VERSION "dbc-export 1 2025.20.8"

NS_ :

BS_:

BU_: ADSP APB APP APS APSB BB BMS CC CMP CMPD CP DAS DI DIF DIR DPB EPAS3P EPAS3S EPASTP EPASTS EPBL EPBR ESP GTW HVP IBST ICR IDB OCS1P ODIN PARK PCS PLG PM PMF PMR PTC RADC RCM RCM2 RCU SCCM SDCR TAS TCU TPMS TRCM UDS UI UIS UMC USM VC VCFRONT VCLEFT VCRIGHT VCSEC

BO_ 62 GTW_alertMatrix: 8 GTW
 SG_ GTW_matrixIndex M : 0|4@1+ (1,0) [0|15] "" Vector__XXX
 SG_ GTW_w001_canEthTxQueue m0 : 4|1@1+ (1,0) [0|1] "" Vector__XXX
 SG_ GTW_w002_taskError m0 : 5|1@1+ (1,0) [0|1] "" Vector__XXX
 SG_ GTW_w003_logWriteRecord m0 : 6|1@1+ (1,0) [0|1] "" Vector__XXX
 SG_ GTW_w004_mallocHook m0 : 7|1@1+ (1,0) [0|1] "" Vector__XXX
 SG_ GTW_w005_stackOverflowHook m0 : 8|1@1+ (1,0) [0|1] "" Vector__XXX
 SG_ GTW_w006_ifTxOutputFull m0 : 9|1@1+ (1,0) [0|1] "" Vector__XXX
 SG_ GTW_w007_ifRxBufError m0 : 10|1@1+ (1,0) [0|1] "" Vector__XXX
 SG_ GTW_w008_ifPbufAllocError m0 : 11|1@1+ (1,0) [0|1] "" Vector__XXX
 SG_ GTW_w009_lateTask m0 : 12|1@1+ (1,0) [0|1] "" Vector__XXX
 SG_ GTW_w010_wdTaskCount m0 : 13|1@1+ (1,0) [0|1] "" Vector__XXX
 SG_ GTW_w011_cancoreWatchdog m0 : 14|1@1+ (1,0) [0|1] "" Vector__XXX
 SG_ GTW_w012_maincoreWatchdog m0 : 15|1@1+ (1,0) [0|1] "" Vector__XXX
 SG_ GTW_w014_APSversionMismatch m0 : 17|1@1+ (1,0) [0|1] "" Vector__XXX
 SG_ GTW_w015_DIFversionMismatch m0 : 18|1@1+ (1,0) [0|1] "" Vector__XXX
 SG_ GTW_w016_BLEEPCENTERversionMisma m0 : 19|1@1+ (1,0) [0|1] "" Vector__XXX
 SG_ GTW_w017_BMSversionMismatch m0 : 20|1@1+ (1,0) [0|1] "" Vector__XXX
 SG_ GTW_w018_CMPversionMismatch m0 : 21|1@1+ (1,0) [0|1] "" Vector__XXX
 SG_ GTW_w019_CPversionMismatch m0 : 22|1@1+ (1,0) [0|1] "" Vector__XXX
 SG_ GTW_w020_DIRversionMismatch m0 : 23|1@1+ (1,0) [0|1] "" Vector__XXX
 SG_ GTW_w021_EPAS3PversionMismatch m0 : 24|1@1+ (1,0) [0|1] "" Vector__XXX
 SG_ GTW_w022_EPBLversionMismatch m0 : 25|1@1+ (1,0) [0|1] "" Vector__XXX
 SG_ GTW_w023_EPBRversionMismatch m0 : 26|1@1+ (1,0) [0|1] "" Vector__XXX
 SG_ GTW_w024_ESPversionMismatch m0 : 27|1@1+ (1,0) [0|1] "" Vector__XXX
 SG_ GTW_w025_ESPCALversionMismatch m0 : 28|1@1+ (1,0) [0|1] "" Vector__XXX
 SG_ GTW_w026_GTWversionMismatch m0 : 29|1@1+ (1,0) [0|1] "" Vector__XXX
 SG_ GTW_w027_HVPversionMismatch m0 : 30|1@1+ (1,0) [0|1] "" Vector__XXX
 SG_ GTW_w028_IBSTversionMismatch m0 : 31|1@1+ (1,0) [0|1] "" Vector__XXX
 SG_ GTW_w029_IBSTCALversionMismatch m0 : 32|1@1+ (1,0) [0|1] "" Vector__XXX
 SG_ GTW_w030_OCS1PversionMismatch m0 : 33|1@1+ (1,0) [0|1] "" Vector__XXX
 SG_ GTW_w031_PARKversionMismatch m0 : 34|1@1+ (1,0) [0|1] "" Vector__XXX
 SG_ GTW_w032_PCSversionMismatch m0 : 35|1@1+ (1,0) [0|1] "" Vector__XXX
 SG_ GTW_w033_PCSCPU2versionMismatch m0 : 36|1@1+ (1,0) [0|1] "" Vector__XXX
 SG_ GTW_w034_PMRversionMismatch m0 : 37|1@1+ (1,0) [0|1] "" Vector__XXX
 SG_ GTW_w035_PMFversionMismatch m0 : 38|1@1+ (1,0) [0|1] "" Vector__XXX
 SG_ GTW_w036_PTCversionMismatch m0 : 39|1@1+ (1,0) [0|1] "" Vector__XXX
 SG_ GTW_w037_RADCversionMismatch m0 : 40|1@1+ (1,0) [0|1] "" Vector__XXX
 SG_ GTW_w038_RCMversionMismatch m0 : 41|1@1+ (1,0) [0|1] "" Vector__XXX
 SG_ GTW_w039_RCMCALversionMismatch m0 : 42|1@1+ (1,0) [0|1] "" Vector__XXX
 SG_ GTW_w040_SCCMversionMismatch m0 : 43|1@1+ (1,0) [0|1] "" Vector__XXX
 SG_ GTW_w041_VCSECversionMismatch m0 : 44|1@1+ (1,0) [0|1] "" Vector__XXX
 SG_ GTW_w042_TASversionMismatch m0 : 45|1@1+ (1,0) [0|1] "" Vector__XXX
 SG_ GTW_w043_THSversionMismatch m0 : 46|1@1+ (1,0) [0|1] "" Vector__XXX
 SG_ GTW_w045_VCFRONTversionMismatch m0 : 48|1@1+ (1,0) [0|1] "" Vector__XXX
 SG_ GTW_w046_VCLEFTversionMismatch m0 : 49|1@1+ (1,0) [0|1] "" Vector__XXX
 SG_ GTW_w047_VCRIGHTversionMismatch m0 : 50|1@1+ (1,0) [0|1] "" Vector__XXX
 SG_ GTW_w048_EPAS3SversionMismatch m0 : 51|1@1+ (1,0) [0|1] "" Vector__XXX
 SG_ GTW_w049_corruptedManifest m0 : 52|1@1+ (1,0) [0|1] "" Vector__XXX
 SG_ GTW_w050_sdCardInitFailure m0 : 53|1@1+ (1,0) [0|1] "" Vector__XXX
 SG_ GTW_w051_sdCardFileSystemFailure m0 : 54|1@1+ (1,0) [0|1] "" Vector__XXX
 SG_ GTW_w052_ifTxSpans m0 : 55|1@1+ (1,0) [0|1] "" Vector__XXX
 SG_ GTW_w053_busSleepFailure m0 : 56|1@1+ (1,0) [0|1] "" Vector__XXX
 SG_ GTW_w054_OPCRversionMismatch m0 : 57|1@1+ (1,0) [0|1] "" Vector__XXX
 SG_ GTW_w055_OPCFversionMismatch m0 : 58|1@1+ (1,0) [0|1] "" Vector__XXX
 SG_ GTW_w057_i2cFailure m0 : 60|1@1+ (1,0) [0|1] "" Vector__XXX
 SG_ GTW_w058_rtcAlarmFailure m0 : 61|1@1+ (1,0) [0|1] "" Vector__XXX
 SG_ GTW_w059_inFactoryMode m0 : 62|1@1+ (1,0) [0|1] "" Vector__XXX
 SG_ GTW_w060_unFused m0 : 63|1@1+ (1,0) [0|1] "" Vector__XXX
 SG_ GTW_w061_bmpSleepFailure m1 : 4|1@1+ (1,0) [0|1] "" Vector__XXX
 SG_ GTW_w062_bmpWatchdog m1 : 5|1@1+ (1,0) [0|1] "" Vector__XXX
 SG_ GTW_w063_VEH_canFault m1 : 6|1@1+ (1,0) [0|1] "" Vector__XXX
 SG_ GTW_w064_CH_canFault m1 : 7|1@1+ (1,0) [0|1] "" Vector__XXX
 SG_ GTW_w065_PARTY_canFault m1 : 8|1@1+ (1,0) [0|1] "" Vector__XXX
 SG_ GTW_w066_exception m1 : 9|1@1+ (1,0) [0|1] "" Vector__XXX
 SG_ GTW_w067_tcpDebug m1 : 10|1@1+ (1,0) [0|1] "" Vector__XXX
 SG_ GTW_w068_prodKeyMissing m1 : 11|1@1+ (1,0) [0|1] "" Vector__XXX
 SG_ GTW_w069_diskioErr m1 : 12|1@1+ (1,0) [0|1] "" Vector__XXX
 SG_ GTW_w070_hrlDump m1 : 13|1@1+ (1,0) [0|1] "" Vector__XXX
 SG_ GTW_w071_hrlTrigger m1 : 14|1@1+ (1,0) [0|1] "" Vector__XXX
 SG_ GTW_w072_updateFailure m1 : 15|1@1+ (1,0) [0|1] "" Vector__XXX
 SG_ GTW_w073_steeringWheelReset m1 : 16|1@1+ (1,0) [0|1] "" Vector__XXX
 SG_ GTW_w074_epas3pMIA m1 : 17|1@1+ (1,0) [0|1] "" Vector__XXX
 SG_ GTW_w075_epas3sMIA m1 : 18|1@1+ (1,0) [0|1] "" Vector__XXX
 SG_ GTW_w076_ethInterfaceReset m1 : 19|1@1+ (1,0) [0|1] "" Vector__XXX
 SG_ GTW_w077_bmpPmicError m1 : 20|1@1+ (1,0) [0|1] "" Vector__XXX
 SG_ GTW_w078_VEHbusOverloaded m1 : 21|1@1+ (1,0) [0|1] "" Vector__XXX
 SG_ GTW_w079_PARTYbusOverloaded m1 : 22|1@1+ (1,0) [0|1] "" Vector__XXX
 SG_ GTW_w080_CHbusOverloaded m1 : 23|1@1+ (1,0) [0|1] "" Vector__XXX
 SG_ GTW_w081_udsMessageRejected m1 : 24|1@1+ (1,0) [0|1] "" Vector__XXX
 SG_ GTW_w082_sdCardBSCorrupted m1 : 25|1@1+ (1,0) [0|1] "" Vector__XXX
 SG_ GTW_w083_udsMsgDroppedByTcpStack m1 : 26|1@1+ (1,0) [0|1] "" Vector__XXX
 SG_ GTW_w084_canFrameDropped m1 : 27|1@1+ (1,0) [0|1] "" Vector__XXX
 SG_ GTW_w086_ocu m1 : 29|1@1+ (1,0) [0|1] "" Vector__XXX
 SG_ GTW_w087_ocuInProgress m1 : 30|1@1+ (1,0) [0|1] "" Vector__XXX
 SG_ GTW_w088_sdCardInvReqParallel m1 : 31|1@1+ (1,0) [0|1] "" Vector__XXX
 SG_ GTW_w089_sdCardWatchdog m1 : 32|1@1+ (1,0) [0|1] "" Vector__XXX
 SG_ GTW_w090_ocuFailed m1 : 33|1@1+ (1,0) [0|1] "" Vector__XXX
 SG_ GTW_w091_lowStack m1 : 34|1@1+ (1,0) [0|1] "" Vector__XXX
 SG_ GTW_w092_sdCardInvReqZero m1 : 35|1@1+ (1,0) [0|1] "" Vector__XXX
 SG_ GTW_w093_sdCardInvReqOverflowBas m1 : 36|1@1+ (1,0) [0|1] "" Vector__XXX
 SG_ GTW_w094_sdCardInvReqOverflowCou m1 : 37|1@1+ (1,0) [0|1] "" Vector__XXX
 SG_ GTW_w095_sdCardFull m1 : 38|1@1+ (1,0) [0|1] "" Vector__XXX
 SG_ GTW_w096_sdCardFatCorrupted m1 : 39|1@1+ (1,0) [0|1] "" Vector__XXX
 SG_ GTW_w097_HCMLversionMismatch m1 : 40|1@1+ (1,0) [0|1] "" Vector__XXX
 SG_ GTW_w098_HCMRversionMismatch m1 : 41|1@1+ (1,0) [0|1] "" Vector__XXX
 SG_ GTW_w099_SWCversionMismatch m1 : 42|1@1+ (1,0) [0|1] "" Vector__XXX
 SG_ GTW_w100_CBCversionMismatch m1 : 43|1@1+ (1,0) [0|1] "" Vector__XXX
 SG_ GTW_w101_switchWatchdog m1 : 44|1@1+ (1,0) [0|1] "" Vector__XXX
 SG_ GTW_w103_sdCardFormatted m1 : 46|1@1+ (1,0) [0|1] "" Vector__XXX
 SG_ GTW_w104_sdCardDriverArgCorrupte m1 : 47|1@1+ (1,0) [0|1] "" Vector__XXX
 SG_ GTW_w105_eBuckConfigured m1 : 48|1@1+ (1,0) [0|1] "" Vector__XXX
 SG_ GTW_w106_BLEEPLEFTversionMismatc m1 : 49|1@1+ (1,0) [0|1] "" Vector__XXX
 SG_ GTW_w107_BLEEPRIGHTversionMismat m1 : 50|1@1+ (1,0) [0|1] "" Vector__XXX
 SG_ GTW_w108_BLEEPREARversionMismatc m1 : 51|1@1+ (1,0) [0|1] "" Vector__XXX
 SG_ GTW_w109_failedToStartUpdater m1 : 52|1@1+ (1,0) [0|1] "" Vector__XXX
 SG_ GTW_w110_readMdioFailed m1 : 53|1@1+ (1,0) [0|1] "" Vector__XXX
 SG_ GTW_w111_writeMdioFailed m1 : 54|1@1+ (1,0) [0|1] "" Vector__XXX
 SG_ GTW_w112_z4bDisabled m1 : 55|1@1+ (1,0) [0|1] "" Vector__XXX
 SG_ GTW_w113_unrecognizedCanMessage m1 : 56|1@1+ (1,0) [0|1] "" Vector__XXX
 SG_ GTW_w114_updtRetried m1 : 57|1@1+ (1,0) [0|1] "" Vector__XXX
 SG_ GTW_w115_hrlEventFileAvail m1 : 58|1@1+ (1,0) [0|1] "" Vector__XXX
 SG_ GTW_w116_switchInitFailed m1 : 59|1@1+ (1,0) [0|1] "" Vector__XXX
 SG_ GTW_w117_unexpectedDestructiveRe m1 : 60|1@1+ (1,0) [0|1] "" Vector__XXX
 SG_ GTW_w118_unexpectedFunctionalRes m1 : 61|1@1+ (1,0) [0|1] "" Vector__XXX
 SG_ GTW_w120_switchUnlocked m1 : 63|1@1+ (1,0) [0|1] "" Vector__XXX
 SG_ GTW_w122_BDY_canFault m2 : 5|1@1+ (1,0) [0|1] "" Vector__XXX
 SG_ GTW_w123_BDYbusOverloaded m2 : 6|1@1+ (1,0) [0|1] "" Vector__XXX
 SG_ GTW_w125_switchReplayUnlocked m2 : 8|1@1+ (1,0) [0|1] "" Vector__XXX
 SG_ GTW_w127_noFilePointersAvailable m2 : 10|1@1+ (1,0) [0|1] "" Vector__XXX
 SG_ GTW_w129_ICRversionMismatch m2 : 12|1@1+ (1,0) [0|1] "" Vector__XXX
 SG_ GTW_w133_adspFaultDetected m2 : 16|1@1+ (1,0) [0|1] "" Vector__XXX
 SG_ GTW_w134_disableFeatureFailed m2 : 17|1@1+ (1,0) [0|1] "" Vector__XXX
 SG_ GTW_w135_canLogQueueFull m2 : 18|1@1+ (1,0) [0|1] "" Vector__XXX
 SG_ GTW_w136_hrlGameModeFileAvail m2 : 19|1@1+ (1,0) [0|1] "" Vector__XXX
 SG_ GTW_w137_lowHeap m2 : 20|1@1+ (1,0) [0|1] "" Vector__XXX
 SG_ GTW_w138_sdCardEndOfLife m2 : 21|1@1+ (1,0) [0|1] "" Vector__XXX
 SG_ GTW_w139_CMPDversionMismatch m2 : 22|1@1+ (1,0) [0|1] "" Vector__XXX
 SG_ GTW_w140_cancoreHeartbeat m2 : 23|1@1+ (1,0) [0|1] "" Vector__XXX
 SG_ GTW_w141_teleCANETHis m2 : 24|1@1+ (1,0) [0|1] "" Vector__XXX
 SG_ GTW_w143_possibleCanWakeIssue m2 : 26|1@1+ (1,0) [0|1] "" Vector__XXX
 SG_ GTW_w144_hrlStateMachine m2 : 27|1@1+ (1,0) [0|1] "" Vector__XXX
 SG_ GTW_w145_carConfigsNotWritten m2 : 28|1@1+ (1,0) [0|1] "" Vector__XXX
 SG_ GTW_w146_performancePackageMisma m2 : 29|1@1+ (1,0) [0|1] "" Vector__XXX
 SG_ GTW_w147_updateAbortFor12v m2 : 30|1@1+ (1,0) [0|1] "" Vector__XXX
 SG_ GTW_w149_rtcTimeSetInPast m2 : 32|1@1+ (1,0) [0|1] "" Vector__XXX
 SG_ GTW_w150_HCM3LversionMismatch m2 : 33|1@1+ (1,0) [0|1] "" Vector__XXX
 SG_ GTW_w151_HCM3RversionMismatch m2 : 34|1@1+ (1,0) [0|1] "" Vector__XXX
 SG_ GTW_w153_externalRtcAlarmFailure m2 : 36|1@1+ (1,0) [0|1] "" Vector__XXX
 SG_ GTW_w155_PMversionMismatch m2 : 38|1@1+ (1,0) [0|1] "" Vector__XXX
 SG_ GTW_w165_USMversionMismatch m2 : 48|1@1+ (1,0) [0|1] "" Vector__XXX
 SG_ GTW_w166_nErrCanFaultVeh m2 : 49|1@1+ (1,0) [0|1] "" Vector__XXX
 SG_ GTW_w167_nErrCanFaultCh m2 : 50|1@1+ (1,0) [0|1] "" Vector__XXX
 SG_ GTW_w168_nErrCanFaultParty m2 : 51|1@1+ (1,0) [0|1] "" Vector__XXX
 SG_ GTW_w169_TPMSsoftWarnFrontLeft m2 : 52|1@1+ (1,0) [0|1] "" Vector__XXX
 SG_ GTW_w170_TPMSsoftWarnFrontRight m2 : 53|1@1+ (1,0) [0|1] "" Vector__XXX
 SG_ GTW_w171_TPMSsoftWarnRearLeft m2 : 54|1@1+ (1,0) [0|1] "" Vector__XXX
 SG_ GTW_w172_TPMSsoftWarnRearRight m2 : 55|1@1+ (1,0) [0|1] "" Vector__XXX
 SG_ GTW_w173_TPMShardWarnFrontLeft m2 : 56|1@1+ (1,0) [0|1] "" Vector__XXX
 SG_ GTW_w174_TPMShardWarnFrontRight m2 : 57|1@1+ (1,0) [0|1] "" Vector__XXX
 SG_ GTW_w175_TPMShardWarnRearLeft m2 : 58|1@1+ (1,0) [0|1] "" Vector__XXX
 SG_ GTW_w176_TPMShardWarnRearRight m2 : 59|1@1+ (1,0) [0|1] "" Vector__XXX
 SG_ GTW_w186_swrPrecaution m3 : 9|1@1+ (1,0) [0|1] "" Vector__XXX
 SG_ GTW_w218_switchOTPIncorrect m3 : 41|1@1+ (1,0) [0|1] "" Vector__XXX
 SG_ GTW_w219_CMPSversionMismatch m3 : 42|1@1+ (1,0) [0|1] "" Vector__XXX
 SG_ GTW_w223_LVBMSversionMismatch m3 : 46|1@1+ (1,0) [0|1] "" Vector__XXX
 SG_ GTW_w224_sdCardUpgradeNeeded m3 : 47|1@1+ (1,0) [0|1] "" Vector__XXX
 SG_ GTW_w225_resetOnSleepWake m3 : 48|1@1+ (1,0) [0|1] "" Vector__XXX
 SG_ GTW_w226_DISPversionMismatch m3 : 49|1@1+ (1,0) [0|1] "" Vector__XXX
 SG_ GTW_w227_DISPTOUCHversionMismatc m3 : 50|1@1+ (1,0) [0|1] "" Vector__XXX
 SG_ GTW_w228_DISPOSDversionMismatch m3 : 51|1@1+ (1,0) [0|1] "" Vector__XXX
 SG_ GTW_w229_displaySoftsetConnectio m3 : 52|1@1+ (1,0) [0|1] "" Vector__XXX
 SG_ GTW_w230_touchInterruptStorm m3 : 53|1@1+ (1,0) [0|1] "" Vector__XXX
 SG_ GTW_w244_SDCRversionMismatch m4 : 7|1@1+ (1,0) [0|1] "" Vector__XXX
 SG_ GTW_w245_apsNotDisabled m4 : 8|1@1+ (1,0) [0|1] "" Vector__XXX
 SG_ GTW_w246_touchcoreHeartbeat m4 : 9|1@1+ (1,0) [0|1] "" Vector__XXX
 SG_ GTW_w255_rtc32KHzWatchdog m4 : 18|1@1+ (1,0) [0|1] "" Vector__XXX
 SG_ GTW_w260_unknownPN m4 : 23|1@1+ (1,0) [0|1] "" Vector__XXX
 SG_ GTW_w261_adspWatchdog m4 : 24|1@1+ (1,0) [0|1] "" Vector__XXX
 SG_ GTW_w262_canLogBlockDropped m4 : 25|1@1+ (1,0) [0|1] "" Vector__XXX
 SG_ GTW_w263_hrlUdpFileAvail m4 : 26|1@1+ (1,0) [0|1] "" Vector__XXX
 SG_ GTW_w264_hrlPseudoFileAvail m4 : 27|1@1+ (1,0) [0|1] "" Vector__XXX
 SG_ GTW_w265_optionFlagsError m4 : 28|1@1+ (1,0) [0|1] "" Vector__XXX
 SG_ GTW_w266_dpp1MIA m4 : 29|1@1+ (1,0) [0|1] "" Vector__XXX
 SG_ GTW_w267_dpp2MIA m4 : 30|1@1+ (1,0) [0|1] "" Vector__XXX
 SG_ GTW_w268_stoMIA m4 : 31|1@1+ (1,0) [0|1] "" Vector__XXX
 SG_ GTW_w273_BLEEPREARLEFTversionMis m4 : 36|1@1+ (1,0) [0|1] "" Vector__XXX
 SG_ GTW_w274_BLEEPREARRIGHTversionMi m4 : 37|1@1+ (1,0) [0|1] "" Vector__XXX
 SG_ GTW_w275_VDDCORE_DrMOS_Fault m4 : 38|1@1+ (1,0) [0|1] "" Vector__XXX
 SG_ GTW_w276_VDDSOC_DrMOS_Fault m4 : 39|1@1+ (1,0) [0|1] "" Vector__XXX
 SG_ GTW_w277_NonRevCDrMOSMitigationF m4 : 40|1@1+ (1,0) [0|1] "" Vector__XXX
 SG_ GTW_w278_ethSwitchCongested m4 : 41|1@1+ (1,0) [0|1] "" Vector__XXX
 SG_ GTW_w279_adspRepeatedWatchdog m4 : 42|1@1+ (1,0) [0|1] "" Vector__XXX
 SG_ GTW_w280_hrlFrameDropped m4 : 43|1@1+ (1,0) [0|1] "" Vector__XXX
 SG_ GTW_w281_likelyMissedPoke m4 : 44|1@1+ (1,0) [0|1] "" Vector__XXX
 SG_ GTW_w282_tcuPhyConfigurationFail m4 : 45|1@1+ (1,0) [0|1] "" Vector__XXX
 SG_ GTW_w309_VCUSBversionMismatch m5 : 12|1@1+ (1,0) [0|1] "" Vector__XXX
 SG_ GTW_w311_canLogQueueFullBeforeFs m5 : 14|1@1+ (1,0) [0|1] "" Vector__XXX
 SG_ GTW_w312_hrlFileIncomplete m5 : 15|1@1+ (1,0) [0|1] "" Vector__XXX
 SG_ GTW_w313_OSDActive m5 : 16|1@1+ (1,0) [0|1] "" Vector__XXX
 SG_ GTW_w314_canLogBlockWriteErr m5 : 17|1@1+ (1,0) [0|1] "" Vector__XXX
 SG_ GTW_w316_sdCardChkdskRepair m5 : 19|1@1+ (1,0) [0|1] "" Vector__XXX
 SG_ GTW_w317_sdCardChkdskRepairFaile m5 : 20|1@1+ (1,0) [0|1] "" Vector__XXX
 SG_ GTW_w322_gestureUnrecognizedFrom m5 : 25|1@1+ (1,0) [0|1] "" Vector__XXX
 SG_ GTW_w323_gestureStartOutOfStrip m5 : 26|1@1+ (1,0) [0|1] "" Vector__XXX
 SG_ GTW_w328_smartShiftDisabled m5 : 31|1@1+ (1,0) [0|1] "" Vector__XXX
 SG_ GTW_w329_FOHMversionMismatch m5 : 32|1@1+ (1,0) [0|1] "" Vector__XXX
 SG_ GTW_w330_SWSLversionMismatch m5 : 33|1@1+ (1,0) [0|1] "" Vector__XXX
 SG_ GTW_w331_SWSRversionMismatch m5 : 34|1@1+ (1,0) [0|1] "" Vector__XXX
 SG_ GTW_w332_unknownDisplayPN m5 : 35|1@1+ (1,0) [0|1] "" Vector__XXX
 SG_ GTW_w334_hrlFolderSpaceLow m5 : 37|1@1+ (1,0) [0|1] "" Vector__XXX
 SG_ GTW_w336_possibleCanTxIssue m5 : 39|1@1+ (1,0) [0|1] "" Vector__XXX
 SG_ GTW_w342_VCBLDCPPversionMismatch m5 : 45|1@1+ (1,0) [0|1] "" Vector__XXX
 SG_ GTW_w348_VCBLDCFversionMismatch m5 : 51|1@1+ (1,0) [0|1] "" Vector__XXX
 SG_ GTW_w349_VCBLDCPBversionMismatch m5 : 52|1@1+ (1,0) [0|1] "" Vector__XXX
 SG_ GTW_w350_mOSDCrcCheck m5 : 53|1@1+ (1,0) [0|1] "" Vector__XXX
 SG_ GTW_w351_sOSDCrcCheck m5 : 54|1@1+ (1,0) [0|1] "" Vector__XXX
 SG_ GTW_w352_mASILStatusCheck m5 : 55|1@1+ (1,0) [0|1] "" Vector__XXX
 SG_ GTW_w353_sASILStatusCheck m5 : 56|1@1+ (1,0) [0|1] "" Vector__XXX
 SG_ GTW_w354_EPASTPversionMismatch m5 : 57|1@1+ (1,0) [0|1] "" Vector__XXX
 SG_ GTW_w355_EPASTSversionMismatch m5 : 58|1@1+ (1,0) [0|1] "" Vector__XXX
 SG_ GTW_w356_touchGPIOStatusCheck m5 : 59|1@1+ (1,0) [0|1] "" Vector__XXX
 SG_ GTW_w358_RGBIPFLversionMismatch m5 : 61|1@1+ (1,0) [0|1] "" Vector__XXX
 SG_ GTW_w359_RGBIPFRversionMismatch m5 : 62|1@1+ (1,0) [0|1] "" Vector__XXX
 SG_ GTW_w360_RGBDOORFLversionMismatc m5 : 63|1@1+ (1,0) [0|1] "" Vector__XXX
 SG_ GTW_w361_RGBDOORRLversionMismatc m6 : 4|1@1+ (1,0) [0|1] "" Vector__XXX
 SG_ GTW_w362_RGBDOORFRversionMismatc m6 : 5|1@1+ (1,0) [0|1] "" Vector__XXX
 SG_ GTW_w363_RGBDOORRRversionMismatc m6 : 6|1@1+ (1,0) [0|1] "" Vector__XXX
 SG_ GTW_w364_BLEEPCRADLEversionMisma m6 : 7|1@1+ (1,0) [0|1] "" Vector__XXX
 SG_ GTW_w366_uiGearRequestMismatch m6 : 9|1@1+ (1,0) [0|1] "" Vector__XXX
 SG_ GTW_w376_blFailedToExecBootImg m6 : 19|1@1+ (1,0) [0|1] "" Vector__XXX
 SG_ GTW_w380_DPBversionMismatch m6 : 23|1@1+ (1,0) [0|1] "" Vector__XXX
 SG_ GTW_w381_DPBCALversionMismatch m6 : 24|1@1+ (1,0) [0|1] "" Vector__XXX
 SG_ GTW_w382_IDBversionMismatch m6 : 25|1@1+ (1,0) [0|1] "" Vector__XXX
 SG_ GTW_w383_IDB1versionMismatch m6 : 26|1@1+ (1,0) [0|1] "" Vector__XXX
 SG_ GTW_w384_IDBCALversionMismatch m6 : 27|1@1+ (1,0) [0|1] "" Vector__XXX
 SG_ GTW_w385_RCUversionMismatch m6 : 28|1@1+ (1,0) [0|1] "" Vector__XXX
 SG_ GTW_w386_RCUCALversionMismatch m6 : 29|1@1+ (1,0) [0|1] "" Vector__XXX
 SG_ GTW_w387_externalRtcReadFailure m6 : 30|1@1+ (1,0) [0|1] "" Vector__XXX
 SG_ GTW_w388_adspWatchdogSkipped m6 : 31|1@1+ (1,0) [0|1] "" Vector__XXX
 SG_ GTW_w389_rcmEventDetected m6 : 32|1@1+ (1,0) [0|1] "" Vector__XXX
 SG_ GTW_w391_adspMacAddrCheckFailed m6 : 34|1@1+ (1,0) [0|1] "" Vector__XXX
 SG_ GTW_w393_osdSramCrcMismatch m6 : 36|1@1+ (1,0) [0|1] "" Vector__XXX
 SG_ GTW_w395_lwipIcmpError m6 : 38|1@1+ (1,0) [0|1] "" Vector__XXX
 SG_ GTW_w396_alreadyInReverse m6 : 39|1@1+ (1,0) [0|1] "" Vector__XXX
 SG_ GTW_w397_alreadyInDrive m6 : 40|1@1+ (1,0) [0|1] "" Vector__XXX
 SG_ GTW_w398_awakeForExtendedTime m6 : 41|1@1+ (1,0) [0|1] "" Vector__XXX
 SG_ GTW_w399_ethIfRxTcpipQueueDrop m6 : 42|1@1+ (1,0) [0|1] "" Vector__XXX
 SG_ GTW_w400_ethlSwitchOTPIncorrect m6 : 43|1@1+ (1,0) [0|1] "" Vector__XXX
 SG_ GTW_w409_unexpectedResetCause m6 : 52|1@1+ (1,0) [0|1] "" Vector__XXX
 SG_ GTW_w410_unexpectedResetCause2 m6 : 53|1@1+ (1,0) [0|1] "" Vector__XXX
 SG_ GTW_w414_socHeldInReset m6 : 57|1@1+ (1,0) [0|1] "" Vector__XXX

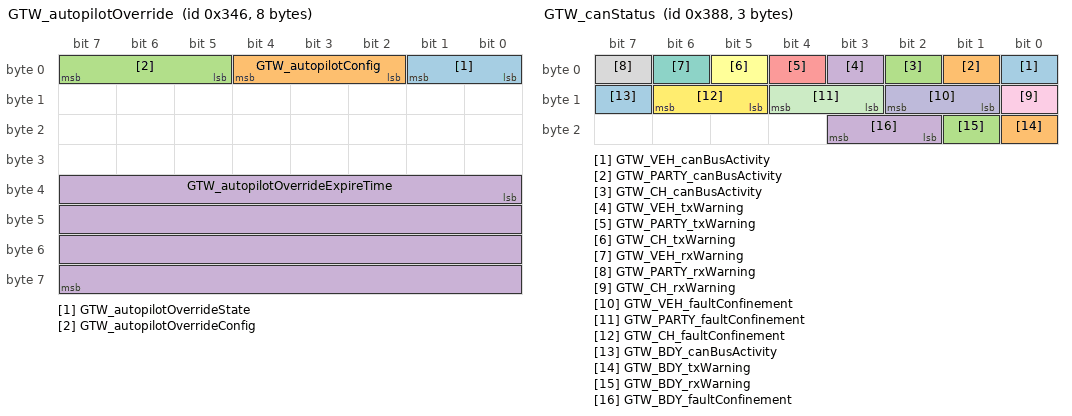
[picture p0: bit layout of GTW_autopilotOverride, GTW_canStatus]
BO_ 838 GTW_autopilotOverride: 8 GTW
 SG_ GTW_autopilotOverrideState : 0|2@1+ (1,0) [0|3] "" Vector__XXX
 SG_ GTW_autopilotConfig : 2|3@1+ (1,0) [0|7] "" Vector__XXX
 SG_ GTW_autopilotOverrideConfig : 5|3@1+ (1,0) [0|7] "" Vector__XXX
 SG_ GTW_autopilotOverrideExpireTime : 32|32@1+ (1,0) [0|4294967295] "" Vector__XXX

BO_ 904 GTW_canStatus: 3 GTW
 SG_ GTW_VEH_canBusActivity : 0|1@1+ (1,0) [0|1] "" Vector__XXX
 SG_ GTW_PARTY_canBusActivity : 1|1@1+ (1,0) [0|1] "" Vector__XXX
 SG_ GTW_CH_canBusActivity : 2|1@1+ (1,0) [0|1] "" Vector__XXX
 SG_ GTW_VEH_txWarning : 3|1@1+ (1,0) [0|1] "" Vector__XXX
 SG_ GTW_PARTY_txWarning : 4|1@1+ (1,0) [0|1] "" Vector__XXX
 SG_ GTW_CH_txWarning : 5|1@1+ (1,0) [0|1] "" Vector__XXX
 SG_ GTW_VEH_rxWarning : 6|1@1+ (1,0) [0|1] "" Vector__XXX
 SG_ GTW_PARTY_rxWarning : 7|1@1+ (1,0) [0|1] "" Vector__XXX
 SG_ GTW_CH_rxWarning : 8|1@1+ (1,0) [0|1] "" Vector__XXX
 SG_ GTW_VEH_faultConfinement : 9|2@1+ (1,0) [0|3] "" Vector__XXX
 SG_ GTW_PARTY_faultConfinement : 11|2@1+ (1,0) [0|3] "" Vector__XXX
 SG_ GTW_CH_faultConfinement : 13|2@1+ (1,0) [0|3] "" Vector__XXX
 SG_ GTW_BDY_canBusActivity : 15|1@1+ (1,0) [0|1] "" Vector__XXX
 SG_ GTW_BDY_txWarning : 16|1@1+ (1,0) [0|1] "" Vector__XXX
 SG_ GTW_BDY_rxWarning : 17|1@1+ (1,0) [0|1] "" Vector__XXX
 SG_ GTW_BDY_faultConfinement : 18|2@1+ (1,0) [0|3] "" Vector__XXX

BO_ 2047 GTW_carConfig: 8 GTW
 SG_ GTW_carConfigMultiplexer M : 0|8@1+ (1,0) [0|255] "" Vector__XXX
 SG_ GTW_deliveryStatus m1 : 8|1@1+ (1,0) [0|1] "" Vector__XXX
 SG_ GTW_cabinPTCHeaterType m1 : 10|1@1+ (1,0) [0|1] "" Vector__XXX
 SG_ GTW_rightHandDrive m1 : 11|1@1+ (1,0) [0|1] "" Vector__XXX
 SG_ GTW_rearLightType m1 : 12|2@1+ (1,0) [0|3] "" Vector__XXX
 SG_ GTW_headlamps m1 : 14|2@1+ (1,0) [0|3] "" Vector__XXX
 SG_ GTW_country m1 : 16|16@1+ (1,0) [0|65535] "" Vector__XXX
 SG_ GTW_tireType m1 : 32|6@1+ (1,0) [0|63] "" Vector__XXX
 SG_ GTW_roofGlassType m1 : 38|2@1+ (1,0) [0|3] "" Vector__XXX
 SG_ GTW_dasHw m1 : 40|3@1+ (1,0) [3|5] "" Vector__XXX
 SG_ GTW_brakeHWType m1 : 43|5@1+ (1,0) [0|31] "" Vector__XXX
 SG_ GTW_restraintsHardwareType m1 : 48|8@1+ (1,0) [0|255] "" Vector__XXX
 SG_ GTW_drivetrainType m1 : 56|4@1+ (1,0) [0|4] "" Vector__XXX
 SG_ GTW_radarHeaterType m1 : 60|3@1+ (1,0) [0|5] "" Vector__XXX
 SG_ GTW_exteriorTrimType m2 : 8|1@1+ (1,0) [0|1] "" Vector__XXX
 SG_ GTW_frontSeatHeaters m2 : 9|1@1+ (1,0) [0|1] "" Vector__XXX
 SG_ GTW_rearSeatHeaters m2 : 10|1@1+ (1,0) [0|1] "" Vector__XXX
 SG_ GTW_eCallAntennaHW m2 : 12|1@1+ (1,0) [0|1] "" Vector__XXX
 SG_ GTW_homelinkType m2 : 13|1@1+ (1,0) [0|1] "" Vector__XXX
 SG_ GTW_vdcType m2 : 14|1@1+ (1,0) [0|1] "" Vector__XXX
 SG_ GTW_memoryMirrors m2 : 17|1@1+ (1,0) [0|1] "" Vector__XXX
 SG_ GTW_powerLiftgateType m2 : 18|2@1+ (1,0) [0|2] "" Vector__XXX
 SG_ GTW_lumbarECUType m2 : 20|4@1+ (1,0) [0|15] "" Vector__XXX
 SG_ GTW_rearSeatHeaterType m2 : 24|2@1+ (1,0) [0|3] "" Vector__XXX
 SG_ GTW_auxParkLamps m2 : 26|2@1+ (1,0) [0|3] "" Vector__XXX
 SG_ GTW_interiorCabinRadarType m2 : 28|1@1+ (1,0) [0|1] "" Vector__XXX
 SG_ GTW_hvacPanelVaneType m2 : 29|1@1+ (1,0) [0|1] "" Vector__XXX
 SG_ GTW_intakeAirFilterType m2 : 30|2@1+ (1,0) [0|2] "" Vector__XXX
 SG_ GTW_eBuckConfig m2 : 32|1@1+ (1,0) [0|1] "" Vector__XXX
 SG_ GTW_steeringHeaterEnabled m2 : 33|1@1+ (1,0) [0|1] "" Vector__XXX
 SG_ GTW_activeHighBeam m2 : 34|1@1+ (1,0) [0|1] "" Vector__XXX
 SG_ GTW_airbagCutoffSwitch m2 : 35|1@1+ (1,0) [0|1] "" Vector__XXX
 SG_ GTW_intrusionSensorType m2 : 36|1@1+ (1,0) [0|1] "" Vector__XXX
 SG_ GTW_spoilerType m2 : 37|1@1+ (1,0) [0|1] "" Vector__XXX
 SG_ GTW_rearFogLamps m2 : 39|1@1+ (1,0) [0|1] "" Vector__XXX
 SG_ GTW_roofType m2 : 40|1@1+ (1,0) [0|1] "" Vector__XXX
 SG_ GTW_thirdRowSeatType m2 : 41|1@1+ (1,0) [0|1] "" Vector__XXX
 SG_ GTW_autopilot m2 : 42|3@1+ (1,0) [0|7] "" Vector__XXX
 SG_ GTW_superchargingAccess m2 : 45|2@1+ (1,0) [0|3] "" Vector__XXX
 SG_ GTW_exteriorColor m2 : 48|5@1+ (1,0) [0|31] "" Vector__XXX
 SG_ GTW_pedestrianWarningSound m2 : 53|2@1+ (1,0) [0|3] "" Vector__XXX
 SG_ GTW_steeringColumnUJointType m2 : 55|1@1+ (1,0) [0|1] "" Vector__XXX
 SG_ GTW_bPillarNFCParam m2 : 56|1@1+ (1,0) [0|1] "" Vector__XXX
 SG_ GTW_interiorLighting m2 : 57|3@1+ (1,0) [0|7] "" Vector__XXX
 SG_ GTW_headlightLevelerType m2 : 60|2@1+ (1,0) [0|3] "" Vector__XXX
 SG_ GTW_numberHVILNodes m2 : 62|2@1+ (1,0) [0|3] "" Vector__XXX
 SG_ GTW_mapRegion m3 : 8|4@1+ (1,0) [0|15] "" Vector__XXX
 SG_ GTW_performancePackage m3 : 12|3@1+ (1,0) [0|7] "" Vector__XXX
 SG_ GTW_chassisType m3 : 18|4@1+ (1,0) [0|15] "" Vector__XXX
 SG_ GTW_airSuspension m3 : 22|2@1+ (1,0) [0|3] "" Vector__XXX
 SG_ GTW_centerConsoleControllerType m3 : 24|2@1+ (1,0) [0|3] "" Vector__XXX
 SG_ GTW_autopilotCameraType m3 : 26|1@1+ (1,0) [0|1] "" Vector__XXX
 SG_ GTW_connectivityPackage m3 : 27|1@1+ (1,0) [0|1] "" Vector__XXX
 SG_ GTW_plcSupportType m3 : 28|2@1+ (1,0) [0|3] "" Vector__XXX
 SG_ GTW_packEnergy m3 : 32|5@1+ (1,0) [0|31] "" Vector__XXX
 SG_ GTW_frontSeatReclinerHardware m3 : 37|2@1+ (1,0) [0|3] "" Vector__XXX
 SG_ GTW_brakeLineSwitchType m3 : 39|1@1+ (1,0) [0|1] "" Vector__XXX
 SG_ GTW_espValveType m3 : 40|2@1+ (1,0) [0|3] "" Vector__XXX
 SG_ GTW_softRange m3 : 42|3@1+ (1,0) [0|7] "" Vector__XXX
 SG_ GTW_refrigerantType m3 : 45|2@1+ (1,0) [0|3] "" Vector__XXX
 SG_ GTW_wheelType m3 : 48|7@1+ (1,0) [0|127] "" Vector__XXX
 SG_ GTW_ptcControlMode m3 : 55|2@1+ (1,0) [0|3] "" Vector__XXX
 SG_ GTW_brakeActuationType m3 : 57|3@1+ (1,0) [0|4] "" Vector__XXX
 SG_ GTW_secondRowSeatType m3 : 60|3@1+ (1,0) [0|7] "" Vector__XXX
 SG_ GTW_secondRowSeatMotorType m3 : 63|1@1+ (1,0) [0|1] "" Vector__XXX
 SG_ GTW_birthday m4 : 8|32@1+ (1,0) [0|4294967295] "" Vector__XXX
 SG_ GTW_eCallEnabled m4 : 40|2@1+ (1,0) [0|3] "" Vector__XXX
 SG_ GTW_parkAssistECUType m4 : 42|2@1+ (1,0) [0|3] "" Vector__XXX
 SG_ GTW_passengerAirbagType m4 : 44|2@1+ (1,0) [0|3] "" Vector__XXX
 SG_ GTW_forwardRadarHw m4 : 46|2@1+ (1,0) [0|2] "" Vector__XXX
 SG_ GTW_frontSeatType m4 : 48|4@1+ (1,0) [0|15] "" Vector__XXX
 SG_ GTW_secondRowDisplayType m4 : 52|1@1+ (1,0) [0|1] "" Vector__XXX
 SG_ GTW_wirelessPhoneChargerType m4 : 53|2@1+ (1,0) [0|3] "" Vector__XXX
 SG_ GTW_ethernetTunerType m4 : 55|2@1+ (1,0) [0|3] "" Vector__XXX
 SG_ GTW_interiorTrimType m4 : 60|4@1+ (1,0) [0|15] "" Vector__XXX
 SG_ GTW_gloveboxUSBType m5 : 8|2@1+ (1,0) [0|3] "" Vector__XXX
 SG_ GTW_coolantPumpType m5 : 10|3@1+ (1,0) [0|7] "" Vector__XXX
 SG_ GTW_epblHwType m5 : 13|4@1+ (1,0) [0|15] "" Vector__XXX
 SG_ GTW_epbrHwType m5 : 17|4@1+ (1,0) [0|15] "" Vector__XXX
 SG_ GTW_blowerMotorType m5 : 21|2@1+ (1,0) [0|3] "" Vector__XXX
 SG_ GTW_rearLeftBLEEndpointParameter m5 : 23|1@1+ (1,0) [0|1] "" Vector__XXX
 SG_ GTW_frontUsbHubType m5 : 27|3@1+ (1,0) [0|5] "" Vector__XXX
 SG_ GTW_superManifoldType m5 : 30|2@1+ (1,0) [0|3] "" Vector__XXX
 SG_ GTW_rcmLocation m5 : 32|1@1+ (1,0) [0|1] "" Vector__XXX
 SG_ GTW_interiorCamFanType m5 : 33|2@1+ (1,0) [0|3] "" Vector__XXX
 SG_ GTW_interiorCamBeautyCoverType m5 : 35|2@1+ (1,0) [0|3] "" Vector__XXX
 SG_ GTW_sirenType m5 : 37|1@1+ (1,0) [0|1] "" Vector__XXX
 SG_ GTW_hornType m5 : 38|1@1+ (1,0) [0|1] "" Vector__XXX
 SG_ GTW_badgingVersion m5 : 40|1@1+ (1,0) [0|1] "" Vector__XXX
 SG_ GTW_steeringColumnMotorType m5 : 42|2@1+ (1,0) [0|3] "" Vector__XXX
 SG_ GTW_refrigACLineType m5 : 48|2@1+ (1,0) [0|3] "" Vector__XXX
 SG_ GTW_refrigFilterType m5 : 50|2@1+ (1,0) [0|3] "" Vector__XXX
 SG_ GTW_diBurnInType m5 : 52|1@1+ (1,0) [0|1] "" Vector__XXX
 SG_ GTW_specialBadgingType m5 : 53|2@1+ (1,0) [0|3] "" Vector__XXX
 SG_ GTW_chassisSubType m5 : 55|2@1+ (1,0) [0|3] "" Vector__XXX
 SG_ GTW_frontSeatVentilationType m5 : 57|1@1+ (1,0) [0|1] "" Vector__XXX
 SG_ GTW_towPackage m5 : 58|2@1+ (1,0) [0|3] "" Vector__XXX
 SG_ GTW_refrigLccType m5 : 60|1@1+ (1,0) [0|1] "" Vector__XXX
 SG_ GTW_caliperColorType m5 : 62|2@1+ (1,0) [0|3] "" Vector__XXX
 SG_ GTW_wiperMotorType m6 : 9|1@1+ (1,0) [0|1] "" Vector__XXX
 SG_ GTW_frontOverheadConsoleType m6 : 10|2@1+ (1,0) [0|3] "" Vector__XXX
 SG_ GTW_shifterType m6 : 12|1@1+ (1,0) [0|1] "" Vector__XXX
 SG_ GTW_compressorType m6 : 13|4@1+ (1,0) [0|15] "" Vector__XXX
 SG_ GTW_twelveVBatteryType m6 : 17|3@1+ (1,0) [0|7] "" Vector__XXX
 SG_ GTW_efuseSWConfig m6 : 20|3@1+ (1,0) [0|7] "" Vector__XXX
 SG_ GTW_tollCollectionModuleType m6 : 23|1@1+ (1,0) [0|1] "" Vector__XXX
 SG_ GTW_bleEndpointUpdateMethod m6 : 24|1@1+ (1,0) [0|1] "" Vector__XXX
 SG_ GTW_steeringWheelControllerType m6 : 25|3@1+ (1,0) [0|7] "" Vector__XXX
 SG_ GTW_frontSeatVentilationEnabled m6 : 28|1@1+ (1,0) [0|1] "" Vector__XXX
 SG_ GTW_gloveboxActuatorType m6 : 29|2@1+ (1,0) [0|3] "" Vector__XXX
 SG_ GTW_epasType m6 : 32|4@1+ (1,0) [0|11] "" Vector__XXX
 SG_ GTW_homologationRegionOverride m6 : 36|2@1+ (1,0) [0|3] "" Vector__XXX
 SG_ GTW_windowCommandsPermissionType m6 : 38|2@1+ (1,0) [0|3] "" Vector__XXX
 SG_ GTW_headlightStepperStallDetectM m6 : 42|1@1+ (1,0) [0|1] "" Vector__XXX
 SG_ GTW_rgbInteriorLightingEnabled m6 : 43|2@1+ (1,0) [0|3] "" Vector__XXX
 SG_ GTW_windshieldWiperHeaterType m6 : 45|1@1+ (1,0) [0|1] "" Vector__XXX
 SG_ GTW_driveInterfaceType m6 : 47|1@1+ (1,0) [0|1] "" Vector__XXX
 SG_ GTW_efficiencyPackage m6 : 49|6@1+ (1,0) [0|63] "" Vector__XXX
 SG_ GTW_visorLightType m6 : 55|1@1+ (1,0) [0|1] "" Vector__XXX
 SG_ GTW_gnssAntennaType m6 : 58|2@1+ (1,0) [0|3] "" Vector__XXX
 SG_ GTW_frontSeatHeatersEnabled m6 : 62|1@1+ (1,0) [0|1] "" Vector__XXX
 SG_ GTW_windshieldWiperHeaterEnabled m6 : 63|1@1+ (1,0) [0|1] "" Vector__XXX
 SG_ GTW_tcuType m7 : 8|1@1+ (1,0) [0|1] "" Vector__XXX
 SG_ GTW_fasciaType m7 : 9|4@1+ (1,0) [0|15] "" Vector__XXX
 SG_ GTW_powerSteeringColumn m7 : 13|1@1+ (1,0) [0|1] "" Vector__XXX
 SG_ GTW_frontSeatHeaterType m7 : 14|1@1+ (1,0) [0|1] "" Vector__XXX
 SG_ GTW_softPerformanceLimit m7 : 15|4@1+ (1,0) [0|15] "" Vector__XXX
 SG_ GTW_alcoholInterlockType m7 : 22|1@1+ (1,0) [0|1] "" Vector__XXX
 SG_ GTW_immersiveAudio m7 : 23|2@1+ (1,0) [0|3] "" Vector__XXX
 SG_ GTW_passengerOccupancySensorType m7 : 26|3@1+ (1,0) [0|7] "" Vector__XXX
 SG_ GTW_packPerformanceDeviation m7 : 30|3@1+ (1,0) [0|7] "" Vector__XXX
 SG_ GTW_frontFogLamps m7 : 35|1@1+ (1,0) [0|1] "" Vector__XXX
 SG_ GTW_driverOccupancySensorType m7 : 36|1@1+ (1,0) [0|1] "" Vector__XXX
 SG_ GTW_audioType m7 : 37|3@1+ (1,0) [0|7] "" Vector__XXX
 SG_ GTW_occupancyClassificationFeatu m7 : 42|1@1+ (1,0) [0|1] "" Vector__XXX
 SG_ GTW_domeLightType m7 : 47|2@1+ (1,0) [0|3] "" Vector__XXX
 SG_ GTW_tpmsType m7 : 49|2@1+ (1,0) [0|3] "" Vector__XXX
 SG_ GTW_authenticationEndpointLayout m7 : 52|3@1+ (1,0) [0|6] "" Vector__XXX
 SG_ GTW_socSleepOverride m7 : 57|2@1+ (1,0) [0|3] "" Vector__XXX
 SG_ GTW_r79BehaviorOverride m7 : 59|1@1+ (1,0) [0|1] "" Vector__XXX
 SG_ GTW_steeringHeaterType m7 : 60|3@1+ (1,0) [0|7] "" Vector__XXX
 SG_ GTW_sohRegulatoryStatus m8 : 10|1@1+ (1,0) [0|1] "" Vector__XXX
 SG_ GTW_m3yBusArchitecture m8 : 17|2@1+ (1,0) [0|3] "" Vector__XXX
 SG_ GTW_blindSpotIndicatorLightType m8 : 20|1@1+ (1,0) [0|1] "" Vector__XXX
 SG_ GTW_hvacCaseDoorType m8 : 28|1@1+ (1,0) [0|1] "" Vector__XXX
 SG_ GTW_occupancyDetectionSourceRequ m8 : 29|1@1+ (1,0) [0|1] "" Vector__XXX
 SG_ GTW_rduCableType m8 : 31|1@1+ (1,0) [0|1] "" Vector__XXX
 SG_ GTW_interiorCameraType m8 : 39|2@1+ (1,0) [0|2] "" Vector__XXX
 SG_ GTW_frontFasciaCameraType m8 : 41|2@1+ (1,0) [0|3] "" Vector__XXX

BO_ 792 GTW_carState: 8 GTW
 SG_ GTW_factoryGated : 48|1@1+ (1,0) [0|1] "" Vector__XXX

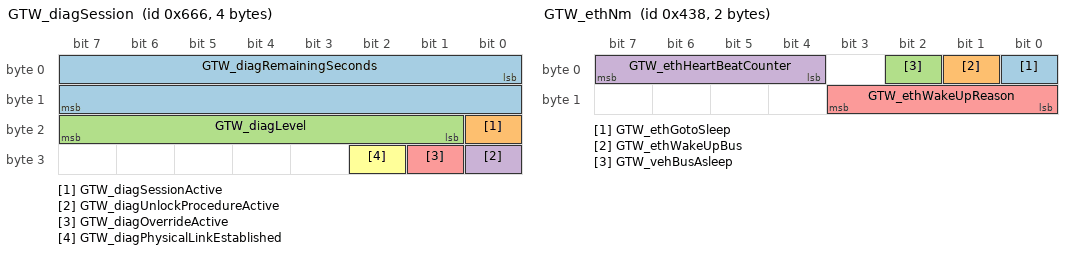
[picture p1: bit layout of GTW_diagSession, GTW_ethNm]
BO_ 1638 GTW_diagSession: 4 GTW
 SG_ GTW_diagRemainingSeconds : 0|16@1+ (1,0) [0|65535] "seconds" Vector__XXX
 SG_ GTW_diagSessionActive : 16|1@1+ (1,0) [0|1] "" Vector__XXX
 SG_ GTW_diagLevel : 17|7@1+ (1,0) [0|127] "" Vector__XXX
 SG_ GTW_diagUnlockProcedureActive : 24|1@1+ (1,0) [0|1] "" Vector__XXX
 SG_ GTW_diagOverrideActive : 25|1@1+ (1,0) [0|1] "" Vector__XXX
 SG_ GTW_diagPhysicalLinkEstablished : 26|1@1+ (1,0) [0|1] "" Vector__XXX

BO_ 1080 GTW_ethNm: 2 GTW
 SG_ GTW_ethGotoSleep : 0|1@1+ (1,0) [0|1] "" Vector__XXX
 SG_ GTW_ethWakeUpBus : 1|1@1+ (1,0) [0|1] "" Vector__XXX
 SG_ GTW_vehBusAsleep : 2|1@1+ (1,0) [0|1] "" Vector__XXX
 SG_ GTW_ethHeartBeatCounter : 4|4@1+ (1,0) [0|15] "" Vector__XXX
 SG_ GTW_ethWakeUpReason : 8|4@1+ (1,0) [0|15] "" Vector__XXX

BO_ 1376 GTW_factoryEcuPresent: 4 GTW
 SG_ GTW_OCS1Ppresent : 0|1@1+ (1,0) [0|1] "" Vector__XXX
 SG_ GTW_PCSpresent : 1|1@1+ (1,0) [0|1] "" Vector__XXX
 SG_ GTW_HVPpresent : 2|1@1+ (1,0) [0|1] "" Vector__XXX
 SG_ GTW_BMSpresent : 3|1@1+ (1,0) [0|1] "" Vector__XXX
 SG_ GTW_CPpresent : 4|1@1+ (1,0) [0|1] "" Vector__XXX
 SG_ GTW_RCMpresent : 5|1@1+ (1,0) [0|1] "" Vector__XXX
 SG_ GTW_SCCMpresent : 6|1@1+ (1,0) [0|1] "" Vector__XXX
 SG_ GTW_VCSECpresent : 7|1@1+ (1,0) [0|1] "" Vector__XXX
 SG_ GTW_EPAS3Ppresent : 8|1@1+ (1,0) [0|1] "" Vector__XXX
 SG_ GTW_EPBLpresent : 9|1@1+ (1,0) [0|1] "" Vector__XXX
 SG_ GTW_EPBRpresent : 10|1@1+ (1,0) [0|1] "" Vector__XXX
 SG_ GTW_ESPpresent : 11|1@1+ (1,0) [0|1] "" Vector__XXX
 SG_ GTW_IBSTpresent : 12|1@1+ (1,0) [0|1] "" Vector__XXX
 SG_ GTW_PARKpresent : 13|1@1+ (1,0) [0|1] "" Vector__XXX
 SG_ GTW_RADCpresent : 14|1@1+ (1,0) [0|1] "" Vector__XXX
 SG_ GTW_TPMSpresent : 15|1@1+ (1,0) [0|1] "" Vector__XXX
 SG_ GTW_VCFRONTpresent : 16|1@1+ (1,0) [0|1] "" Vector__XXX
 SG_ GTW_VCLEFTpresent : 17|1@1+ (1,0) [0|1] "" Vector__XXX
 SG_ GTW_VCRIGHTpresent : 18|1@1+ (1,0) [0|1] "" Vector__XXX
 SG_ GTW_EPAS3Spresent : 19|1@1+ (1,0) [0|1] "" Vector__XXX
 SG_ GTW_CMPpresent : 20|1@1+ (1,0) [0|1] "" Vector__XXX
 SG_ GTW_DASpresent : 21|1@1+ (1,0) [0|1] "" Vector__XXX
 SG_ GTW_PTCpresent : 22|1@1+ (1,0) [0|1] "" Vector__XXX
 SG_ GTW_SWCpresent : 23|1@1+ (1,0) [0|1] "" Vector__XXX
 SG_ GTW_PMRpresent : 25|1@1+ (1,0) [0|1] "" Vector__XXX
 SG_ GTW_PMFpresent : 26|1@1+ (1,0) [0|1] "" Vector__XXX
 SG_ GTW_DIRpresent : 27|1@1+ (1,0) [0|1] "" Vector__XXX
 SG_ GTW_DIFpresent : 28|1@1+ (1,0) [0|1] "" Vector__XXX

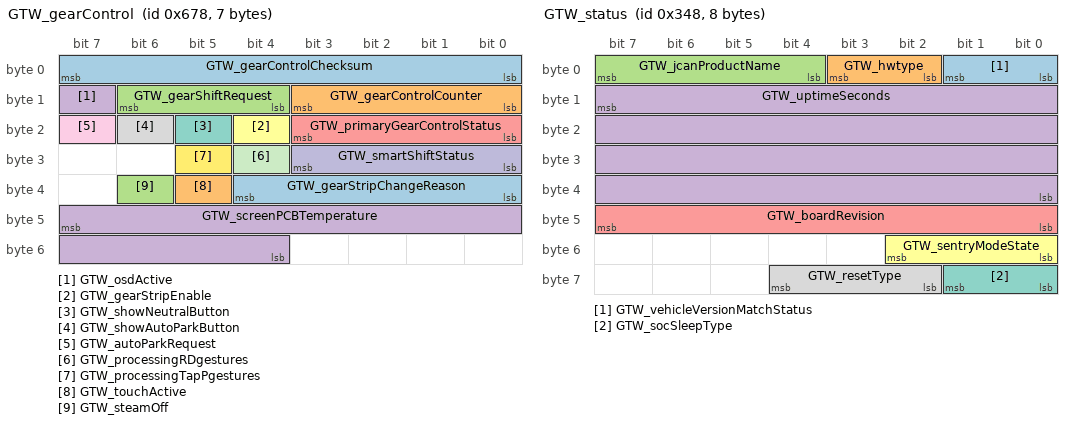
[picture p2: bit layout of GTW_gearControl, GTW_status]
BO_ 1656 GTW_gearControl: 7 GTW
 SG_ GTW_gearControlChecksum : 0|8@1+ (1,0) [0|255] "" Vector__XXX
 SG_ GTW_gearControlCounter : 8|4@1+ (1,0) [0|15] "" Vector__XXX
 SG_ GTW_gearShiftRequest : 12|3@1+ (1,0) [1|7] "" Vector__XXX
 SG_ GTW_osdActive : 15|1@1+ (1,0) [0|1] "" Vector__XXX
 SG_ GTW_primaryGearControlStatus : 16|4@1+ (1,0) [0|15] "" Vector__XXX
 SG_ GTW_gearStripEnable : 20|1@1+ (1,0) [0|1] "" Vector__XXX
 SG_ GTW_showNeutralButton : 21|1@1+ (1,0) [0|1] "" Vector__XXX
 SG_ GTW_showAutoParkButton : 22|1@1+ (1,0) [0|1] "" Vector__XXX
 SG_ GTW_autoParkRequest : 23|1@1+ (1,0) [0|1] "" Vector__XXX
 SG_ GTW_smartShiftStatus : 24|4@1+ (1,0) [1|15] "" Vector__XXX
 SG_ GTW_processingRDgestures : 28|1@1+ (1,0) [0|1] "" Vector__XXX
 SG_ GTW_processingTapPgestures : 29|1@1+ (1,0) [0|1] "" Vector__XXX
 SG_ GTW_gearStripChangeReason : 32|5@1+ (1,0) [1|31] "" Vector__XXX
 SG_ GTW_touchActive : 37|1@1+ (1,0) [0|1] "" Vector__XXX
 SG_ GTW_steamOff : 38|1@1+ (1,0) [0|1] "" Vector__XXX
 SG_ GTW_screenPCBTemperature : 47|12@0- (0.0625,0) [-128|127.875] "degC" Vector__XXX

BO_ 2033 GTW_hrl: 7 GTW
 SG_ GTW_hrlIndex M : 0|2@1+ (1,0) [0|3] "" Vector__XXX
 SG_ GTW_hrlState m2 : 2|1@1+ (1,0) [0|1] "" Vector__XXX
 SG_ GTW_hrlTriggerDuration m2 : 15|16@0+ (1,0) [0|65535] "seconds" Vector__XXX
 SG_ GTW_hrlTriggerType m2 : 24|4@1+ (1,0) [0|15] "" Vector__XXX
 SG_ GTW_hrlTriggerId m2 : 39|16@0+ (1,0) [0|65535] "" Vector__XXX
 SG_ GTW_hrlTriggerBus m2 : 53|3@1+ (1,0) [0|7] "" Vector__XXX

BO_ 60 GTW_info: 8 GTW
 SG_ GTW_infoIndex M : 0|8@1+ (1,0) [0|255] "" Vector__XXX
 SG_ GTW_buildType m10 : 8|3@1+ (1,0) [0|7] "" Vector__XXX
 SG_ GTW_hardwareId m10 : 32|16@1+ (1,0) [0|65535] "" Vector__XXX
 SG_ GTW_platformType m13 : 8|8@1+ (1,0) [0|255] "" Vector__XXX
 SG_ GTW_appCrc m13 : 32|32@1+ (1,0) [0|4294967295] "" Vector__XXX
 SG_ GTW_applicationGitHash m17 : 8|56@1+ (1,0) [0|7.20575940379e+16] "" Vector__XXX
 SG_ GTW_bootGitHash m18 : 8|56@1+ (1,0) [0|7.20575940379e+16] "" Vector__XXX

BO_ 1370 GTW_mismatchFault: 8 GTW
 SG_ GTW_mismatchFaultIndex M : 0|3@1+ (1,0) [0|7] "" Vector__XXX
 SG_ GTW_mismatchFaultChecksum : 3|8@1+ (1,0) [0|255] "" Vector__XXX
 SG_ GTW_mismatchFaultCounter : 11|4@1+ (1,0) [0|15] "" Vector__XXX
 SG_ GTW_GTWmismatchFault m1 : 15|1@1+ (1,0) [0|1] "" Vector__XXX
 SG_ GTW_BMSmismatchFault m1 : 16|1@1+ (1,0) [0|1] "" Vector__XXX
 SG_ GTW_APSmismatchFault m1 : 17|1@1+ (1,0) [0|1] "" Vector__XXX
 SG_ GTW_BLEEPCENTERmismatchFault m1 : 18|1@1+ (1,0) [0|1] "" Vector__XXX
 SG_ GTW_BLEEPLEFTmismatchFault m1 : 19|1@1+ (1,0) [0|1] "" Vector__XXX
 SG_ GTW_BLEEPREARmismatchFault m1 : 20|1@1+ (1,0) [0|1] "" Vector__XXX
 SG_ GTW_BLEEPRIGHTmismatchFault m1 : 21|1@1+ (1,0) [0|1] "" Vector__XXX
 SG_ GTW_CBCmismatchFault m1 : 22|1@1+ (1,0) [0|1] "" Vector__XXX
 SG_ GTW_CMPmismatchFault m1 : 23|1@1+ (1,0) [0|1] "" Vector__XXX
 SG_ GTW_CPmismatchFault m1 : 24|1@1+ (1,0) [0|1] "" Vector__XXX
 SG_ GTW_DIFmismatchFault m1 : 25|1@1+ (1,0) [0|1] "" Vector__XXX
 SG_ GTW_DIRmismatchFault m1 : 26|1@1+ (1,0) [0|1] "" Vector__XXX
 SG_ GTW_EPAS3PmismatchFault m1 : 27|1@1+ (1,0) [0|1] "" Vector__XXX
 SG_ GTW_EPAS3SmismatchFault m1 : 28|1@1+ (1,0) [0|1] "" Vector__XXX
 SG_ GTW_EPBLmismatchFault m1 : 29|1@1+ (1,0) [0|1] "" Vector__XXX
 SG_ GTW_EPBRmismatchFault m1 : 30|1@1+ (1,0) [0|1] "" Vector__XXX
 SG_ GTW_ESPCALmismatchFault m1 : 31|1@1+ (1,0) [0|1] "" Vector__XXX
 SG_ GTW_ESPmismatchFault m1 : 32|1@1+ (1,0) [0|1] "" Vector__XXX
 SG_ GTW_HCM3LmismatchFault m1 : 33|1@1+ (1,0) [0|1] "" Vector__XXX
 SG_ GTW_HCM3RmismatchFault m1 : 34|1@1+ (1,0) [0|1] "" Vector__XXX
 SG_ GTW_HCMLmismatchFault m1 : 35|1@1+ (1,0) [0|1] "" Vector__XXX
 SG_ GTW_HCMRmismatchFault m1 : 36|1@1+ (1,0) [0|1] "" Vector__XXX
 SG_ GTW_HVPmismatchFault m1 : 37|1@1+ (1,0) [0|1] "" Vector__XXX
 SG_ GTW_IBSTCALmismatchFault m1 : 38|1@1+ (1,0) [0|1] "" Vector__XXX
 SG_ GTW_IBSTmismatchFault m1 : 39|1@1+ (1,0) [0|1] "" Vector__XXX
 SG_ GTW_LVBMSmismatchFault m1 : 40|1@1+ (1,0) [0|1] "" Vector__XXX
 SG_ GTW_OCS1PmismatchFault m1 : 41|1@1+ (1,0) [0|1] "" Vector__XXX
 SG_ GTW_OPCFmismatchFault m1 : 42|1@1+ (1,0) [0|1] "" Vector__XXX
 SG_ GTW_OPCRmismatchFault m1 : 43|1@1+ (1,0) [0|1] "" Vector__XXX
 SG_ GTW_PARKmismatchFault m1 : 44|1@1+ (1,0) [0|1] "" Vector__XXX
 SG_ GTW_PCSCPU2mismatchFault m1 : 45|1@1+ (1,0) [0|1] "" Vector__XXX
 SG_ GTW_PCSmismatchFault m1 : 46|1@1+ (1,0) [0|1] "" Vector__XXX
 SG_ GTW_PMFmismatchFault m1 : 47|1@1+ (1,0) [0|1] "" Vector__XXX
 SG_ GTW_PMRmismatchFault m1 : 48|1@1+ (1,0) [0|1] "" Vector__XXX
 SG_ GTW_PTCmismatchFault m1 : 49|1@1+ (1,0) [0|1] "" Vector__XXX
 SG_ GTW_RCMCALmismatchFault m1 : 50|1@1+ (1,0) [0|1] "" Vector__XXX
 SG_ GTW_RCMmismatchFault m1 : 51|1@1+ (1,0) [0|1] "" Vector__XXX
 SG_ GTW_SCCMmismatchFault m1 : 52|1@1+ (1,0) [0|1] "" Vector__XXX
 SG_ GTW_SDCRmismatchFault m1 : 53|1@1+ (1,0) [0|1] "" Vector__XXX
 SG_ GTW_SWCmismatchFault m1 : 54|1@1+ (1,0) [0|1] "" Vector__XXX
 SG_ GTW_THSmismatchFault m1 : 55|1@1+ (1,0) [0|1] "" Vector__XXX
 SG_ GTW_VCFRONTmismatchFault m1 : 56|1@1+ (1,0) [0|1] "" Vector__XXX
 SG_ GTW_VCLEFTmismatchFault m1 : 57|1@1+ (1,0) [0|1] "" Vector__XXX
 SG_ GTW_VCRIGHTmismatchFault m1 : 58|1@1+ (1,0) [0|1] "" Vector__XXX
 SG_ GTW_VCSECmismatchFault m1 : 59|1@1+ (1,0) [0|1] "" Vector__XXX
 SG_ GTW_PMmismatchFault m1 : 60|1@1+ (1,0) [0|1] "" Vector__XXX

BO_ 840 GTW_status: 8 GTW
 SG_ GTW_vehicleVersionMatchStatus : 0|2@1+ (1,0) [0|3] "" Vector__XXX
 SG_ GTW_hwtype : 2|2@1+ (1,0) [1|3] "" Vector__XXX
 SG_ GTW_jcanProductName : 4|4@1+ (1,0) [1|15] "" Vector__XXX
 SG_ GTW_uptimeSeconds : 15|32@0+ (1,0) [0|4294967295] "s" Vector__XXX
 SG_ GTW_boardRevision : 40|8@1+ (1,0) [0|255] "" Vector__XXX
 SG_ GTW_sentryModeState : 48|3@1+ (1,0) [0|7] "" Vector__XXX
 SG_ GTW_socSleepType : 56|2@1+ (1,0) [1|3] "" Vector__XXX
 SG_ GTW_resetType : 58|3@1+ (1,0) [1|7] "" Vector__XXX

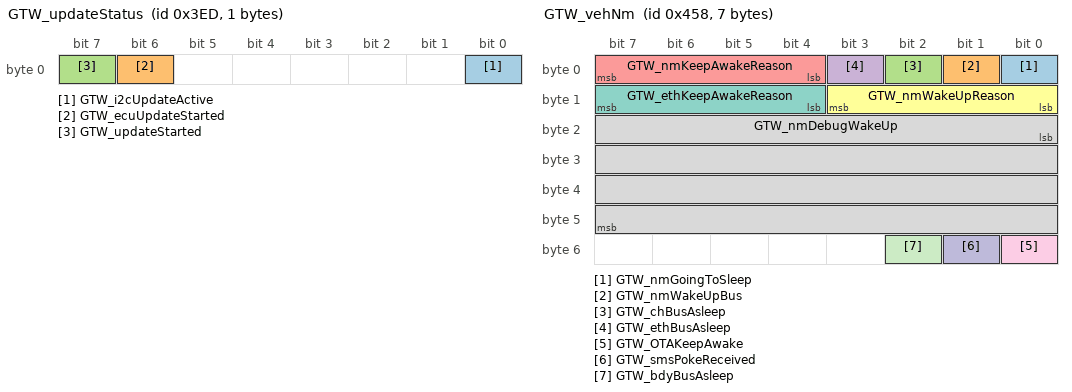
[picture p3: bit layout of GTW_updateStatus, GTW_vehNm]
BO_ 1005 GTW_updateStatus: 1 GTW
 SG_ GTW_i2cUpdateActive : 0|1@1+ (1,0) [0|1] "" Vector__XXX
 SG_ GTW_ecuUpdateStarted : 6|1@1+ (1,0) [0|1] "" Vector__XXX
 SG_ GTW_updateStarted : 7|1@1+ (1,0) [0|1] "" Vector__XXX

BO_ 1112 GTW_vehNm: 7 GTW
 SG_ GTW_nmGoingToSleep : 0|1@1+ (1,0) [0|1] "" Vector__XXX
 SG_ GTW_nmWakeUpBus : 1|1@1+ (1,0) [0|1] "" Vector__XXX
 SG_ GTW_chBusAsleep : 2|1@1+ (1,0) [0|1] "" Vector__XXX
 SG_ GTW_ethBusAsleep : 3|1@1+ (1,0) [0|1] "" Vector__XXX
 SG_ GTW_nmKeepAwakeReason : 4|4@1+ (1,0) [1|15] "" Vector__XXX
 SG_ GTW_nmWakeUpReason : 8|4@1+ (1,0) [0|15] "" Vector__XXX
 SG_ GTW_ethKeepAwakeReason : 12|4@1+ (1,0) [1|15] "" Vector__XXX
 SG_ GTW_nmDebugWakeUp : 16|32@1+ (1,0) [0|4294967295] "" Vector__XXX
 SG_ GTW_OTAKeepAwake : 48|1@1+ (1,0) [0|1] "" Vector__XXX
 SG_ GTW_smsPokeReceived : 49|1@1+ (1,0) [0|1] "" Vector__XXX
 SG_ GTW_bdyBusAsleep : 50|1@1+ (1,0) [0|1] "" Vector__XXX

BO_ 1290 HVP_alertLog: 8 HVP
 SG_ HVP_alertID M : 0|7@1+ (1,0) [0|127] "" Vector__XXX
 SG_ HVP_alertSet : 15|1@1+ (1,0) [0|1] "" Vector__XXX
 SG_ HVP_a005_current m5 : 16|24@1- (0.001,0) [-8388.608|8388.607] "A" Vector__XXX
 SG_ HVP_a006_current m6 : 16|24@1- (0.001,0) [-8388.608|8388.607] "A" Vector__XXX
 SG_ HVP_a007_current m7 : 16|24@1- (0.001,0) [-8388.608|8388.607] "A" Vector__XXX
 SG_ HVP_a008_temperature m8 : 16|16@1- (0.01,0) [-327.68|327.67] "C" Vector__XXX
 SG_ HVP_a008_sensorId m8 : 32|6@1+ (1,1) [1|64] "" Vector__XXX
 SG_ HVP_a008_primaryChainSensor m8 : 38|1@1+ (1,0) [0|1] "" Vector__XXX
 SG_ HVP_a009_brickVoltage m9 : 16|16@1- (0.001,0) [-32.768|32.767] "V" Vector__XXX
 SG_ HVP_a009_brickId m9 : 32|7@1+ (1,1) [1|128] "" Vector__XXX
 SG_ HVP_a009_primaryChainSensor m9 : 39|1@1+ (1,0) [0|1] "" Vector__XXX
 SG_ HVP_a010_brickVoltage m10 : 16|16@1- (0.001,0) [-32.768|32.767] "V" Vector__XXX
 SG_ HVP_a010_brickId m10 : 32|7@1+ (1,1) [1|128] "" Vector__XXX
 SG_ HVP_a010_primaryChainSensor m10 : 39|1@1+ (1,0) [0|1] "" Vector__XXX
 SG_ HVP_a012_breakLocationA m12 : 16|5@1+ (1,0) [0|31] "" Vector__XXX
 SG_ HVP_a012_bmbCommStatusTypeA m12 : 21|2@1+ (1,0) [0|3] "" Vector__XXX
 SG_ HVP_a012_breakLocationB m12 : 24|5@1+ (1,0) [0|31] "" Vector__XXX
 SG_ HVP_a012_bmbCommStatusTypeB m12 : 29|2@1+ (1,0) [0|3] "" Vector__XXX
 SG_ HVP_a013_breakLocationA m13 : 16|5@1+ (1,0) [0|31] "" Vector__XXX
 SG_ HVP_a013_bmbCommStatusTypeA m13 : 21|2@1+ (1,0) [0|3] "" Vector__XXX
 SG_ HVP_a013_breakLocationB m13 : 24|5@1+ (1,0) [0|31] "" Vector__XXX
 SG_ HVP_a013_bmbCommStatusTypeB m13 : 29|2@1+ (1,0) [0|3] "" Vector__XXX
 SG_ HVP_a013_bmbChainBreakType m13 : 32|3@1+ (1,0) [0|7] "" Vector__XXX
 SG_ HVP_a018_dcLinkVoltage m18 : 16|16@1+ (0.01,0) [0|655.35] "V" Vector__XXX
 SG_ HVP_a018_battery12V m18 : 32|12@1+ (0.1,0) [0|409.5] "V" Vector__XXX
 SG_ HVP_a018_remainingPcsPowerCycles m18 : 44|2@1+ (1,0) [0|3] "" Vector__XXX
 SG_ HVP_a018_remainingPcsRecoveriesA m18 : 46|2@1+ (1,0) [0|3] "" Vector__XXX
 SG_ HVP_a018_hvcHardwareSupportsCycl m18 : 48|1@1+ (1,0) [0|1] "" Vector__XXX
 SG_ HVP_a018_pcsHardwareOkToBePowerC m18 : 49|1@1+ (1,0) [0|1] "" Vector__XXX
 SG_ HVP_a018_gpioLogicPowerEnable m18 : 50|1@1+ (1,0) [0|1] "" Vector__XXX
 SG_ HVP_a018_gpioDcDcEnable m18 : 51|1@1+ (1,0) [0|1] "" Vector__XXX
 SG_ HVP_a018_gpioChgEnable m18 : 52|1@1+ (1,0) [0|1] "" Vector__XXX
 SG_ HVP_a020_energyReserveV m20 : 16|16@1+ (0.001,0) [0|65.534] "V" Vector__XXX
 SG_ HVP_a020_shuntCurrentAux m20 : 32|16@1- (0.1,0) [-3276.8|3276.7] "A" Vector__XXX
 SG_ HVP_a020_shuntTemperature m20 : 48|16@1- (0.01,0) [-327.68|327.67] "C" Vector__XXX
 SG_ HVP_a021_pyroStatus m21 : 16|2@1+ (1,0) [0|3] "" Vector__XXX
 SG_ HVP_a021_ErTestFailed m21 : 18|1@1+ (1,0) [0|1] "" Vector__XXX
 SG_ HVP_a021_HighSideSwitchTestFaile m21 : 19|1@1+ (1,0) [0|1] "" Vector__XXX
 SG_ HVP_a021_LowSideSwitchTestFailed m21 : 20|1@1+ (1,0) [0|1] "" Vector__XXX
 SG_ HVP_a021_RefCurrentTestFailed m21 : 21|1@1+ (1,0) [0|1] "" Vector__XXX
 SG_ HVP_a021_PyroLeakTestFailed m21 : 22|1@1+ (1,0) [0|1] "" Vector__XXX
 SG_ HVP_a021_SquibResTestFailed m21 : 23|1@1+ (1,0) [0|1] "" Vector__XXX
 SG_ HVP_a021_VstTestFailed m21 : 24|1@1+ (1,0) [0|1] "" Vector__XXX
 SG_ HVP_a021_SquibResistance m21 : 25|16@1+ (0.001,0) [0|65.534] "Ohm" Vector__XXX
 SG_ HVP_a021_OneShotSequence m21 : 41|1@1+ (1,0) [0|1] "" Vector__XXX
 SG_ HVP_a021_HighSide m21 : 42|1@1+ (1,0) [0|1] "" Vector__XXX
 SG_ HVP_a021_LowSide m21 : 43|1@1+ (1,0) [0|1] "" Vector__XXX
 SG_ HVP_a021_Aout m21 : 44|14@1+ (0.001,0) [0|16.382] "V" Vector__XXX
 SG_ HVP_a022_pyroStatus m22 : 16|2@1+ (1,0) [0|3] "" Vector__XXX
 SG_ HVP_a022_PyroLeakTestFailed m22 : 18|1@1+ (1,0) [0|1] "" Vector__XXX
 SG_ HVP_a022_OneShotSequence m22 : 19|1@1+ (1,0) [0|1] "" Vector__XXX
 SG_ HVP_a022_HighSide m22 : 20|1@1+ (1,0) [0|1] "" Vector__XXX
 SG_ HVP_a022_LowSide m22 : 21|1@1+ (1,0) [0|1] "" Vector__XXX
 SG_ HVP_a022_Aout m22 : 24|14@1+ (0.001,0) [0|16.382] "V" Vector__XXX
 SG_ HVP_a022_SquibResistance m22 : 40|16@1+ (0.001,0) [0|65.534] "Ohm" Vector__XXX
 SG_ HVP_a024_voltage m24 : 16|16@1+ (0.1,0) [0|6553.5] "V" Vector__XXX
 SG_ HVP_a025_voltage1 m25 : 16|16@1+ (0.1,0) [0|6553.5] "V" Vector__XXX
 SG_ HVP_a025_voltage2 m25 : 32|16@1+ (0.1,0) [0|6553.5] "V" Vector__XXX
 SG_ HVP_a025_packVoltage m25 : 48|16@1+ (0.1,0) [0|6553.5] "V" Vector__XXX
 SG_ HVP_a026_hvilStatus m26 : 16|4@1+ (1,0) [0|15] "" Vector__XXX
 SG_ HVP_a026_inputVoltage m26 : 24|8@1+ (0.04,0) [0|10.2] "V" Vector__XXX
 SG_ HVP_a026_outputVoltage m26 : 32|8@1+ (0.04,0) [0|10.2] "V" Vector__XXX
 SG_ HVP_a026_internalVoltage m26 : 40|8@1+ (0.04,0) [0|10.16] "V" Vector__XXX
 SG_ HVP_a026_dirVoltage m26 : 48|8@1+ (0.04,0) [0|10.16] "V" Vector__XXX
 SG_ HVP_a026_difVoltage m26 : 56|8@1+ (0.04,0) [0|10.16] "V" Vector__XXX
 SG_ HVP_a028_packVoltage m28 : 16|16@1+ (0.1,0) [0|6553.5] "V" Vector__XXX
 SG_ HVP_a028_sumOfBrickV m28 : 32|16@1+ (0.1,0) [0|6553.5] "V" Vector__XXX
 SG_ HVP_a030_packPositiveLinkV m30 : 16|16@1- (0.1,0) [-3276.8|3276.7] "V" Vector__XXX
 SG_ HVP_a030_dcPositiveLinkV m30 : 32|16@1- (0.1,0) [-3276.8|3276.7] "V" Vector__XXX
 SG_ HVP_a031_packNegativeLinkV m31 : 16|16@1- (0.1,0) [-3276.8|3276.7] "V" Vector__XXX
 SG_ HVP_a031_dcNegativeLinkV m31 : 32|16@1- (0.1,0) [-3276.8|3276.7] "V" Vector__XXX
 SG_ HVP_a033_contactorPowerV m33 : 16|16@1+ (0.1,0) [0|6553.5] "V" Vector__XXX
 SG_ HVP_a033_coilCurrent m33 : 32|16@1+ (0.1,0) [0|6553.5] "A" Vector__XXX
 SG_ HVP_a033_pwmDutyCylePositive m33 : 48|8@1+ (1,0) [0|255] "Percentage" Vector__XXX
 SG_ HVP_a033_pwmDutyCyleNegative m33 : 56|8@1+ (1,0) [0|255] "Percentage" Vector__XXX
 SG_ HVP_a035_contactorPowerV m35 : 16|16@1+ (0.1,0) [0|6553.5] "V" Vector__XXX
 SG_ HVP_a035_coilCurrent m35 : 32|16@1+ (0.1,0) [0|6553.5] "A" Vector__XXX
 SG_ HVP_a035_pwmDutyCylePositive m35 : 48|8@1+ (1,0) [0|255] "Percentage" Vector__XXX
 SG_ HVP_a035_pwmDutyCyleNegative m35 : 56|8@1+ (1,0) [0|255] "Percentage" Vector__XXX
 SG_ HVP_a036_pyroFiringHandle m36 : 16|4@1+ (1,0) [0|15] "" Vector__XXX
 SG_ HVP_a036_pyroFiringTime m36 : 24|16@1+ (1,0) [0|65535] "" Vector__XXX
 SG_ HVP_a036_pyroFiringAttempt m36 : 40|4@1+ (1,0) [0|15] "" Vector__XXX
 SG_ HVP_a037_pyroFiringHandle m37 : 16|4@1+ (1,0) [0|15] "" Vector__XXX
 SG_ HVP_a039_posContactorFailed m39 : 16|1@1+ (1,0) [0|1] "" Vector__XXX
 SG_ HVP_a039_negContactorFailed m39 : 17|1@1+ (1,0) [0|1] "" Vector__XXX
 SG_ HVP_a040_powerVoltage m40 : 16|8@1+ (0.1,0) [0|25.5] "V" Vector__XXX
 SG_ HVP_a040_coilCurrent m40 : 24|8@1+ (0.1,0) [0|25.5] "A" Vector__XXX
 SG_ HVP_a040_posCtrVoltageDrop m40 : 32|15@1- (0.1,0) [-1638.4|1638.3] "V" Vector__XXX
 SG_ HVP_a040_negCtrVoltageDrop m40 : 47|15@1- (0.1,0) [-1638.4|1638.3] "V" Vector__XXX
 SG_ HVP_a040_posCtrAuxOpen m40 : 62|1@1+ (1,0) [0|1] "" Vector__XXX
 SG_ HVP_a040_negCtrAuxOpen m40 : 63|1@1+ (1,0) [0|1] "" Vector__XXX
 SG_ HVP_a041_overCurrent m41 : 16|1@1+ (1,0) [0|1] "" Vector__XXX
 SG_ HVP_a041_overChargeCurrent m41 : 17|1@1+ (1,0) [0|1] "" Vector__XXX
 SG_ HVP_a041_overDischargeCurrent m41 : 18|1@1+ (1,0) [0|1] "" Vector__XXX
 SG_ HVP_a041_overVoltage m41 : 19|1@1+ (1,0) [0|1] "" Vector__XXX
 SG_ HVP_a041_overTemperature m41 : 20|1@1+ (1,0) [0|1] "" Vector__XXX
 SG_ HVP_a041_underVoltage m41 : 21|1@1+ (1,0) [0|1] "" Vector__XXX
 SG_ HVP_a041_crashEvent m41 : 22|1@1+ (1,0) [0|1] "" Vector__XXX
 SG_ HVP_a041_packContactorHw m41 : 23|1@1+ (1,0) [0|1] "" Vector__XXX
 SG_ HVP_a041_notAllowedtoEnergize m41 : 24|1@1+ (1,0) [0|1] "" Vector__XXX
 SG_ HVP_a041_bmbMia m41 : 25|1@1+ (1,0) [0|1] "" Vector__XXX
 SG_ HVP_a041_hvilFault m41 : 26|1@1+ (1,0) [0|1] "" Vector__XXX
 SG_ HVP_a041_contactorStateWelded m41 : 27|1@1+ (1,0) [0|1] "" Vector__XXX
 SG_ HVP_a041_shuntHwMia m41 : 28|1@1+ (1,0) [0|1] "" Vector__XXX
 SG_ HVP_a041_shuntCurrentMia m41 : 29|1@1+ (1,0) [0|1] "" Vector__XXX
 SG_ HVP_a041_packVoltageMismatch m41 : 30|1@1+ (1,0) [0|1] "" Vector__XXX
 SG_ HVP_a041_gpoRequestActive m41 : 31|1@1+ (1,0) [0|1] "" Vector__XXX
 SG_ HVP_a041_fcContactorClosing m41 : 32|1@1+ (1,0) [0|1] "" Vector__XXX
 SG_ HVP_a041_fcContactorOpening m41 : 33|1@1+ (1,0) [0|1] "" Vector__XXX
 SG_ HVP_a041_resetRequestRequired m41 : 34|1@1+ (1,0) [0|1] "" Vector__XXX
 SG_ HVP_a041_pyroFault m41 : 35|1@1+ (1,0) [0|1] "" Vector__XXX
 SG_ HVP_a041_dcLinkOverVoltage m41 : 36|1@1+ (1,0) [0|1] "" Vector__XXX
 SG_ HVP_a042_overCurrent m42 : 16|1@1+ (1,0) [0|1] "" Vector__XXX
 SG_ HVP_a042_overChargeCurrent m42 : 17|1@1+ (1,0) [0|1] "" Vector__XXX
 SG_ HVP_a042_overDischargeCurrent m42 : 18|1@1+ (1,0) [0|1] "" Vector__XXX
 SG_ HVP_a042_overVoltage m42 : 19|1@1+ (1,0) [0|1] "" Vector__XXX
 SG_ HVP_a042_overTemperature m42 : 20|1@1+ (1,0) [0|1] "" Vector__XXX
 SG_ HVP_a042_crashEvent m42 : 21|1@1+ (1,0) [0|1] "" Vector__XXX
 SG_ HVP_a042_fcContactorHw m42 : 22|1@1+ (1,0) [0|1] "" Vector__XXX
 SG_ HVP_a042_notAllowedtoEnergize m42 : 23|1@1+ (1,0) [0|1] "" Vector__XXX
 SG_ HVP_a042_bmsHvsMia m42 : 24|1@1+ (1,0) [0|1] "" Vector__XXX
 SG_ HVP_a042_cpMia m42 : 25|1@1+ (1,0) [0|1] "" Vector__XXX
 SG_ HVP_a042_cpFault m42 : 26|1@1+ (1,0) [0|1] "" Vector__XXX
 SG_ HVP_a042_supply12V m42 : 27|1@1+ (1,0) [0|1] "" Vector__XXX
 SG_ HVP_a042_supplyVer m42 : 28|1@1+ (1,0) [0|1] "" Vector__XXX
 SG_ HVP_a042_packVoltageMismatch m42 : 29|1@1+ (1,0) [0|1] "" Vector__XXX
 SG_ HVP_a042_hvilFault m42 : 30|1@1+ (1,0) [0|1] "" Vector__XXX
 SG_ HVP_a042_contactorStateWelded m42 : 31|1@1+ (1,0) [0|1] "" Vector__XXX
 SG_ HVP_a042_shuntHwMia m42 : 32|1@1+ (1,0) [0|1] "" Vector__XXX
 SG_ HVP_a042_shuntCurrentMia m42 : 33|1@1+ (1,0) [0|1] "" Vector__XXX
 SG_ HVP_a042_packContactorClosing m42 : 34|1@1+ (1,0) [0|1] "" Vector__XXX
 SG_ HVP_a042_packContactorOpening m42 : 35|1@1+ (1,0) [0|1] "" Vector__XXX
 SG_ HVP_a042_resetRequestRequired m42 : 36|1@1+ (1,0) [0|1] "" Vector__XXX
 SG_ HVP_a042_cpVersionMismatch m42 : 37|1@1+ (1,0) [0|1] "" Vector__XXX
 SG_ HVP_a043_overCurrent m43 : 16|1@1+ (1,0) [0|1] "" Vector__XXX
 SG_ HVP_a043_overChargeCurrent m43 : 17|1@1+ (1,0) [0|1] "" Vector__XXX
 SG_ HVP_a043_overDischargeCurrent m43 : 18|1@1+ (1,0) [0|1] "" Vector__XXX
 SG_ HVP_a043_overVoltage m43 : 19|1@1+ (1,0) [0|1] "" Vector__XXX
 SG_ HVP_a043_overTemperature m43 : 20|1@1+ (1,0) [0|1] "" Vector__XXX
 SG_ HVP_a043_underVoltage m43 : 21|1@1+ (1,0) [0|1] "" Vector__XXX
 SG_ HVP_a043_crashEvent m43 : 22|1@1+ (1,0) [0|1] "" Vector__XXX
 SG_ HVP_a043_packContactorHw m43 : 23|1@1+ (1,0) [0|1] "" Vector__XXX
 SG_ HVP_a043_notAllowedtoEnergize m43 : 24|1@1+ (1,0) [0|1] "" Vector__XXX
 SG_ HVP_a043_bmbMia m43 : 25|1@1+ (1,0) [0|1] "" Vector__XXX
 SG_ HVP_a043_contactorOpened m43 : 26|1@1+ (1,0) [0|1] "" Vector__XXX
 SG_ HVP_a044_overCurrent m44 : 16|1@1+ (1,0) [0|1] "" Vector__XXX
 SG_ HVP_a044_overChargeCurrent m44 : 17|1@1+ (1,0) [0|1] "" Vector__XXX
 SG_ HVP_a044_overDischargeCurrent m44 : 18|1@1+ (1,0) [0|1] "" Vector__XXX
 SG_ HVP_a044_overVoltage m44 : 19|1@1+ (1,0) [0|1] "" Vector__XXX
 SG_ HVP_a044_overTemperature m44 : 20|1@1+ (1,0) [0|1] "" Vector__XXX
 SG_ HVP_a044_crashEvent m44 : 21|1@1+ (1,0) [0|1] "" Vector__XXX
 SG_ HVP_a044_fcContactorHw m44 : 22|1@1+ (1,0) [0|1] "" Vector__XXX
 SG_ HVP_a044_notAllowedtoEnergize m44 : 23|1@1+ (1,0) [0|1] "" Vector__XXX
 SG_ HVP_a044_bmsHvsMia m44 : 24|1@1+ (1,0) [0|1] "" Vector__XXX
 SG_ HVP_a044_cpMia m44 : 25|1@1+ (1,0) [0|1] "" Vector__XXX
 SG_ HVP_a044_cpFault m44 : 26|1@1+ (1,0) [0|1] "" Vector__XXX
 SG_ HVP_a044_supply12V m44 : 27|1@1+ (1,0) [0|1] "" Vector__XXX
 SG_ HVP_a044_supplyVer m44 : 28|1@1+ (1,0) [0|1] "" Vector__XXX
 SG_ HVP_a044_packVoltageMismatch m44 : 29|1@1+ (1,0) [0|1] "" Vector__XXX
 SG_ HVP_a044_contactorOpened m44 : 30|1@1+ (1,0) [0|1] "" Vector__XXX
 SG_ HVP_a044_cpVersionMismatch m44 : 31|1@1+ (1,0) [0|1] "" Vector__XXX
 SG_ HVP_a045_dcLinkVoltage m45 : 16|16@1+ (0.1,0) [0|6553.5] "V" Vector__XXX
 SG_ HVP_a046_shuntCurrent m46 : 16|16@1- (0.1,0) [-3276.8|3276.7] "A" Vector__XXX
 SG_ HVP_a046_shuntTemperature m46 : 32|16@1- (0.01,0) [-327.68|327.67] "C" Vector__XXX
 SG_ HVP_a046_asicTemperature m46 : 48|16@1- (0.01,0) [-327.68|327.67] "C" Vector__XXX
 SG_ HVP_a047_shuntCurrent m47 : 16|16@1- (0.1,0) [-3276.8|3276.7] "A" Vector__XXX
 SG_ HVP_a047_auxCurrent m47 : 32|16@1- (0.1,0) [-3276.8|3276.7] "A" Vector__XXX
 SG_ HVP_a049_contactorPowerV m49 : 16|16@1+ (0.1,0) [0|6553.5] "V" Vector__XXX
 SG_ HVP_a049_coilCurrent m49 : 32|16@1+ (0.1,0) [0|6553.5] "A" Vector__XXX
 SG_ HVP_a049_posCtrState m49 : 48|3@1+ (1,0) [1|7] "" Vector__XXX
 SG_ HVP_a049_negCtrState m49 : 51|3@1+ (1,0) [1|7] "" Vector__XXX
 SG_ HVP_a050_contactorPowerV m50 : 16|16@1+ (0.1,0) [0|6553.5] "V" Vector__XXX
 SG_ HVP_a050_coilCurrent m50 : 32|16@1+ (0.1,0) [0|6553.5] "A" Vector__XXX
 SG_ HVP_a050_posCtrState m50 : 48|3@1+ (1,0) [1|7] "" Vector__XXX
 SG_ HVP_a050_negCtrState m50 : 51|3@1+ (1,0) [1|7] "" Vector__XXX
 SG_ HVP_a051_shuntTemperature m51 : 16|16@1- (0.01,0) [-327.68|327.67] "C" Vector__XXX
 SG_ HVP_a051_shuntCurrent m51 : 32|16@1- (0.1,0) [-3276.8|3276.7] "A" Vector__XXX
 SG_ HVP_a051_energyReserveV m51 : 48|16@1+ (0.001,0) [0|65.534] "V" Vector__XXX
 SG_ HVP_a052_bmbDeviceMask m52 : 16|16@1+ (1,0) [0|65535] "" Vector__XXX
 SG_ HVP_a052_regErrorType m52 : 32|8@1+ (1,0) [0|255] "" Vector__XXX
 SG_ HVP_a053_packVoltage m53 : 16|16@1+ (0.01,0) [0|655.35] "V" Vector__XXX
 SG_ HVP_a053_dcLinkVoltage m53 : 32|16@1+ (0.01,0) [0|655.35] "V" Vector__XXX
 SG_ HVP_a056_diagnosis m56 : 16|2@1+ (1,0) [1|3] "" Vector__XXX
 SG_ HVP_a056_shuntCurrent m56 : 24|16@1- (0.1,0) [-3276.8|3276.7] "A" Vector__XXX
 SG_ HVP_a056_posPackContactorState m56 : 40|3@1+ (1,0) [1|7] "" Vector__XXX
 SG_ HVP_a056_negPackContactorState m56 : 43|3@1+ (1,0) [1|7] "" Vector__XXX
 SG_ HVP_a056_posFcContactorState m56 : 48|3@1+ (1,0) [1|7] "" Vector__XXX
 SG_ HVP_a056_negFcContactorState m56 : 51|3@1+ (1,0) [1|7] "" Vector__XXX
 SG_ HVP_a058_VrefSample m58 : 16|16@1+ (0.0001,0) [0|6.5535] "V" Vector__XXX
 SG_ HVP_a058_bmbDeviceId m58 : 32|4@1+ (1,1) [1|16] "" Vector__XXX
 SG_ HVP_a058_VrefStatus m58 : 36|2@1+ (1,0) [0|3] "" Vector__XXX
 SG_ HVP_a058_VrefType m58 : 38|2@1+ (1,0) [0|3] "" Vector__XXX
 SG_ HVP_a060_stackVoltage m60 : 16|16@1+ (0.00128,0) [0|83.8848] "V" Vector__XXX
 SG_ HVP_a060_sumBrickVoltage m60 : 32|16@1+ (0.00128,0) [0|83.8848] "V" Vector__XXX
 SG_ HVP_a060_stackId m60 : 48|8@1+ (1,1) [1|256] "" Vector__XXX
 SG_ HVP_a062_bmbDeviceMask m62 : 16|16@1+ (1,0) [0|65535] "" Vector__XXX
 SG_ HVP_a067_hvilTypeFromHvp m67 : 16|2@1+ (1,0) [0|3] "" Vector__XXX
 SG_ HVP_a067_hvilTypeFromGateway m67 : 18|2@1+ (1,0) [0|3] "" Vector__XXX
 SG_ HVP_a067_hvilTypeIsFromCal m67 : 20|1@1+ (1,0) [0|1] "" Vector__XXX
 SG_ HVP_a068_shuntTemperature m68 : 16|16@1- (0.01,0) [-327.68|327.67] "C" Vector__XXX
 SG_ HVP_a068_shuntCurrent m68 : 32|16@1- (0.1,0) [-3276.8|3276.7] "A" Vector__XXX
 SG_ HVP_a068_energyReserveV m68 : 48|16@1+ (0.001,0) [0|65.534] "V" Vector__XXX

BO_TX_BU_ 62 : GTW;
BO_TX_BU_ 838 : GTW;
BO_TX_BU_ 904 : GTW;
BO_TX_BU_ 2047 : GTW;
BO_TX_BU_ 792 : GTW;
BO_TX_BU_ 1638 : GTW;
BO_TX_BU_ 1080 : GTW;
BO_TX_BU_ 1376 : GTW;
BO_TX_BU_ 1656 : GTW;
BO_TX_BU_ 2033 : GTW;
BO_TX_BU_ 60 : GTW;
BO_TX_BU_ 1370 : GTW;
BO_TX_BU_ 840 : GTW;
BO_TX_BU_ 1005 : GTW;
BO_TX_BU_ 1112 : GTW;
BO_TX_BU_ 1290 : HVP;
CM_ BO_ 62 "Gateway message: alert matrix";
CM_ SG_ 62 GTW_matrixIndex "Gateway: matrix index";
CM_ SG_ 62 GTW_w001_canEthTxQueue "Gateway: w001 can eth tx queue";
CM_ SG_ 62 GTW_w002_taskError "Gateway: w002 task error";
CM_ SG_ 62 GTW_w003_logWriteRecord "Gateway: w003 log write record";
CM_ SG_ 62 GTW_w004_mallocHook "Gateway: w004 malloc hook";
CM_ SG_ 62 GTW_w005_stackOverflowHook "Gateway: w005 stack overflow hook";
CM_ SG_ 62 GTW_w006_ifTxOutputFull "Gateway: w006 if tx output full";
CM_ SG_ 62 GTW_w007_ifRxBufError "Gateway: w007 if rx buf error";
CM_ SG_ 62 GTW_w008_ifPbufAllocError "Gateway: w008 if pbuf alloc error";
CM_ SG_ 62 GTW_w009_lateTask "Gateway: w009 late task";
CM_ SG_ 62 GTW_w010_wdTaskCount "Gateway: w010 wd task count";
CM_ SG_ 62 GTW_w011_cancoreWatchdog "Gateway: w011 cancore watchdog";
CM_ SG_ 62 GTW_w012_maincoreWatchdog "Gateway: w012 maincore watchdog";
CM_ SG_ 62 GTW_w014_APSversionMismatch "Gateway: w014 AP sversion mismatch";
CM_ SG_ 62 GTW_w015_DIFversionMismatch "Gateway: w015 DI fversion mismatch";
CM_ SG_ 62 GTW_w016_BLEEPCENTERversionMisma "Gateway: w016 BLEEPCENTE rversion mismatch";
CM_ SG_ 62 GTW_w017_BMSversionMismatch "Gateway: w017 BM sversion mismatch";
CM_ SG_ 62 GTW_w018_CMPversionMismatch "Gateway: w018 CM pversion mismatch";
CM_ SG_ 62 GTW_w019_CPversionMismatch "Gateway: w019 c pversion mismatch";
CM_ SG_ 62 GTW_w020_DIRversionMismatch "Gateway: w020 DI rversion mismatch";
CM_ SG_ 62 GTW_w021_EPAS3PversionMismatch "Gateway: w021 EPAS3 pversion mismatch";
CM_ SG_ 62 GTW_w022_EPBLversionMismatch "Gateway: w022 EPB lversion mismatch";
CM_ SG_ 62 GTW_w023_EPBRversionMismatch "Gateway: w023 EPB rversion mismatch";
CM_ SG_ 62 GTW_w024_ESPversionMismatch "Gateway: w024 ES pversion mismatch";
CM_ SG_ 62 GTW_w025_ESPCALversionMismatch "Gateway: w025 ESPCA lversion mismatch";
CM_ SG_ 62 GTW_w026_GTWversionMismatch "Gateway: w026 GT wversion mismatch";
CM_ SG_ 62 GTW_w027_HVPversionMismatch "Gateway: w027 HV pversion mismatch";
CM_ SG_ 62 GTW_w028_IBSTversionMismatch "Gateway: w028 IBS tversion mismatch";
CM_ SG_ 62 GTW_w029_IBSTCALversionMismatch "Gateway: w029 IBSTCA lversion mismatch";
CM_ SG_ 62 GTW_w030_OCS1PversionMismatch "Gateway: w030 OCS1 pversion mismatch";
CM_ SG_ 62 GTW_w031_PARKversionMismatch "Gateway: w031 PAR kversion mismatch";
CM_ SG_ 62 GTW_w032_PCSversionMismatch "Gateway: w032 PC sversion mismatch";
CM_ SG_ 62 GTW_w033_PCSCPU2versionMismatch "Gateway: w033 pcscpu2version mismatch";
CM_ SG_ 62 GTW_w034_PMRversionMismatch "Gateway: w034 PM rversion mismatch";
CM_ SG_ 62 GTW_w035_PMFversionMismatch "Gateway: w035 PM fversion mismatch";
CM_ SG_ 62 GTW_w036_PTCversionMismatch "Gateway: w036 PT cversion mismatch";
CM_ SG_ 62 GTW_w037_RADCversionMismatch "Gateway: w037 RAD cversion mismatch";
CM_ SG_ 62 GTW_w038_RCMversionMismatch "Gateway: w038 RC mversion mismatch";
CM_ SG_ 62 GTW_w039_RCMCALversionMismatch "Gateway: w039 RCMCA lversion mismatch";
CM_ SG_ 62 GTW_w040_SCCMversionMismatch "Gateway: w040 SCC mversion mismatch";
CM_ SG_ 62 GTW_w041_VCSECversionMismatch "Gateway: w041 VCSE cversion mismatch";
CM_ SG_ 62 GTW_w042_TASversionMismatch "Gateway: w042 TA sversion mismatch";
CM_ SG_ 62 GTW_w043_THSversionMismatch "Gateway: w043 TH sversion mismatch";
CM_ SG_ 62 GTW_w045_VCFRONTversionMismatch "Gateway: w045 VCFRON tversion mismatch";
CM_ SG_ 62 GTW_w046_VCLEFTversionMismatch "Gateway: w046 VCLEF tversion mismatch";
CM_ SG_ 62 GTW_w047_VCRIGHTversionMismatch "Gateway: w047 VCRIGH tversion mismatch";
CM_ SG_ 62 GTW_w048_EPAS3SversionMismatch "Gateway: w048 EPAS3 sversion mismatch";
CM_ SG_ 62 GTW_w049_corruptedManifest "Gateway: w049 corrupted manifest";
CM_ SG_ 62 GTW_w050_sdCardInitFailure "Gateway: w050 sd card init failure";
CM_ SG_ 62 GTW_w051_sdCardFileSystemFailure "Gateway: w051 sd card file system failure";
CM_ SG_ 62 GTW_w052_ifTxSpans "Gateway: w052 if tx spans";
CM_ SG_ 62 GTW_w053_busSleepFailure "Gateway: w053 bus sleep failure";
CM_ SG_ 62 GTW_w054_OPCRversionMismatch "Gateway: w054 OPC rversion mismatch";
CM_ SG_ 62 GTW_w055_OPCFversionMismatch "Gateway: w055 OPC fversion mismatch";
CM_ SG_ 62 GTW_w057_i2cFailure "Gateway: w057 i2c failure";
CM_ SG_ 62 GTW_w058_rtcAlarmFailure "Gateway: w058 rtc alarm failure";
CM_ SG_ 62 GTW_w059_inFactoryMode "Gateway: w059 in factory mode";
CM_ SG_ 62 GTW_w060_unFused "Gateway: w060 un fused";
CM_ SG_ 62 GTW_w061_bmpSleepFailure "Gateway: w061 bmp sleep failure";
CM_ SG_ 62 GTW_w062_bmpWatchdog "Gateway: w062 bmp watchdog";
CM_ SG_ 62 GTW_w063_VEH_canFault "Gateway: w063 VEH can fault";
CM_ SG_ 62 GTW_w064_CH_canFault "Gateway: w064 CH can fault";
CM_ SG_ 62 GTW_w065_PARTY_canFault "Gateway: w065 PARTY can fault";
CM_ SG_ 62 GTW_w066_exception "Gateway: w066 exception";
CM_ SG_ 62 GTW_w067_tcpDebug "Gateway: w067 tcp debug";
CM_ SG_ 62 GTW_w068_prodKeyMissing "Gateway: w068 prod key missing";
CM_ SG_ 62 GTW_w069_diskioErr "Gateway: w069 diskio err";
CM_ SG_ 62 GTW_w070_hrlDump "Gateway: w070 hrl dump";
CM_ SG_ 62 GTW_w071_hrlTrigger "Gateway: w071 hrl trigger";
CM_ SG_ 62 GTW_w072_updateFailure "Gateway: w072 update failure";
CM_ SG_ 62 GTW_w073_steeringWheelReset "Gateway: w073 steering wheel reset";
CM_ SG_ 62 GTW_w074_epas3pMIA "Gateway: w074 epas3p MIA";
CM_ SG_ 62 GTW_w075_epas3sMIA "Gateway: w075 epas3s MIA";
CM_ SG_ 62 GTW_w076_ethInterfaceReset "Gateway: w076 eth interface reset";
CM_ SG_ 62 GTW_w077_bmpPmicError "Gateway: w077 bmp pmic error";
CM_ SG_ 62 GTW_w078_VEHbusOverloaded "Gateway: w078 VE hbus overloaded";
CM_ SG_ 62 GTW_w079_PARTYbusOverloaded "Gateway: w079 PART ybus overloaded";
CM_ SG_ 62 GTW_w080_CHbusOverloaded "Gateway: w080 c hbus overloaded";
CM_ SG_ 62 GTW_w081_udsMessageRejected "Gateway: w081 uds message rejected";
CM_ SG_ 62 GTW_w082_sdCardBSCorrupted "Gateway: w082 sd card BS corrupted";
CM_ SG_ 62 GTW_w083_udsMsgDroppedByTcpStack "Gateway: w083 uds msg dropped by tcp stack";
CM_ SG_ 62 GTW_w084_canFrameDropped "Gateway: w084 can frame dropped";
CM_ SG_ 62 GTW_w086_ocu "Gateway: w086 ocu";
CM_ SG_ 62 GTW_w087_ocuInProgress "Gateway: w087 ocu in progress";
CM_ SG_ 62 GTW_w088_sdCardInvReqParallel "Gateway: w088 sd card inv req parallel";
CM_ SG_ 62 GTW_w089_sdCardWatchdog "Gateway: w089 sd card watchdog";
CM_ SG_ 62 GTW_w090_ocuFailed "Gateway: w090 ocu failed";
CM_ SG_ 62 GTW_w091_lowStack "Gateway: w091 low stack";
CM_ SG_ 62 GTW_w092_sdCardInvReqZero "Gateway: w092 sd card inv req zero";
CM_ SG_ 62 GTW_w093_sdCardInvReqOverflowBas "Gateway: w093 sd card inv req overflow base";
CM_ SG_ 62 GTW_w094_sdCardInvReqOverflowCou "Gateway: w094 sd card inv req overflow count";
CM_ SG_ 62 GTW_w095_sdCardFull "Gateway: w095 sd card full";
CM_ SG_ 62 GTW_w096_sdCardFatCorrupted "Gateway: w096 sd card fat corrupted";
CM_ SG_ 62 GTW_w097_HCMLversionMismatch "Gateway: w097 HCM lversion mismatch";
CM_ SG_ 62 GTW_w098_HCMRversionMismatch "Gateway: w098 HCM rversion mismatch";
CM_ SG_ 62 GTW_w099_SWCversionMismatch "Gateway: w099 SW cversion mismatch";
CM_ SG_ 62 GTW_w100_CBCversionMismatch "Gateway: w100 CB cversion mismatch";
CM_ SG_ 62 GTW_w101_switchWatchdog "Gateway: w101 switch watchdog";
CM_ SG_ 62 GTW_w103_sdCardFormatted "Gateway: w103 sd card formatted";
CM_ SG_ 62 GTW_w104_sdCardDriverArgCorrupte "Gateway: w104 sd card driver arg corrupted";
CM_ SG_ 62 GTW_w105_eBuckConfigured "Gateway: w105 e buck configured";
CM_ SG_ 62 GTW_w106_BLEEPLEFTversionMismatc "Gateway: w106 BLEEPLEF tversion mismatch";
CM_ SG_ 62 GTW_w107_BLEEPRIGHTversionMismat "Gateway: w107 BLEEPRIGH tversion mismatch";
CM_ SG_ 62 GTW_w108_BLEEPREARversionMismatc "Gateway: w108 BLEEPREA rversion mismatch";
CM_ SG_ 62 GTW_w109_failedToStartUpdater "Gateway: w109 failed to start updater";
CM_ SG_ 62 GTW_w110_readMdioFailed "Gateway: w110 read mdio failed";
CM_ SG_ 62 GTW_w111_writeMdioFailed "Gateway: w111 write mdio failed";
CM_ SG_ 62 GTW_w112_z4bDisabled "Gateway: w112 z4b disabled";
CM_ SG_ 62 GTW_w113_unrecognizedCanMessage "Gateway: w113 unrecognized can message";
CM_ SG_ 62 GTW_w114_updtRetried "Gateway: w114 updt retried";
CM_ SG_ 62 GTW_w115_hrlEventFileAvail "Gateway: w115 hrl event file avail";
CM_ SG_ 62 GTW_w116_switchInitFailed "Gateway: w116 switch init failed";
CM_ SG_ 62 GTW_w117_unexpectedDestructiveRe "Gateway: w117 unexpected destructive reset status";
CM_ SG_ 62 GTW_w118_unexpectedFunctionalRes "Gateway: w118 unexpected functional reset status";
CM_ SG_ 62 GTW_w120_switchUnlocked "Gateway: w120 switch unlocked";
CM_ SG_ 62 GTW_w122_BDY_canFault "Gateway: w122 BDY can fault";
CM_ SG_ 62 GTW_w123_BDYbusOverloaded "Gateway: w123 BD ybus overloaded";
CM_ SG_ 62 GTW_w125_switchReplayUnlocked "Gateway: w125 switch replay unlocked";
CM_ SG_ 62 GTW_w127_noFilePointersAvailable "Gateway: w127 no file pointers available";
CM_ SG_ 62 GTW_w129_ICRversionMismatch "Gateway: w129 IC rversion mismatch";
CM_ SG_ 62 GTW_w133_adspFaultDetected "Gateway: w133 adsp fault detected";
CM_ SG_ 62 GTW_w134_disableFeatureFailed "Gateway: w134 disable feature failed";
CM_ SG_ 62 GTW_w135_canLogQueueFull "Gateway: w135 can log queue full";
CM_ SG_ 62 GTW_w136_hrlGameModeFileAvail "Gateway: w136 hrl game mode file avail";
CM_ SG_ 62 GTW_w137_lowHeap "Gateway: w137 low heap";
CM_ SG_ 62 GTW_w138_sdCardEndOfLife "Gateway: w138 sd card end of life";
CM_ SG_ 62 GTW_w139_CMPDversionMismatch "Gateway: w139 CMP dversion mismatch";
CM_ SG_ 62 GTW_w140_cancoreHeartbeat "Gateway: w140 cancore heartbeat";
CM_ SG_ 62 GTW_w141_teleCANETHis "Gateway: w141 tele CANET his";
CM_ SG_ 62 GTW_w143_possibleCanWakeIssue "Gateway: w143 possible can wake issue";
CM_ SG_ 62 GTW_w144_hrlStateMachine "Gateway: w144 hrl state machine";
CM_ SG_ 62 GTW_w145_carConfigsNotWritten "Gateway: w145 car configs not written";
CM_ SG_ 62 GTW_w146_performancePackageMisma "Gateway: w146 performance package mismatch";
CM_ SG_ 62 GTW_w147_updateAbortFor12v "Gateway: w147 update abort for12v";
CM_ SG_ 62 GTW_w149_rtcTimeSetInPast "Gateway: w149 rtc time set in past";
CM_ SG_ 62 GTW_w150_HCM3LversionMismatch "Gateway: w150 HCM3 lversion mismatch";
CM_ SG_ 62 GTW_w151_HCM3RversionMismatch "Gateway: w151 HCM3 rversion mismatch";
CM_ SG_ 62 GTW_w153_externalRtcAlarmFailure "Gateway: w153 external rtc alarm failure";
CM_ SG_ 62 GTW_w155_PMversionMismatch "Gateway: w155 p mversion mismatch";
CM_ SG_ 62 GTW_w165_USMversionMismatch "Gateway: w165 US mversion mismatch";
CM_ SG_ 62 GTW_w166_nErrCanFaultVeh "Gateway: w166 n err can fault veh";
CM_ SG_ 62 GTW_w167_nErrCanFaultCh "Gateway: w167 n err can fault ch";
CM_ SG_ 62 GTW_w168_nErrCanFaultParty "Gateway: w168 n err can fault party";
CM_ SG_ 62 GTW_w169_TPMSsoftWarnFrontLeft "Gateway: w169 TPM ssoft warn front left";
CM_ SG_ 62 GTW_w170_TPMSsoftWarnFrontRight "Gateway: w170 TPM ssoft warn front right";
CM_ SG_ 62 GTW_w171_TPMSsoftWarnRearLeft "Gateway: w171 TPM ssoft warn rear left";
CM_ SG_ 62 GTW_w172_TPMSsoftWarnRearRight "Gateway: w172 TPM ssoft warn rear right";
CM_ SG_ 62 GTW_w173_TPMShardWarnFrontLeft "Gateway: w173 TPM shard warn front left";
CM_ SG_ 62 GTW_w174_TPMShardWarnFrontRight "Gateway: w174 TPM shard warn front right";
CM_ SG_ 62 GTW_w175_TPMShardWarnRearLeft "Gateway: w175 TPM shard warn rear left";
CM_ SG_ 62 GTW_w176_TPMShardWarnRearRight "Gateway: w176 TPM shard warn rear right";
CM_ SG_ 62 GTW_w186_swrPrecaution "Gateway: w186 swr precaution";
CM_ SG_ 62 GTW_w218_switchOTPIncorrect "Gateway: w218 switch OTP incorrect";
CM_ SG_ 62 GTW_w219_CMPSversionMismatch "Gateway: w219 CMP sversion mismatch";
CM_ SG_ 62 GTW_w223_LVBMSversionMismatch "Gateway: w223 LVBM sversion mismatch";
CM_ SG_ 62 GTW_w224_sdCardUpgradeNeeded "Gateway: w224 sd card upgrade needed";
CM_ SG_ 62 GTW_w225_resetOnSleepWake "Gateway: w225 reset on sleep wake";
CM_ SG_ 62 GTW_w226_DISPversionMismatch "Gateway: w226 DIS pversion mismatch";
CM_ SG_ 62 GTW_w227_DISPTOUCHversionMismatc "Gateway: w227 DISPTOUC hversion mismatch";
CM_ SG_ 62 GTW_w228_DISPOSDversionMismatch "Gateway: w228 DISPOS dversion mismatch";
CM_ SG_ 62 GTW_w229_displaySoftsetConnectio "Gateway: w229 display softset connection";
CM_ SG_ 62 GTW_w230_touchInterruptStorm "Gateway: w230 touch interrupt storm";
CM_ SG_ 62 GTW_w244_SDCRversionMismatch "Gateway: w244 SDC rversion mismatch";
CM_ SG_ 62 GTW_w245_apsNotDisabled "Gateway: w245 aps not disabled";
CM_ SG_ 62 GTW_w246_touchcoreHeartbeat "Gateway: w246 touchcore heartbeat";
CM_ SG_ 62 GTW_w255_rtc32KHzWatchdog "Gateway: w255 rtc32 k hz watchdog";
CM_ SG_ 62 GTW_w260_unknownPN "Gateway: w260 unknown PN";
CM_ SG_ 62 GTW_w261_adspWatchdog "Gateway: w261 adsp watchdog";
CM_ SG_ 62 GTW_w262_canLogBlockDropped "Gateway: w262 can log block dropped";
CM_ SG_ 62 GTW_w263_hrlUdpFileAvail "Gateway: w263 hrl udp file avail";
CM_ SG_ 62 GTW_w264_hrlPseudoFileAvail "Gateway: w264 hrl pseudo file avail";
CM_ SG_ 62 GTW_w265_optionFlagsError "Gateway: w265 option flags error";
CM_ SG_ 62 GTW_w266_dpp1MIA "Gateway: w266 dpp1 MIA";
CM_ SG_ 62 GTW_w267_dpp2MIA "Gateway: w267 dpp2 MIA";
CM_ SG_ 62 GTW_w268_stoMIA "Gateway: w268 sto MIA";
CM_ SG_ 62 GTW_w273_BLEEPREARLEFTversionMis "Gateway: w273 BLEEPREARLEF tversion mismatch";
CM_ SG_ 62 GTW_w274_BLEEPREARRIGHTversionMi "Gateway: w274 BLEEPREARRIGH tversion mismatch";
CM_ SG_ 62 GTW_w275_VDDCORE_DrMOS_Fault "Gateway: w275 VDDCORE dr MOS fault";
CM_ SG_ 62 GTW_w276_VDDSOC_DrMOS_Fault "Gateway: w276 VDDSOC dr MOS fault";
CM_ SG_ 62 GTW_w277_NonRevCDrMOSMitigationF "Gateway: w277 non rev c dr MOS mitigation failed";
CM_ SG_ 62 GTW_w278_ethSwitchCongested "Gateway: w278 eth switch congested";
CM_ SG_ 62 GTW_w279_adspRepeatedWatchdog "Gateway: w279 adsp repeated watchdog";
CM_ SG_ 62 GTW_w280_hrlFrameDropped "Gateway: w280 hrl frame dropped";
CM_ SG_ 62 GTW_w281_likelyMissedPoke "Gateway: w281 likely missed poke";
CM_ SG_ 62 GTW_w282_tcuPhyConfigurationFail "Gateway: w282 tcu phy configuration failed";
CM_ SG_ 62 GTW_w309_VCUSBversionMismatch "Gateway: w309 VCUS bversion mismatch";
CM_ SG_ 62 GTW_w311_canLogQueueFullBeforeFs "Gateway: w311 can log queue full before fs init";
CM_ SG_ 62 GTW_w312_hrlFileIncomplete "Gateway: w312 hrl file incomplete";
CM_ SG_ 62 GTW_w313_OSDActive "Gateway: w313 OSD active";
CM_ SG_ 62 GTW_w314_canLogBlockWriteErr "Gateway: w314 can log block write err";
CM_ SG_ 62 GTW_w316_sdCardChkdskRepair "Gateway: w316 sd card chkdsk repair";
CM_ SG_ 62 GTW_w317_sdCardChkdskRepairFaile "Gateway: w317 sd card chkdsk repair failed";
CM_ SG_ 62 GTW_w322_gestureUnrecognizedFrom "Gateway: w322 gesture unrecognized from moving";
CM_ SG_ 62 GTW_w323_gestureStartOutOfStrip "Gateway: w323 gesture start out of strip";
CM_ SG_ 62 GTW_w328_smartShiftDisabled "Gateway: w328 smart shift disabled";
CM_ SG_ 62 GTW_w329_FOHMversionMismatch "Gateway: w329 FOH mversion mismatch";
CM_ SG_ 62 GTW_w330_SWSLversionMismatch "Gateway: w330 SWS lversion mismatch";
CM_ SG_ 62 GTW_w331_SWSRversionMismatch "Gateway: w331 SWS rversion mismatch";
CM_ SG_ 62 GTW_w332_unknownDisplayPN "Gateway: w332 unknown display PN";
CM_ SG_ 62 GTW_w334_hrlFolderSpaceLow "Gateway: w334 hrl folder space low";
CM_ SG_ 62 GTW_w336_possibleCanTxIssue "Gateway: w336 possible can tx issue";
CM_ SG_ 62 GTW_w342_VCBLDCPPversionMismatch "Gateway: w342 VCBLDCP pversion mismatch";
CM_ SG_ 62 GTW_w348_VCBLDCFversionMismatch "Gateway: w348 VCBLDC fversion mismatch";
CM_ SG_ 62 GTW_w349_VCBLDCPBversionMismatch "Gateway: w349 VCBLDCP bversion mismatch";
CM_ SG_ 62 GTW_w350_mOSDCrcCheck "Gateway: w350 m OSD crc check";
CM_ SG_ 62 GTW_w351_sOSDCrcCheck "Gateway: w351 s OSD crc check";
CM_ SG_ 62 GTW_w352_mASILStatusCheck "Gateway: w352 m ASIL status check";
CM_ SG_ 62 GTW_w353_sASILStatusCheck "Gateway: w353 s ASIL status check";
CM_ SG_ 62 GTW_w354_EPASTPversionMismatch "Gateway: w354 EPAST pversion mismatch";
CM_ SG_ 62 GTW_w355_EPASTSversionMismatch "Gateway: w355 EPAST sversion mismatch";
CM_ SG_ 62 GTW_w356_touchGPIOStatusCheck "Gateway: w356 touch GPIO status check";
CM_ SG_ 62 GTW_w358_RGBIPFLversionMismatch "Gateway: w358 RGBIPF lversion mismatch";
CM_ SG_ 62 GTW_w359_RGBIPFRversionMismatch "Gateway: w359 RGBIPF rversion mismatch";
CM_ SG_ 62 GTW_w360_RGBDOORFLversionMismatc "Gateway: w360 RGBDOORF lversion mismatch";
CM_ SG_ 62 GTW_w361_RGBDOORRLversionMismatc "Gateway: w361 RGBDOORR lversion mismatch";
CM_ SG_ 62 GTW_w362_RGBDOORFRversionMismatc "Gateway: w362 RGBDOORF rversion mismatch";
CM_ SG_ 62 GTW_w363_RGBDOORRRversionMismatc "Gateway: w363 RGBDOORR rversion mismatch";
CM_ SG_ 62 GTW_w364_BLEEPCRADLEversionMisma "Gateway: w364 BLEEPCRADL eversion mismatch";
CM_ SG_ 62 GTW_w366_uiGearRequestMismatch "Gateway: w366 ui gear request mismatch";
CM_ SG_ 62 GTW_w376_blFailedToExecBootImg "Gateway: w376 bl failed to exec boot img";
CM_ SG_ 62 GTW_w380_DPBversionMismatch "Gateway: w380 DP bversion mismatch";
CM_ SG_ 62 GTW_w381_DPBCALversionMismatch "Gateway: w381 DPBCA lversion mismatch";
CM_ SG_ 62 GTW_w382_IDBversionMismatch "Gateway: w382 ID bversion mismatch";
CM_ SG_ 62 GTW_w383_IDB1versionMismatch "Gateway: w383 idb1version mismatch";
CM_ SG_ 62 GTW_w384_IDBCALversionMismatch "Gateway: w384 IDBCA lversion mismatch";
CM_ SG_ 62 GTW_w385_RCUversionMismatch "Gateway: w385 RC uversion mismatch";
CM_ SG_ 62 GTW_w386_RCUCALversionMismatch "Gateway: w386 RCUCA lversion mismatch";
CM_ SG_ 62 GTW_w387_externalRtcReadFailure "Gateway: w387 external rtc read failure";
CM_ SG_ 62 GTW_w388_adspWatchdogSkipped "Gateway: w388 adsp watchdog skipped";
CM_ SG_ 62 GTW_w389_rcmEventDetected "Gateway: w389 rcm event detected";
CM_ SG_ 62 GTW_w391_adspMacAddrCheckFailed "Gateway: w391 adsp mac addr check failed";
CM_ SG_ 62 GTW_w393_osdSramCrcMismatch "Gateway: w393 osd sram crc mismatch";
CM_ SG_ 62 GTW_w395_lwipIcmpError "Gateway: w395 lwip icmp error";
CM_ SG_ 62 GTW_w396_alreadyInReverse "Gateway: w396 already in reverse";
CM_ SG_ 62 GTW_w397_alreadyInDrive "Gateway: w397 already in drive";
CM_ SG_ 62 GTW_w398_awakeForExtendedTime "Gateway: w398 awake for extended time";
CM_ SG_ 62 GTW_w399_ethIfRxTcpipQueueDrop "Gateway: w399 eth if rx tcpip queue drop";
CM_ SG_ 62 GTW_w400_ethlSwitchOTPIncorrect "Gateway: w400 ethl switch OTP incorrect";
CM_ SG_ 62 GTW_w409_unexpectedResetCause "Gateway: w409 unexpected reset cause";
CM_ SG_ 62 GTW_w410_unexpectedResetCause2 "Gateway: w410 unexpected reset cause2";
CM_ SG_ 62 GTW_w414_socHeldInReset "Gateway: w414 soc held in reset";
CM_ BO_ 838 "Gateway message: autopilot override";
CM_ SG_ 838 GTW_autopilotOverrideState "Signals whether an autopilot trial or subscription is active";
CM_ SG_ 838 GTW_autopilotConfig "Current level of permanent Autopilot firmware";
CM_ SG_ 838 GTW_autopilotOverrideConfig "Current level of trial or subscription Autopilot firmware";
CM_ SG_ 838 GTW_autopilotOverrideExpireTime "Expiration time for the currently active autopilot trial or subscription";
CM_ BO_ 904 "Gateway message: can status";
CM_ SG_ 904 GTW_VEH_canBusActivity "Active if any frame detected on the bus";
CM_ SG_ 904 GTW_PARTY_canBusActivity "Active if any frame detected on the bus";
CM_ SG_ 904 GTW_CH_canBusActivity "Active if any frame detected on the bus";
CM_ SG_ 904 GTW_VEH_txWarning "Gateway: VEH tx warning";
CM_ SG_ 904 GTW_PARTY_txWarning "Gateway: PARTY tx warning";
CM_ SG_ 904 GTW_CH_txWarning "Gateway: CH tx warning";
CM_ SG_ 904 GTW_VEH_rxWarning "Gateway: VEH rx warning";
CM_ SG_ 904 GTW_PARTY_rxWarning "Gateway: PARTY rx warning";
CM_ SG_ 904 GTW_CH_rxWarning "Gateway: CH rx warning";
CM_ SG_ 904 GTW_VEH_faultConfinement "Fault confinement as per CAN spec";
CM_ SG_ 904 GTW_PARTY_faultConfinement "Fault confinement as per CAN spec";
CM_ SG_ 904 GTW_CH_faultConfinement "Fault confinement as per CAN spec";
CM_ SG_ 904 GTW_BDY_canBusActivity "Active if any frame detected on the bus";
CM_ SG_ 904 GTW_BDY_txWarning "Gateway: BDY tx warning";
CM_ SG_ 904 GTW_BDY_rxWarning "Gateway: BDY rx warning";
CM_ SG_ 904 GTW_BDY_faultConfinement "Fault confinement as per CAN spec";
CM_ BO_ 2047 "Gateway message: car config";
CM_ SG_ 2047 GTW_carConfigMultiplexer "Gateway: car config multiplexer";
CM_ SG_ 2047 GTW_deliveryStatus "Indicates whether the vehicle has been marked delivered to the customer in Tesla backend systems.";
CM_ SG_ 2047 GTW_cabinPTCHeaterType "Gateway: cabin PTC heater type";
CM_ SG_ 2047 GTW_rightHandDrive "Gateway: right hand drive";
CM_ SG_ 2047 GTW_rearLightType "Gateway: rear light type";
CM_ SG_ 2047 GTW_headlamps "Gateway: headlamps";
CM_ SG_ 2047 GTW_country "Gateway: country";
CM_ SG_ 2047 GTW_tireType "Gateway: tire type";
CM_ SG_ 2047 GTW_roofGlassType "Gateway: roof glass type";
CM_ SG_ 2047 GTW_dasHw "Indicates the Driver Assistance System (DAS) hardware installed.";
CM_ SG_ 2047 GTW_brakeHWType "Gateway: brake HW type";
CM_ SG_ 2047 GTW_restraintsHardwareType "Gateway: restraints hardware type";
CM_ SG_ 2047 GTW_drivetrainType "Gateway: drivetrain type";
CM_ SG_ 2047 GTW_radarHeaterType "Gateway: radar heater type";
CM_ SG_ 2047 GTW_exteriorTrimType "Gateway: exterior trim type";
CM_ SG_ 2047 GTW_frontSeatHeaters "Gateway: front seat heaters";
CM_ SG_ 2047 GTW_rearSeatHeaters "Gateway: rear seat heaters";
CM_ SG_ 2047 GTW_eCallAntennaHW "Gateway: e call antenna HW";
CM_ SG_ 2047 GTW_homelinkType "Gateway: homelink type";
CM_ SG_ 2047 GTW_vdcType "Gateway: vdc type";
CM_ SG_ 2047 GTW_memoryMirrors "Gateway: memory mirrors";
CM_ SG_ 2047 GTW_powerLiftgateType "Gateway: power liftgate type";
CM_ SG_ 2047 GTW_lumbarECUType "Gateway: lumbar ECU type";
CM_ SG_ 2047 GTW_rearSeatHeaterType "Gateway: rear seat heater type";
CM_ SG_ 2047 GTW_auxParkLamps "Gateway: aux park lamps";
CM_ SG_ 2047 GTW_interiorCabinRadarType "Gateway: interior cabin radar type";
CM_ SG_ 2047 GTW_hvacPanelVaneType "Gateway: hvac panel vane type";
CM_ SG_ 2047 GTW_intakeAirFilterType "Gateway: intake air filter type";
CM_ SG_ 2047 GTW_eBuckConfig "Gateway: e buck config";
CM_ SG_ 2047 GTW_steeringHeaterEnabled "Gateway: steering heater enabled";
CM_ SG_ 2047 GTW_activeHighBeam "Gateway: active high beam";
CM_ SG_ 2047 GTW_airbagCutoffSwitch "Gateway: airbag cutoff switch";
CM_ SG_ 2047 GTW_intrusionSensorType "Gateway: intrusion sensor type";
CM_ SG_ 2047 GTW_spoilerType "Gateway: spoiler type";
CM_ SG_ 2047 GTW_rearFogLamps "Gateway: rear fog lamps";
CM_ SG_ 2047 GTW_roofType "Gateway: roof type";
CM_ SG_ 2047 GTW_thirdRowSeatType "Gateway: third row seat type";
CM_ SG_ 2047 GTW_autopilot "Gateway: autopilot";
CM_ SG_ 2047 GTW_superchargingAccess "Gateway: supercharging access";
CM_ SG_ 2047 GTW_exteriorColor "Gateway: exterior color";
CM_ SG_ 2047 GTW_pedestrianWarningSound "Gateway: pedestrian warning sound";
CM_ SG_ 2047 GTW_steeringColumnUJointType "Gateway: steering column u joint type";
CM_ SG_ 2047 GTW_bPillarNFCParam "Gateway: b pillar NFC param";
CM_ SG_ 2047 GTW_interiorLighting "Gateway: interior lighting";
CM_ SG_ 2047 GTW_headlightLevelerType "Gateway: headlight leveler type";
CM_ SG_ 2047 GTW_numberHVILNodes "Gateway: number HVIL nodes";
CM_ SG_ 2047 GTW_mapRegion "Gateway: map region";
CM_ SG_ 2047 GTW_performancePackage "Gateway: performance package";
CM_ SG_ 2047 GTW_chassisType "Indicates the chassis type, which determines physical aspects such as suspension geometry, track width, wheel base, baseline tire size, and trailer capability.";
CM_ SG_ 2047 GTW_airSuspension "Gateway: air suspension";
CM_ SG_ 2047 GTW_centerConsoleControllerType "Gateway: center console controller type";
CM_ SG_ 2047 GTW_autopilotCameraType "Gateway: autopilot camera type";
CM_ SG_ 2047 GTW_connectivityPackage "Gateway: connectivity package";
CM_ SG_ 2047 GTW_plcSupportType "Gateway: plc support type";
CM_ SG_ 2047 GTW_packEnergy "Gateway: pack energy";
CM_ SG_ 2047 GTW_frontSeatReclinerHardware "Gateway: front seat recliner hardware";
CM_ SG_ 2047 GTW_brakeLineSwitchType "Gateway: brake line switch type";
CM_ SG_ 2047 GTW_espValveType "Gateway: esp valve type";
CM_ SG_ 2047 GTW_softRange "Gateway: soft range";
CM_ SG_ 2047 GTW_refrigerantType "Gateway: refrigerant type";
CM_ SG_ 2047 GTW_wheelType "Gateway: wheel type";
CM_ SG_ 2047 GTW_ptcControlMode "Gateway: ptc control mode";
CM_ SG_ 2047 GTW_brakeActuationType "Gateway: brake actuation type";
CM_ SG_ 2047 GTW_secondRowSeatType "Gateway: second row seat type";
CM_ SG_ 2047 GTW_secondRowSeatMotorType "Gateway: second row seat motor type";
CM_ SG_ 2047 GTW_birthday "Gateway: birthday";
CM_ SG_ 2047 GTW_eCallEnabled "Gateway: e call enabled";
CM_ SG_ 2047 GTW_parkAssistECUType "Gateway: park assist ECU type";
CM_ SG_ 2047 GTW_passengerAirbagType "Gateway: passenger airbag type";
CM_ SG_ 2047 GTW_forwardRadarHw "Gateway: forward radar hw";
CM_ SG_ 2047 GTW_frontSeatType "Gateway: front seat type";
CM_ SG_ 2047 GTW_secondRowDisplayType "Gateway: second row display type";
CM_ SG_ 2047 GTW_wirelessPhoneChargerType "Gateway: wireless phone charger type";
CM_ SG_ 2047 GTW_ethernetTunerType "Gateway: ethernet tuner type";
CM_ SG_ 2047 GTW_interiorTrimType "Gateway: interior trim type";
CM_ SG_ 2047 GTW_gloveboxUSBType "Gateway: glovebox USB type";
CM_ SG_ 2047 GTW_coolantPumpType "Gateway: coolant pump type";
CM_ SG_ 2047 GTW_epblHwType "Gateway: epbl hw type";
CM_ SG_ 2047 GTW_epbrHwType "Gateway: epbr hw type";
CM_ SG_ 2047 GTW_blowerMotorType "Gateway: blower motor type";
CM_ SG_ 2047 GTW_rearLeftBLEEndpointParameter "Gateway: rear left BLE endpoint parameter type";
CM_ SG_ 2047 GTW_frontUsbHubType "Gateway: front usb hub type";
CM_ SG_ 2047 GTW_superManifoldType "Type of HVAC super manifold installed";
CM_ SG_ 2047 GTW_rcmLocation "Gateway: rcm location";
CM_ SG_ 2047 GTW_interiorCamFanType "Gateway: interior cam fan type";
CM_ SG_ 2047 GTW_interiorCamBeautyCoverType "Gateway: interior cam beauty cover type";
CM_ SG_ 2047 GTW_sirenType "Gateway: siren type";
CM_ SG_ 2047 GTW_hornType "Gateway: horn type";
CM_ SG_ 2047 GTW_badgingVersion "Gateway: badging version";
CM_ SG_ 2047 GTW_steeringColumnMotorType "Gateway: steering column motor type";
CM_ SG_ 2047 GTW_refrigACLineType "Gateway: refrig AC line type";
CM_ SG_ 2047 GTW_refrigFilterType "Gateway: refrig filter type";
CM_ SG_ 2047 GTW_diBurnInType "Gateway: di burn in type";
CM_ SG_ 2047 GTW_specialBadgingType "Gateway: special badging type";
CM_ SG_ 2047 GTW_chassisSubType "Reports chassis sub-variant type.";
CM_ SG_ 2047 GTW_frontSeatVentilationType "Gateway: front seat ventilation type";
CM_ SG_ 2047 GTW_towPackage "Gateway: tow package";
CM_ SG_ 2047 GTW_refrigLccType "Gateway: refrig lcc type";
CM_ SG_ 2047 GTW_caliperColorType "Gateway: caliper color type";
CM_ SG_ 2047 GTW_wiperMotorType "Gateway: wiper motor type";
CM_ SG_ 2047 GTW_frontOverheadConsoleType "Gateway: front overhead console type";
CM_ SG_ 2047 GTW_shifterType "Gateway: shifter type";
CM_ SG_ 2047 GTW_compressorType "Gateway: compressor type";
CM_ SG_ 2047 GTW_twelveVBatteryType "Gateway: twelve v battery type";
CM_ SG_ 2047 GTW_efuseSWConfig "Gateway: efuse SW config";
CM_ SG_ 2047 GTW_tollCollectionModuleType "Gateway: toll collection module type";
CM_ SG_ 2047 GTW_bleEndpointUpdateMethod "Gateway: ble endpoint update method";
CM_ SG_ 2047 GTW_steeringWheelControllerType "Gateway: steering wheel controller type";
CM_ SG_ 2047 GTW_frontSeatVentilationEnabled "Gateway: front seat ventilation enabled";
CM_ SG_ 2047 GTW_gloveboxActuatorType "Gateway: glovebox actuator type";
CM_ SG_ 2047 GTW_epasType "Gateway: epas type";
CM_ SG_ 2047 GTW_homologationRegionOverride "Gateway: homologation region override";
CM_ SG_ 2047 GTW_windowCommandsPermissionType "Gateway: window commands permission type";
CM_ SG_ 2047 GTW_headlightStepperStallDetectM "Gateway: headlight stepper stall detect mode";
CM_ SG_ 2047 GTW_rgbInteriorLightingEnabled "Gateway: rgb interior lighting enabled";
CM_ SG_ 2047 GTW_windshieldWiperHeaterType "Gateway: windshield wiper heater type";
CM_ SG_ 2047 GTW_driveInterfaceType "Gateway: drive interface type";
CM_ SG_ 2047 GTW_efficiencyPackage "Gateway: efficiency package";
CM_ SG_ 2047 GTW_visorLightType "Gateway: visor light type";
CM_ SG_ 2047 GTW_gnssAntennaType "Gateway: gnss antenna type";
CM_ SG_ 2047 GTW_frontSeatHeatersEnabled "Gateway: front seat heaters enabled";
CM_ SG_ 2047 GTW_windshieldWiperHeaterEnabled "Gateway: windshield wiper heater enabled";
CM_ SG_ 2047 GTW_tcuType "Gateway: tcu type";
CM_ SG_ 2047 GTW_fasciaType "Gateway: fascia type";
CM_ SG_ 2047 GTW_powerSteeringColumn "Gateway: power steering column";
CM_ SG_ 2047 GTW_frontSeatHeaterType "Gateway: front seat heater type";
CM_ SG_ 2047 GTW_softPerformanceLimit "Gateway: soft performance limit";
CM_ SG_ 2047 GTW_alcoholInterlockType "Gateway: alcohol interlock type";
CM_ SG_ 2047 GTW_immersiveAudio "Gateway: immersive audio";
CM_ SG_ 2047 GTW_passengerOccupancySensorType "Gateway: passenger occupancy sensor type";
CM_ SG_ 2047 GTW_packPerformanceDeviation "Measures deviation from standard pack mass or power output capability associated with the vehicle packEnergy configuration.";
CM_ SG_ 2047 GTW_frontFogLamps "Gateway: front fog lamps";
CM_ SG_ 2047 GTW_driverOccupancySensorType "Gateway: driver occupancy sensor type";
CM_ SG_ 2047 GTW_audioType "Gateway: audio type";
CM_ SG_ 2047 GTW_occupancyClassificationFeatu "Gateway: occupancy classification feature type";
CM_ SG_ 2047 GTW_domeLightType "Gateway: dome light type";
CM_ SG_ 2047 GTW_tpmsType "Gateway: tpms type";
CM_ SG_ 2047 GTW_authenticationEndpointLayout "Gateway: authentication endpoint layout";
CM_ SG_ 2047 GTW_socSleepOverride "Gateway: soc sleep override";
CM_ SG_ 2047 GTW_r79BehaviorOverride "Gateway: r79 behavior override";
CM_ SG_ 2047 GTW_steeringHeaterType "Gateway: steering heater type";
CM_ SG_ 2047 GTW_sohRegulatoryStatus "Gateway: soh regulatory status";
CM_ SG_ 2047 GTW_m3yBusArchitecture "Reports notable features of vehicle communication bus architecture. Used for firmware artifact selection during update installation process.";
CM_ SG_ 2047 GTW_blindSpotIndicatorLightType "Gateway: blind spot indicator light type";
CM_ SG_ 2047 GTW_hvacCaseDoorType "Gateway: hvac case door type";
CM_ SG_ 2047 GTW_occupancyDetectionSourceRequ "Gateway: occupancy detection source request";
CM_ SG_ 2047 GTW_rduCableType "Indicates type of rear drive unit cable installed on vehicle.";
CM_ SG_ 2047 GTW_interiorCameraType "Gateway: interior camera type";
CM_ SG_ 2047 GTW_frontFasciaCameraType "Reports type of forward facing fascia camera installed.";
CM_ BO_ 792 "Gateway message: car state";
CM_ SG_ 792 GTW_factoryGated "Gateway: factory gated";
CM_ BO_ 1638 "Gateway message: diag session";
CM_ SG_ 1638 GTW_diagRemainingSeconds "Seconds remaining for the diagnostics session";
CM_ SG_ 1638 GTW_diagSessionActive "UDS Session Active";
CM_ SG_ 1638 GTW_diagLevel "Current diagnostics level";
CM_ SG_ 1638 GTW_diagUnlockProcedureActive "GTW diag unlock procedure active";
CM_ SG_ 1638 GTW_diagOverrideActive "GTW diag level override active";
CM_ SG_ 1638 GTW_diagPhysicalLinkEstablished "Physical diag cable connected to the switch and link established";
CM_ BO_ 1080 "Gateway message: eth nm";
CM_ SG_ 1080 GTW_ethGotoSleep "ETH bus sleep commanded";
CM_ SG_ 1080 GTW_ethWakeUpBus "Gateway: eth wake up bus";
CM_ SG_ 1080 GTW_vehBusAsleep "VEH bus sleep state";
CM_ SG_ 1080 GTW_ethHeartBeatCounter "Gateway: eth heart beat counter";
CM_ SG_ 1080 GTW_ethWakeUpReason "Tracks the cause of why the gateway wakes up the ethernet bus";
CM_ BO_ 1376 "Gateway message: factory ecu present";
CM_ SG_ 1376 GTW_OCS1Ppresent "Gateway: OCS1 ppresent";
CM_ SG_ 1376 GTW_PCSpresent "Gateway: PC spresent";
CM_ SG_ 1376 GTW_HVPpresent "Gateway: HV ppresent";
CM_ SG_ 1376 GTW_BMSpresent "Gateway: BM spresent";
CM_ SG_ 1376 GTW_CPpresent "Gateway: c ppresent";
CM_ SG_ 1376 GTW_RCMpresent "Gateway: RC mpresent";
CM_ SG_ 1376 GTW_SCCMpresent "Gateway: SCC mpresent";
CM_ SG_ 1376 GTW_VCSECpresent "Gateway: VCSE cpresent";
CM_ SG_ 1376 GTW_EPAS3Ppresent "Gateway: EPAS3 ppresent";
CM_ SG_ 1376 GTW_EPBLpresent "Gateway: EPB lpresent";
CM_ SG_ 1376 GTW_EPBRpresent "Gateway: EPB rpresent";
CM_ SG_ 1376 GTW_ESPpresent "Gateway: ES ppresent";
CM_ SG_ 1376 GTW_IBSTpresent "Gateway: IBS tpresent";
CM_ SG_ 1376 GTW_PARKpresent "Gateway: PAR kpresent";
CM_ SG_ 1376 GTW_RADCpresent "Gateway: RAD cpresent";
CM_ SG_ 1376 GTW_TPMSpresent "Gateway: TPM spresent";
CM_ SG_ 1376 GTW_VCFRONTpresent "Gateway: VCFRON tpresent";
CM_ SG_ 1376 GTW_VCLEFTpresent "Gateway: VCLEF tpresent";
CM_ SG_ 1376 GTW_VCRIGHTpresent "Gateway: VCRIGH tpresent";
CM_ SG_ 1376 GTW_EPAS3Spresent "Gateway: EPAS3 spresent";
CM_ SG_ 1376 GTW_CMPpresent "Gateway: CM ppresent";
CM_ SG_ 1376 GTW_DASpresent "Gateway: DA spresent";
CM_ SG_ 1376 GTW_PTCpresent "Gateway: PT cpresent";
CM_ SG_ 1376 GTW_SWCpresent "Gateway: SW cpresent";
CM_ SG_ 1376 GTW_PMRpresent "Gateway: PM rpresent";
CM_ SG_ 1376 GTW_PMFpresent "Gateway: PM fpresent";
CM_ SG_ 1376 GTW_DIRpresent "Gateway: DI rpresent";
CM_ SG_ 1376 GTW_DIFpresent "Gateway: DI fpresent";
CM_ BO_ 1656 "Gateway message: gear control";
CM_ SG_ 1656 GTW_gearControlChecksum "Gateway: gear control checksum";
CM_ SG_ 1656 GTW_gearControlCounter "Gateway: gear control counter";
CM_ SG_ 1656 GTW_gearShiftRequest "Request to change gear state from center display UI control; raw 0 = signal not available (SNA)";
CM_ SG_ 1656 GTW_osdActive "Whether OSD is active";
CM_ SG_ 1656 GTW_primaryGearControlStatus "Status of the center display UI control";
CM_ SG_ 1656 GTW_gearStripEnable "UI control for showing and or activating the primary gear strip interface";
CM_ SG_ 1656 GTW_showNeutralButton "Tell UI that it is time to animate the N button to be shown";
CM_ SG_ 1656 GTW_showAutoParkButton "Tell UI that it is time to animate the autopark button to be shown";
CM_ SG_ 1656 GTW_autoParkRequest "Request to auto park from center display UI control";
CM_ SG_ 1656 GTW_smartShiftStatus "Based on the status of the infotainment system smart shift feature should be disabled; raw 0 = signal not available (SNA)";
CM_ SG_ 1656 GTW_processingRDgestures "Is GTW processing R and D swipe gestures";
CM_ SG_ 1656 GTW_processingTapPgestures "Is GTW processing contextual tap-to-park gestures";
CM_ SG_ 1656 GTW_gearStripChangeReason "Gateway: gear strip change reason; raw 0 = signal not available (SNA)";
CM_ SG_ 1656 GTW_touchActive "User present as touch on display is active";
CM_ SG_ 1656 GTW_steamOff "Let UI know to turn Steam off";
CM_ SG_ 1656 GTW_screenPCBTemperature "Reading from display i2c temperature sensor; raw 2047 = signal not available (SNA)";
CM_ BO_ 2033 "Gateway message: hrl";
CM_ SG_ 2033 GTW_hrlIndex "Gateway: hrl index";
CM_ SG_ 2033 GTW_hrlState "GTW hrl state";
CM_ SG_ 2033 GTW_hrlTriggerDuration "HRL duration";
CM_ SG_ 2033 GTW_hrlTriggerType "HRL trigger type";
CM_ SG_ 2033 GTW_hrlTriggerId "HRL trigger ID. A unique ID representing the signal conditions causing the HRL event to occur.";
CM_ SG_ 2033 GTW_hrlTriggerBus "Gateway: hrl trigger bus";
CM_ BO_ 60 "Gateway message: info";
CM_ SG_ 60 GTW_infoIndex "Gateway: info index";
CM_ SG_ 60 GTW_buildType "Gateway: build type";
CM_ SG_ 60 GTW_hardwareId "GTW hardware ID";
CM_ SG_ 60 GTW_platformType "Gateway: platform type";
CM_ SG_ 60 GTW_appCrc "Gateway: app crc";
CM_ SG_ 60 GTW_applicationGitHash "Gateway: application git hash";
CM_ SG_ 60 GTW_bootGitHash "Gateway: boot git hash";
CM_ BO_ 1370 "Gateway message: mismatch fault";
CM_ SG_ 1370 GTW_mismatchFaultIndex "Gateway: mismatch fault index";
CM_ SG_ 1370 GTW_mismatchFaultChecksum "Gateway: mismatch fault checksum";
CM_ SG_ 1370 GTW_mismatchFaultCounter "Gateway: mismatch fault counter";
CM_ SG_ 1370 GTW_GTWmismatchFault "Reports the Gateway (GTW) running a firmware version that does not match the rest of the vehicle";
CM_ SG_ 1370 GTW_BMSmismatchFault "Reports the high voltage Battery Management System (BMS) electronic control unit (ECU) running a firmware version that does not match the rest of the vehicle";
CM_ SG_ 1370 GTW_APSmismatchFault "Reports the Autopilot Processor Secondary (APS) electronic control unit (ECU) running a firmware version that does not match the rest of the vehicle";
CM_ SG_ 1370 GTW_BLEEPCENTERmismatchFault "Reports the Bluetooth Low Energy End Point Center (BLEEPCENTER) electronic control unit (ECU) running a firmware version that does not match the rest of the vehicle";
CM_ SG_ 1370 GTW_BLEEPLEFTmismatchFault "Reports the Bluetooth Low Energy End Point Left (BLEEPLEFT) electronic control unit (ECU) running a firmware version that does not match the rest of the vehicle";
CM_ SG_ 1370 GTW_BLEEPREARmismatchFault "Reports the Bluetooth Low Energy End Point Rear (BLEEPREAR) electronic control unit (ECU) running a firmware version that does not match the rest of the vehicle";
CM_ SG_ 1370 GTW_BLEEPRIGHTmismatchFault "Reports the Bluetooth Low Energy End Point Right (BLEEPRIGHT) electronic control unit (ECU) running a firmware version that does not match the rest of the vehicle";
CM_ SG_ 1370 GTW_CBCmismatchFault "Reports the Cabin Blower Controller (CBC) electronic control unit (ECU) running a firmware version that does not match the rest of the vehicle";
CM_ SG_ 1370 GTW_CMPmismatchFault "Reports the air conditioning compressor (CMP) electronic control unit (ECU) running a firmware version that does not match the rest of the vehicle";
CM_ SG_ 1370 GTW_CPmismatchFault "Reports the Charge Port (CP) electronic control unit (ECU) running a firmware version that does not match the rest of the vehicle";
CM_ SG_ 1370 GTW_DIFmismatchFault "Reports the front drive inverter (DIF) electronic control unit (ECU) running a firmware version that does not match the rest of the vehicle";
CM_ SG_ 1370 GTW_DIRmismatchFault "Reports the rear drive inverter (DIR) electronic control unit (ECU) running a firmware version that does not match the rest of the vehicle";
CM_ SG_ 1370 GTW_EPAS3PmismatchFault "Reports the primary Electronic Power Assisted Steering (EPAS3P) electronic control unit (ECU) running a firmware version that does not match the rest of the vehicle";
CM_ SG_ 1370 GTW_EPAS3SmismatchFault "Reports the secondary Electronic Power Assisted Steering (EPAS3S) electronic control unit (ECU) running a firmware version that does not match the rest of the vehicle";
CM_ SG_ 1370 GTW_EPBLmismatchFault "Reports the left Electronic Park Brake (EPBL) electronic control unit (ECU) running a firmware version that does not match the rest of the vehicle";
CM_ SG_ 1370 GTW_EPBRmismatchFault "Reports the right Electronic Park Brake (EPBR) electronic control unit (ECU) running a firmware version that does not match the rest of the vehicle";
CM_ SG_ 1370 GTW_ESPCALmismatchFault "Reports the Electronic Stability Program Calibration (ESPCAL) electronic control unit (ECU) running a firmware version that does not match the rest of the vehicle";
CM_ SG_ 1370 GTW_ESPmismatchFault "Reports the Electronic Stability Program (ESP) electronic control unit (ECU) running a firmware version that does not match the rest of the vehicle";
CM_ SG_ 1370 GTW_HCM3LmismatchFault "Reports the left LED matrix Headlamp Control Module (HCM3L) electronic control unit (ECU) running a firmware version that does not match the rest of the vehicle";
CM_ SG_ 1370 GTW_HCM3RmismatchFault "Reports the right LED matrix Headlamp Control Module (HCM3R) electronic control unit (ECU) running a firmware version that does not match the rest of the vehicle";
CM_ SG_ 1370 GTW_HCMLmismatchFault "Reports the left Headlamp Control Module (HCML) electronic control unit (ECU) running a firmware version that does not match the rest of the vehicle";
CM_ SG_ 1370 GTW_HCMRmismatchFault "Reports the right Headlamp Control Module (HCMR) electronic control unit (ECU) running a firmware version that does not match the rest of the vehicle";
CM_ SG_ 1370 GTW_HVPmismatchFault "Reports the High Voltage Processor (HVP) electronic control unit (ECU) running a firmware version that does not match the rest of the vehicle";
CM_ SG_ 1370 GTW_IBSTCALmismatchFault "Reports the electromechanical brake booster calibration, or iBooster Calibration (IBSTCAL), electronic control unit (ECU) running a firmware version that does not match the rest of the vehicle";
CM_ SG_ 1370 GTW_IBSTmismatchFault "Reports the electromechanical brake booster, or iBooster (IBST), electronic control unit (ECU) running a firmware version that does not match the rest of the vehicle";
CM_ SG_ 1370 GTW_LVBMSmismatchFault "Reports the Low Voltage Battery Management System (LVBMS) electronic control unit (ECU) running a firmware version that does not match the rest of the vehicle";
CM_ SG_ 1370 GTW_OCS1PmismatchFault "Reports the Occupancy Classification System - 1st Row Passenger (OCS1P) electronic control unit (ECU) running a firmware version that does not match the rest of the vehicle";
CM_ SG_ 1370 GTW_OPCFmismatchFault "Reports the front Oil Pump Controller (OPCF) electronic control unit (ECU) running a firmware version that does not match the rest of the vehicle";
CM_ SG_ 1370 GTW_OPCRmismatchFault "Reports the rear Oil Pump Controller (OPCR) electronic control unit (ECU) running a firmware version that does not match the rest of the vehicle";
CM_ SG_ 1370 GTW_PARKmismatchFault "Reports the Park Assist (PARK) electronic control unit (ECU) running a firmware version that does not match the rest of the vehicle";
CM_ SG_ 1370 GTW_PCSCPU2mismatchFault "Reports the Power Conversion System AC charging core (PCSCPU2) electronic control unit (ECU) running a firmware version that does not match the rest of the vehicle";
CM_ SG_ 1370 GTW_PCSmismatchFault "Reports the Power Conversion System (PCS) electronic control unit (ECU) running a firmware version that does not match the rest of the vehicle";
CM_ SG_ 1370 GTW_PMFmismatchFault "Reports the front Pedal Monitor (PMF) electronic control unit (ECU) running a firmware version that does not match the rest of the vehicle";
CM_ SG_ 1370 GTW_PMRmismatchFault "Reports the rear Pedal Monitor (PMR) electronic control unit (ECU) running a firmware version that does not match the rest of the vehicle";
CM_ SG_ 1370 GTW_PTCmismatchFault "Reports the Positive Temperature Coefficient (PTC) heater electronic control unit (ECU) running a firmware version that does not match the rest of the vehicle";
CM_ SG_ 1370 GTW_RCMCALmismatchFault "Reports the Restraint Control Module Calibration (RCMCAL) electronic control unit (ECU) running a firmware version that does not match the rest of the vehicle";
CM_ SG_ 1370 GTW_RCMmismatchFault "Reports the Restraint Control Module (RCM) electronic control unit (ECU) running a firmware version that does not match the rest of the vehicle";
CM_ SG_ 1370 GTW_SCCMmismatchFault "Reports the Steering Column Control Module (SCCM) electronic control unit (ECU) running a firmware version that does not match the rest of the vehicle";
CM_ SG_ 1370 GTW_SDCRmismatchFault "Reports the Secondary Disconnect Controller (SDCR) electronic control unit (ECU) running a firmware version that does not match the rest of the vehicle";
CM_ SG_ 1370 GTW_SWCmismatchFault "Reports the Steering Wheel Controller (SWC) electronic control unit (ECU) running a firmware version that does not match the rest of the vehicle";
CM_ SG_ 1370 GTW_THSmismatchFault "Reports the Temperature Humidity Sensor (THS) electronic control unit (ECU) running a firmware version that does not match the rest of the vehicle";
CM_ SG_ 1370 GTW_VCFRONTmismatchFault "Reports the front vehicle controller (VCFRONT) electronic control unit (ECU) running a firmware version that does not match the rest of the vehicle";
CM_ SG_ 1370 GTW_VCLEFTmismatchFault "Reports the left vehicle controller (VCLEFT) electronic control unit (ECU) running a firmware version that does not match the rest of the vehicle";
CM_ SG_ 1370 GTW_VCRIGHTmismatchFault "Reports the right vehicle controller (VCRIGHT) electronic control unit (ECU) running a firmware version that does not match the rest of the vehicle";
CM_ SG_ 1370 GTW_VCSECmismatchFault "Reports the vehicle security controller (VCSEC) electronic control unit (ECU) running a firmware version that does not match the rest of the vehicle";
CM_ SG_ 1370 GTW_PMmismatchFault "Reports the Pedal Monitor (PM) electronic control unit (ECU) running a firmware version that does not match the rest of the vehicle";
CM_ BO_ 840 "Gateway message: status";
CM_ SG_ 840 GTW_vehicleVersionMatchStatus "Signal to indicate if the vehicle ECUs are all on a matched production version";
CM_ SG_ 840 GTW_hwtype "Describes the chip GTW is running on; raw 0 = signal not available (SNA)";
CM_ SG_ 840 GTW_jcanProductName "Describes the JCAN reference (product) name; raw 0 = signal not available (SNA)";
CM_ SG_ 840 GTW_uptimeSeconds "GTW uptime in seconds";
CM_ SG_ 840 GTW_boardRevision "Board revision ID of the MCU PCBA";
CM_ SG_ 840 GTW_sentryModeState "Sentry Mode state; raw 6 = signal not available (SNA)";
CM_ SG_ 840 GTW_socSleepType "Describes the sleep type GTW is expecting from the SoC; raw 0 = signal not available (SNA)";
CM_ SG_ 840 GTW_resetType "Describes the type of reset GTW experienced; raw 0 = signal not available (SNA)";
CM_ BO_ 1005 "Gateway message: update status";
CM_ SG_ 1005 GTW_i2cUpdateActive "Gateway: i2c update active";
CM_ SG_ 1005 GTW_ecuUpdateStarted "Reports whether Electronic Control Unit (ECU) update phase is active.";
CM_ SG_ 1005 GTW_updateStarted "Main update in progress bit";
CM_ BO_ 1112 "Gateway message: veh nm";
CM_ SG_ 1112 GTW_nmGoingToSleep "Network management - Going to sleep state";
CM_ SG_ 1112 GTW_nmWakeUpBus "Gateway: nm wake up bus";
CM_ SG_ 1112 GTW_chBusAsleep "Chassis bus sleep state";
CM_ SG_ 1112 GTW_ethBusAsleep "ETH bus sleep state";
CM_ SG_ 1112 GTW_nmKeepAwakeReason "Network management - Keep awake reason; raw 0 = signal not available (SNA)";
CM_ SG_ 1112 GTW_nmWakeUpReason "Network management - Wakeup reason";
CM_ SG_ 1112 GTW_ethKeepAwakeReason "Reason GTW is keeping ETH bus awake; raw 0 = signal not available (SNA)";
CM_ SG_ 1112 GTW_nmDebugWakeUp "Gateway: nm debug wake up";
CM_ SG_ 1112 GTW_OTAKeepAwake "Signals that the vehicle buses should remain awake for an ongoing OTA update";
CM_ SG_ 1112 GTW_smsPokeReceived "The modem indicated it received an SMS poke";
CM_ SG_ 1112 GTW_bdyBusAsleep "BDY bus sleep state";
CM_ BO_ 1290 "High-voltage processor (pack contactor and isolation controller) message: alert log";
CM_ SG_ 1290 HVP_alertID "High-voltage processor (pack contactor and isolation controller): alert ID";
CM_ SG_ 1290 HVP_alertSet "High-voltage processor (pack contactor and isolation controller): alert set";
CM_ SG_ 1290 HVP_a005_current "High-voltage processor (pack contactor and isolation controller): a005 current";
CM_ SG_ 1290 HVP_a006_current "High-voltage processor (pack contactor and isolation controller): a006 current";
CM_ SG_ 1290 HVP_a007_current "High-voltage processor (pack contactor and isolation controller): a007 current";
CM_ SG_ 1290 HVP_a008_temperature "High-voltage processor (pack contactor and isolation controller): a008 temperature";
CM_ SG_ 1290 HVP_a008_sensorId "High-voltage processor (pack contactor and isolation controller): a008 sensor id";
CM_ SG_ 1290 HVP_a008_primaryChainSensor "High-voltage processor (pack contactor and isolation controller): a008 primary chain sensor";
CM_ SG_ 1290 HVP_a009_brickVoltage "High-voltage processor (pack contactor and isolation controller): a009 brick voltage";
CM_ SG_ 1290 HVP_a009_brickId "High-voltage processor (pack contactor and isolation controller): a009 brick id";
CM_ SG_ 1290 HVP_a009_primaryChainSensor "High-voltage processor (pack contactor and isolation controller): a009 primary chain sensor";
CM_ SG_ 1290 HVP_a010_brickVoltage "High-voltage processor (pack contactor and isolation controller): a010 brick voltage";
CM_ SG_ 1290 HVP_a010_brickId "High-voltage processor (pack contactor and isolation controller): a010 brick id";
CM_ SG_ 1290 HVP_a010_primaryChainSensor "High-voltage processor (pack contactor and isolation controller): a010 primary chain sensor";
CM_ SG_ 1290 HVP_a012_breakLocationA "High-voltage processor (pack contactor and isolation controller): a012 break location a";
CM_ SG_ 1290 HVP_a012_bmbCommStatusTypeA "High-voltage processor (pack contactor and isolation controller): a012 bmb comm status type a";
CM_ SG_ 1290 HVP_a012_breakLocationB "High-voltage processor (pack contactor and isolation controller): a012 break location b";
CM_ SG_ 1290 HVP_a012_bmbCommStatusTypeB "High-voltage processor (pack contactor and isolation controller): a012 bmb comm status type b";
CM_ SG_ 1290 HVP_a013_breakLocationA "High-voltage processor (pack contactor and isolation controller): a013 break location a";
CM_ SG_ 1290 HVP_a013_bmbCommStatusTypeA "High-voltage processor (pack contactor and isolation controller): a013 bmb comm status type a";
CM_ SG_ 1290 HVP_a013_breakLocationB "High-voltage processor (pack contactor and isolation controller): a013 break location b";
CM_ SG_ 1290 HVP_a013_bmbCommStatusTypeB "High-voltage processor (pack contactor and isolation controller): a013 bmb comm status type b";
CM_ SG_ 1290 HVP_a013_bmbChainBreakType "High-voltage processor (pack contactor and isolation controller): a013 bmb chain break type";
CM_ SG_ 1290 HVP_a018_dcLinkVoltage "High-voltage processor (pack contactor and isolation controller): a018 dc link voltage";
CM_ SG_ 1290 HVP_a018_battery12V "High-voltage processor (pack contactor and isolation controller): a018 battery12 v";
CM_ SG_ 1290 HVP_a018_remainingPcsPowerCycles "High-voltage processor (pack contactor and isolation controller): a018 remaining pcs power cycles allowed";
CM_ SG_ 1290 HVP_a018_remainingPcsRecoveriesA "High-voltage processor (pack contactor and isolation controller): a018 remaining pcs recoveries allowed";
CM_ SG_ 1290 HVP_a018_hvcHardwareSupportsCycl "High-voltage processor (pack contactor and isolation controller): a018 hvc hardware supports cycling";
CM_ SG_ 1290 HVP_a018_pcsHardwareOkToBePowerC "High-voltage processor (pack contactor and isolation controller): a018 pcs hardware ok to be power cycled";
CM_ SG_ 1290 HVP_a018_gpioLogicPowerEnable "High-voltage processor (pack contactor and isolation controller): a018 gpio logic power enable";
CM_ SG_ 1290 HVP_a018_gpioDcDcEnable "High-voltage processor (pack contactor and isolation controller): a018 gpio dc dc enable";
CM_ SG_ 1290 HVP_a018_gpioChgEnable "High-voltage processor (pack contactor and isolation controller): a018 gpio chg enable";
CM_ SG_ 1290 HVP_a020_energyReserveV "High-voltage processor (pack contactor and isolation controller): a020 energy reserve v; raw 65535 = signal not available (SNA)";
CM_ SG_ 1290 HVP_a020_shuntCurrentAux "High-voltage processor (pack contactor and isolation controller): a020 shunt current aux; raw 32768 = signal not available (SNA)";
CM_ SG_ 1290 HVP_a020_shuntTemperature "High-voltage processor (pack contactor and isolation controller): a020 shunt temperature; raw 32768 = signal not available (SNA)";
CM_ SG_ 1290 HVP_a021_pyroStatus "High-voltage processor (pack contactor and isolation controller): a021 pyro status";
CM_ SG_ 1290 HVP_a021_ErTestFailed "High-voltage processor (pack contactor and isolation controller): a021 er test failed";
CM_ SG_ 1290 HVP_a021_HighSideSwitchTestFaile "High-voltage processor (pack contactor and isolation controller): a021 high side switch test failed";
CM_ SG_ 1290 HVP_a021_LowSideSwitchTestFailed "High-voltage processor (pack contactor and isolation controller): a021 low side switch test failed";
CM_ SG_ 1290 HVP_a021_RefCurrentTestFailed "High-voltage processor (pack contactor and isolation controller): a021 ref current test failed";
CM_ SG_ 1290 HVP_a021_PyroLeakTestFailed "High-voltage processor (pack contactor and isolation controller): a021 pyro leak test failed";
CM_ SG_ 1290 HVP_a021_SquibResTestFailed "High-voltage processor (pack contactor and isolation controller): a021 squib res test failed";
CM_ SG_ 1290 HVP_a021_VstTestFailed "High-voltage processor (pack contactor and isolation controller): a021 vst test failed";
CM_ SG_ 1290 HVP_a021_SquibResistance "High-voltage processor (pack contactor and isolation controller): a021 squib resistance; raw 65535 = signal not available (SNA)";
CM_ SG_ 1290 HVP_a021_OneShotSequence "High-voltage processor (pack contactor and isolation controller): a021 one shot sequence";
CM_ SG_ 1290 HVP_a021_HighSide "High-voltage processor (pack contactor and isolation controller): a021 high side";
CM_ SG_ 1290 HVP_a021_LowSide "High-voltage processor (pack contactor and isolation controller): a021 low side";
CM_ SG_ 1290 HVP_a021_Aout "High-voltage processor (pack contactor and isolation controller): a021 aout; raw 16383 = signal not available (SNA)";
CM_ SG_ 1290 HVP_a022_pyroStatus "High-voltage processor (pack contactor and isolation controller): a022 pyro status";
CM_ SG_ 1290 HVP_a022_PyroLeakTestFailed "High-voltage processor (pack contactor and isolation controller): a022 pyro leak test failed";
CM_ SG_ 1290 HVP_a022_OneShotSequence "High-voltage processor (pack contactor and isolation controller): a022 one shot sequence";
CM_ SG_ 1290 HVP_a022_HighSide "High-voltage processor (pack contactor and isolation controller): a022 high side";
CM_ SG_ 1290 HVP_a022_LowSide "High-voltage processor (pack contactor and isolation controller): a022 low side";
CM_ SG_ 1290 HVP_a022_Aout "High-voltage processor (pack contactor and isolation controller): a022 aout; raw 16383 = signal not available (SNA)";
CM_ SG_ 1290 HVP_a022_SquibResistance "High-voltage processor (pack contactor and isolation controller): a022 squib resistance; raw 65535 = signal not available (SNA)";
CM_ SG_ 1290 HVP_a024_voltage "High-voltage processor (pack contactor and isolation controller): a024 voltage";
CM_ SG_ 1290 HVP_a025_voltage1 "High-voltage processor (pack contactor and isolation controller): a025 voltage1";
CM_ SG_ 1290 HVP_a025_voltage2 "High-voltage processor (pack contactor and isolation controller): a025 voltage2";
CM_ SG_ 1290 HVP_a025_packVoltage "High-voltage processor (pack contactor and isolation controller): a025 pack voltage";
CM_ SG_ 1290 HVP_a026_hvilStatus "High-voltage processor (pack contactor and isolation controller): a026 hvil status; raw 14 = signal not available (SNA)";
CM_ SG_ 1290 HVP_a026_inputVoltage "High-voltage processor (pack contactor and isolation controller): a026 input voltage";
CM_ SG_ 1290 HVP_a026_outputVoltage "High-voltage processor (pack contactor and isolation controller): a026 output voltage";
CM_ SG_ 1290 HVP_a026_internalVoltage "High-voltage processor (pack contactor and isolation controller): a026 internal voltage; raw 255 = signal not available (SNA)";
CM_ SG_ 1290 HVP_a026_dirVoltage "High-voltage processor (pack contactor and isolation controller): a026 dir voltage; raw 255 = signal not available (SNA)";
CM_ SG_ 1290 HVP_a026_difVoltage "High-voltage processor (pack contactor and isolation controller): a026 dif voltage; raw 255 = signal not available (SNA)";
CM_ SG_ 1290 HVP_a028_packVoltage "High-voltage processor (pack contactor and isolation controller): a028 pack voltage";
CM_ SG_ 1290 HVP_a028_sumOfBrickV "High-voltage processor (pack contactor and isolation controller): a028 sum of brick v";
CM_ SG_ 1290 HVP_a030_packPositiveLinkV "High-voltage processor (pack contactor and isolation controller): a030 pack positive link v";
CM_ SG_ 1290 HVP_a030_dcPositiveLinkV "High-voltage processor (pack contactor and isolation controller): a030 dc positive link v";
CM_ SG_ 1290 HVP_a031_packNegativeLinkV "High-voltage processor (pack contactor and isolation controller): a031 pack negative link v";
CM_ SG_ 1290 HVP_a031_dcNegativeLinkV "High-voltage processor (pack contactor and isolation controller): a031 dc negative link v";
CM_ SG_ 1290 HVP_a033_contactorPowerV "High-voltage processor (pack contactor and isolation controller): a033 contactor power v";
CM_ SG_ 1290 HVP_a033_coilCurrent "High-voltage processor (pack contactor and isolation controller): a033 coil current";
CM_ SG_ 1290 HVP_a033_pwmDutyCylePositive "High-voltage processor (pack contactor and isolation controller): a033 pwm duty cyle positive";
CM_ SG_ 1290 HVP_a033_pwmDutyCyleNegative "High-voltage processor (pack contactor and isolation controller): a033 pwm duty cyle negative";
CM_ SG_ 1290 HVP_a035_contactorPowerV "High-voltage processor (pack contactor and isolation controller): a035 contactor power v";
CM_ SG_ 1290 HVP_a035_coilCurrent "High-voltage processor (pack contactor and isolation controller): a035 coil current";
CM_ SG_ 1290 HVP_a035_pwmDutyCylePositive "High-voltage processor (pack contactor and isolation controller): a035 pwm duty cyle positive";
CM_ SG_ 1290 HVP_a035_pwmDutyCyleNegative "High-voltage processor (pack contactor and isolation controller): a035 pwm duty cyle negative";
CM_ SG_ 1290 HVP_a036_pyroFiringHandle "High-voltage processor (pack contactor and isolation controller): a036 pyro firing handle";
CM_ SG_ 1290 HVP_a036_pyroFiringTime "High-voltage processor (pack contactor and isolation controller): a036 pyro firing time";
CM_ SG_ 1290 HVP_a036_pyroFiringAttempt "High-voltage processor (pack contactor and isolation controller): a036 pyro firing attempt";
CM_ SG_ 1290 HVP_a037_pyroFiringHandle "High-voltage processor (pack contactor and isolation controller): a037 pyro firing handle";
CM_ SG_ 1290 HVP_a039_posContactorFailed "High-voltage processor (pack contactor and isolation controller): a039 pos contactor failed";
CM_ SG_ 1290 HVP_a039_negContactorFailed "High-voltage processor (pack contactor and isolation controller): a039 neg contactor failed";
CM_ SG_ 1290 HVP_a040_powerVoltage "High-voltage processor (pack contactor and isolation controller): a040 power voltage";
CM_ SG_ 1290 HVP_a040_coilCurrent "High-voltage processor (pack contactor and isolation controller): a040 coil current";
CM_ SG_ 1290 HVP_a040_posCtrVoltageDrop "High-voltage processor (pack contactor and isolation controller): a040 pos ctr voltage drop";
CM_ SG_ 1290 HVP_a040_negCtrVoltageDrop "High-voltage processor (pack contactor and isolation controller): a040 neg ctr voltage drop";
CM_ SG_ 1290 HVP_a040_posCtrAuxOpen "High-voltage processor (pack contactor and isolation controller): a040 pos ctr aux open";
CM_ SG_ 1290 HVP_a040_negCtrAuxOpen "High-voltage processor (pack contactor and isolation controller): a040 neg ctr aux open";
CM_ SG_ 1290 HVP_a041_overCurrent "High-voltage processor (pack contactor and isolation controller): a041 over current";
CM_ SG_ 1290 HVP_a041_overChargeCurrent "High-voltage processor (pack contactor and isolation controller): a041 over charge current";
CM_ SG_ 1290 HVP_a041_overDischargeCurrent "High-voltage processor (pack contactor and isolation controller): a041 over discharge current";
CM_ SG_ 1290 HVP_a041_overVoltage "High-voltage processor (pack contactor and isolation controller): a041 over voltage";
CM_ SG_ 1290 HVP_a041_overTemperature "High-voltage processor (pack contactor and isolation controller): a041 over temperature";
CM_ SG_ 1290 HVP_a041_underVoltage "High-voltage processor (pack contactor and isolation controller): a041 under voltage";
CM_ SG_ 1290 HVP_a041_crashEvent "High-voltage processor (pack contactor and isolation controller): a041 crash event";
CM_ SG_ 1290 HVP_a041_packContactorHw "High-voltage processor (pack contactor and isolation controller): a041 pack contactor hw";
CM_ SG_ 1290 HVP_a041_notAllowedtoEnergize "High-voltage processor (pack contactor and isolation controller): a041 not allowedto energize";
CM_ SG_ 1290 HVP_a041_bmbMia "High-voltage processor (pack contactor and isolation controller): a041 bmb mia";
CM_ SG_ 1290 HVP_a041_hvilFault "High-voltage processor (pack contactor and isolation controller): a041 hvil fault";
CM_ SG_ 1290 HVP_a041_contactorStateWelded "High-voltage processor (pack contactor and isolation controller): a041 contactor state welded";
CM_ SG_ 1290 HVP_a041_shuntHwMia "High-voltage processor (pack contactor and isolation controller): a041 shunt hw mia";
CM_ SG_ 1290 HVP_a041_shuntCurrentMia "High-voltage processor (pack contactor and isolation controller): a041 shunt current mia";
CM_ SG_ 1290 HVP_a041_packVoltageMismatch "High-voltage processor (pack contactor and isolation controller): a041 pack voltage mismatch";
CM_ SG_ 1290 HVP_a041_gpoRequestActive "High-voltage processor (pack contactor and isolation controller): a041 gpo request active";
CM_ SG_ 1290 HVP_a041_fcContactorClosing "High-voltage processor (pack contactor and isolation controller): a041 fc contactor closing";
CM_ SG_ 1290 HVP_a041_fcContactorOpening "High-voltage processor (pack contactor and isolation controller): a041 fc contactor opening";
CM_ SG_ 1290 HVP_a041_resetRequestRequired "High-voltage processor (pack contactor and isolation controller): a041 reset request required";
CM_ SG_ 1290 HVP_a041_pyroFault "High-voltage processor (pack contactor and isolation controller): a041 pyro fault";
CM_ SG_ 1290 HVP_a041_dcLinkOverVoltage "High-voltage processor (pack contactor and isolation controller): a041 dc link over voltage";
CM_ SG_ 1290 HVP_a042_overCurrent "High-voltage processor (pack contactor and isolation controller): a042 over current";
CM_ SG_ 1290 HVP_a042_overChargeCurrent "High-voltage processor (pack contactor and isolation controller): a042 over charge current";
CM_ SG_ 1290 HVP_a042_overDischargeCurrent "High-voltage processor (pack contactor and isolation controller): a042 over discharge current";
CM_ SG_ 1290 HVP_a042_overVoltage "High-voltage processor (pack contactor and isolation controller): a042 over voltage";
CM_ SG_ 1290 HVP_a042_overTemperature "High-voltage processor (pack contactor and isolation controller): a042 over temperature";
CM_ SG_ 1290 HVP_a042_crashEvent "High-voltage processor (pack contactor and isolation controller): a042 crash event";
CM_ SG_ 1290 HVP_a042_fcContactorHw "High-voltage processor (pack contactor and isolation controller): a042 fc contactor hw";
CM_ SG_ 1290 HVP_a042_notAllowedtoEnergize "High-voltage processor (pack contactor and isolation controller): a042 not allowedto energize";
CM_ SG_ 1290 HVP_a042_bmsHvsMia "High-voltage processor (pack contactor and isolation controller): a042 bms hvs mia";
CM_ SG_ 1290 HVP_a042_cpMia "High-voltage processor (pack contactor and isolation controller): a042 cp mia";
CM_ SG_ 1290 HVP_a042_cpFault "High-voltage processor (pack contactor and isolation controller): a042 cp fault";
CM_ SG_ 1290 HVP_a042_supply12V "High-voltage processor (pack contactor and isolation controller): a042 supply12 v";
CM_ SG_ 1290 HVP_a042_supplyVer "High-voltage processor (pack contactor and isolation controller): a042 supply ver";
CM_ SG_ 1290 HVP_a042_packVoltageMismatch "High-voltage processor (pack contactor and isolation controller): a042 pack voltage mismatch";
CM_ SG_ 1290 HVP_a042_hvilFault "High-voltage processor (pack contactor and isolation controller): a042 hvil fault";
CM_ SG_ 1290 HVP_a042_contactorStateWelded "High-voltage processor (pack contactor and isolation controller): a042 contactor state welded";
CM_ SG_ 1290 HVP_a042_shuntHwMia "High-voltage processor (pack contactor and isolation controller): a042 shunt hw mia";
CM_ SG_ 1290 HVP_a042_shuntCurrentMia "High-voltage processor (pack contactor and isolation controller): a042 shunt current mia";
CM_ SG_ 1290 HVP_a042_packContactorClosing "High-voltage processor (pack contactor and isolation controller): a042 pack contactor closing";
CM_ SG_ 1290 HVP_a042_packContactorOpening "High-voltage processor (pack contactor and isolation controller): a042 pack contactor opening";
CM_ SG_ 1290 HVP_a042_resetRequestRequired "High-voltage processor (pack contactor and isolation controller): a042 reset request required";
CM_ SG_ 1290 HVP_a042_cpVersionMismatch "High-voltage processor (pack contactor and isolation controller): a042 cp version mismatch";
CM_ SG_ 1290 HVP_a043_overCurrent "High-voltage processor (pack contactor and isolation controller): a043 over current";
CM_ SG_ 1290 HVP_a043_overChargeCurrent "High-voltage processor (pack contactor and isolation controller): a043 over charge current";
CM_ SG_ 1290 HVP_a043_overDischargeCurrent "High-voltage processor (pack contactor and isolation controller): a043 over discharge current";
CM_ SG_ 1290 HVP_a043_overVoltage "High-voltage processor (pack contactor and isolation controller): a043 over voltage";
CM_ SG_ 1290 HVP_a043_overTemperature "High-voltage processor (pack contactor and isolation controller): a043 over temperature";
CM_ SG_ 1290 HVP_a043_underVoltage "High-voltage processor (pack contactor and isolation controller): a043 under voltage";
CM_ SG_ 1290 HVP_a043_crashEvent "High-voltage processor (pack contactor and isolation controller): a043 crash event";
CM_ SG_ 1290 HVP_a043_packContactorHw "High-voltage processor (pack contactor and isolation controller): a043 pack contactor hw";
CM_ SG_ 1290 HVP_a043_notAllowedtoEnergize "High-voltage processor (pack contactor and isolation controller): a043 not allowedto energize";
CM_ SG_ 1290 HVP_a043_bmbMia "High-voltage processor (pack contactor and isolation controller): a043 bmb mia";
CM_ SG_ 1290 HVP_a043_contactorOpened "High-voltage processor (pack contactor and isolation controller): a043 contactor opened";
CM_ SG_ 1290 HVP_a044_overCurrent "High-voltage processor (pack contactor and isolation controller): a044 over current";
CM_ SG_ 1290 HVP_a044_overChargeCurrent "High-voltage processor (pack contactor and isolation controller): a044 over charge current";
CM_ SG_ 1290 HVP_a044_overDischargeCurrent "High-voltage processor (pack contactor and isolation controller): a044 over discharge current";
CM_ SG_ 1290 HVP_a044_overVoltage "High-voltage processor (pack contactor and isolation controller): a044 over voltage";
CM_ SG_ 1290 HVP_a044_overTemperature "High-voltage processor (pack contactor and isolation controller): a044 over temperature";
CM_ SG_ 1290 HVP_a044_crashEvent "High-voltage processor (pack contactor and isolation controller): a044 crash event";
CM_ SG_ 1290 HVP_a044_fcContactorHw "High-voltage processor (pack contactor and isolation controller): a044 fc contactor hw";
CM_ SG_ 1290 HVP_a044_notAllowedtoEnergize "High-voltage processor (pack contactor and isolation controller): a044 not allowedto energize";
CM_ SG_ 1290 HVP_a044_bmsHvsMia "High-voltage processor (pack contactor and isolation controller): a044 bms hvs mia";
CM_ SG_ 1290 HVP_a044_cpMia "High-voltage processor (pack contactor and isolation controller): a044 cp mia";
CM_ SG_ 1290 HVP_a044_cpFault "High-voltage processor (pack contactor and isolation controller): a044 cp fault";
CM_ SG_ 1290 HVP_a044_supply12V "High-voltage processor (pack contactor and isolation controller): a044 supply12 v";
CM_ SG_ 1290 HVP_a044_supplyVer "High-voltage processor (pack contactor and isolation controller): a044 supply ver";
CM_ SG_ 1290 HVP_a044_packVoltageMismatch "High-voltage processor (pack contactor and isolation controller): a044 pack voltage mismatch";
CM_ SG_ 1290 HVP_a044_contactorOpened "High-voltage processor (pack contactor and isolation controller): a044 contactor opened";
CM_ SG_ 1290 HVP_a044_cpVersionMismatch "High-voltage processor (pack contactor and isolation controller): a044 cp version mismatch";
CM_ SG_ 1290 HVP_a045_dcLinkVoltage "High-voltage processor (pack contactor and isolation controller): a045 dc link voltage";
CM_ SG_ 1290 HVP_a046_shuntCurrent "High-voltage processor (pack contactor and isolation controller): a046 shunt current";
CM_ SG_ 1290 HVP_a046_shuntTemperature "High-voltage processor (pack contactor and isolation controller): a046 shunt temperature";
CM_ SG_ 1290 HVP_a046_asicTemperature "High-voltage processor (pack contactor and isolation controller): a046 asic temperature";
CM_ SG_ 1290 HVP_a047_shuntCurrent "High-voltage processor (pack contactor and isolation controller): a047 shunt current";
CM_ SG_ 1290 HVP_a047_auxCurrent "High-voltage processor (pack contactor and isolation controller): a047 aux current";
CM_ SG_ 1290 HVP_a049_contactorPowerV "High-voltage processor (pack contactor and isolation controller): a049 contactor power v";
CM_ SG_ 1290 HVP_a049_coilCurrent "High-voltage processor (pack contactor and isolation controller): a049 coil current";
CM_ SG_ 1290 HVP_a049_posCtrState "High-voltage processor (pack contactor and isolation controller): a049 pos ctr state; raw 0 = signal not available (SNA)";
CM_ SG_ 1290 HVP_a049_negCtrState "High-voltage processor (pack contactor and isolation controller): a049 neg ctr state; raw 0 = signal not available (SNA)";
CM_ SG_ 1290 HVP_a050_contactorPowerV "High-voltage processor (pack contactor and isolation controller): a050 contactor power v";
CM_ SG_ 1290 HVP_a050_coilCurrent "High-voltage processor (pack contactor and isolation controller): a050 coil current";
CM_ SG_ 1290 HVP_a050_posCtrState "High-voltage processor (pack contactor and isolation controller): a050 pos ctr state; raw 0 = signal not available (SNA)";
CM_ SG_ 1290 HVP_a050_negCtrState "High-voltage processor (pack contactor and isolation controller): a050 neg ctr state; raw 0 = signal not available (SNA)";
CM_ SG_ 1290 HVP_a051_shuntTemperature "High-voltage processor (pack contactor and isolation controller): a051 shunt temperature; raw 32768 = signal not available (SNA)";
CM_ SG_ 1290 HVP_a051_shuntCurrent "High-voltage processor (pack contactor and isolation controller): a051 shunt current; raw 32768 = signal not available (SNA)";
CM_ SG_ 1290 HVP_a051_energyReserveV "High-voltage processor (pack contactor and isolation controller): a051 energy reserve v; raw 65535 = signal not available (SNA)";
CM_ SG_ 1290 HVP_a052_bmbDeviceMask "High-voltage processor (pack contactor and isolation controller): a052 bmb device mask";
CM_ SG_ 1290 HVP_a052_regErrorType "High-voltage processor (pack contactor and isolation controller): a052 reg error type";
CM_ SG_ 1290 HVP_a053_packVoltage "High-voltage processor (pack contactor and isolation controller): a053 pack voltage";
CM_ SG_ 1290 HVP_a053_dcLinkVoltage "High-voltage processor (pack contactor and isolation controller): a053 dc link voltage";
CM_ SG_ 1290 HVP_a056_diagnosis "High-voltage processor (pack contactor and isolation controller): a056 diagnosis; raw 0 = signal not available (SNA)";
CM_ SG_ 1290 HVP_a056_shuntCurrent "High-voltage processor (pack contactor and isolation controller): a056 shunt current";
CM_ SG_ 1290 HVP_a056_posPackContactorState "High-voltage processor (pack contactor and isolation controller): a056 pos pack contactor state; raw 0 = signal not available (SNA)";
CM_ SG_ 1290 HVP_a056_negPackContactorState "High-voltage processor (pack contactor and isolation controller): a056 neg pack contactor state; raw 0 = signal not available (SNA)";
CM_ SG_ 1290 HVP_a056_posFcContactorState "High-voltage processor (pack contactor and isolation controller): a056 pos fc contactor state; raw 0 = signal not available (SNA)";
CM_ SG_ 1290 HVP_a056_negFcContactorState "High-voltage processor (pack contactor and isolation controller): a056 neg fc contactor state; raw 0 = signal not available (SNA)";
CM_ SG_ 1290 HVP_a058_VrefSample "High-voltage processor (pack contactor and isolation controller): a058 vref sample";
CM_ SG_ 1290 HVP_a058_bmbDeviceId "High-voltage processor (pack contactor and isolation controller): a058 bmb device id";
CM_ SG_ 1290 HVP_a058_VrefStatus "High-voltage processor (pack contactor and isolation controller): a058 vref status";
CM_ SG_ 1290 HVP_a058_VrefType "High-voltage processor (pack contactor and isolation controller): a058 vref type";
CM_ SG_ 1290 HVP_a060_stackVoltage "High-voltage processor (pack contactor and isolation controller): a060 stack voltage";
CM_ SG_ 1290 HVP_a060_sumBrickVoltage "High-voltage processor (pack contactor and isolation controller): a060 sum brick voltage";
CM_ SG_ 1290 HVP_a060_stackId "High-voltage processor (pack contactor and isolation controller): a060 stack id";
CM_ SG_ 1290 HVP_a062_bmbDeviceMask "High-voltage processor (pack contactor and isolation controller): a062 bmb device mask";
CM_ SG_ 1290 HVP_a067_hvilTypeFromHvp "High-voltage processor (pack contactor and isolation controller): a067 hvil type from hvp";
CM_ SG_ 1290 HVP_a067_hvilTypeFromGateway "High-voltage processor (pack contactor and isolation controller): a067 hvil type from gateway";
CM_ SG_ 1290 HVP_a067_hvilTypeIsFromCal "High-voltage processor (pack contactor and isolation controller): a067 hvil type is from cal";
CM_ SG_ 1290 HVP_a068_shuntTemperature "High-voltage processor (pack contactor and isolation controller): a068 shunt temperature; raw 32768 = signal not available (SNA)";
CM_ SG_ 1290 HVP_a068_shuntCurrent "High-voltage processor (pack contactor and isolation controller): a068 shunt current; raw 32768 = signal not available (SNA)";
CM_ SG_ 1290 HVP_a068_energyReserveV "High-voltage processor (pack contactor and isolation controller): a068 energy reserve v; raw 65535 = signal not available (SNA)";
BA_DEF_ BO_ "GenMsgCycleTime" INT 0 3600000;
BA_DEF_ BO_ "GenMsgSendType" ENUM "Cyclic","NotUsed","NotUsed","NotUsed","NotUsed","NotUsed","NotUsed","IfActive","NoMsgSendType","NotUsed";
BA_DEF_ BO_ "VFrameFormat" ENUM "StandardCAN","ExtendedCAN","reserved","J1939PG","reserved","reserved","reserved","reserved","reserved","reserved","reserved","reserved","reserved","reserved","StandardCAN_FD","ExtendedCAN_FD";
BA_DEF_ BO_ "CANFD_BRS" ENUM "0","1";
BA_DEF_ SG_ "GenSigSNA" STRING;
BA_DEF_ SG_ "SystemSignalLongSymbol" STRING;
BA_DEF_ SG_ "Confidence" ENUM "validated","plausible","layout-only","contradicted";
BA_DEF_DEF_ "GenMsgCycleTime" 0;
BA_DEF_DEF_ "GenMsgSendType" "NoMsgSendType";
BA_DEF_DEF_ "VFrameFormat" "StandardCAN";
BA_DEF_DEF_ "CANFD_BRS" "1";
BA_DEF_DEF_ "GenSigSNA" "";
BA_DEF_DEF_ "SystemSignalLongSymbol" "";
BA_DEF_DEF_ "Confidence" "layout-only";
BA_ "GenMsgCycleTime" BO_ 62 100;
BA_ "GenMsgSendType" BO_ 62 0;
BA_ "GenMsgCycleTime" BO_ 838 1000;
BA_ "GenMsgSendType" BO_ 838 0;
BA_ "GenMsgCycleTime" BO_ 904 1000;
BA_ "GenMsgSendType" BO_ 904 0;
BA_ "GenMsgCycleTime" BO_ 2047 100;
BA_ "GenMsgSendType" BO_ 2047 0;
BA_ "GenMsgCycleTime" BO_ 792 100;
BA_ "GenMsgSendType" BO_ 792 0;
BA_ "GenMsgCycleTime" BO_ 1638 250;
BA_ "GenMsgSendType" BO_ 1638 0;
BA_ "GenMsgCycleTime" BO_ 1080 100;
BA_ "GenMsgSendType" BO_ 1080 0;
BA_ "GenMsgCycleTime" BO_ 1376 1000;
BA_ "GenMsgSendType" BO_ 1376 0;
BA_ "GenMsgCycleTime" BO_ 1656 100;
BA_ "GenMsgSendType" BO_ 1656 0;
BA_ "GenMsgCycleTime" BO_ 2033 2000;
BA_ "GenMsgSendType" BO_ 2033 0;
BA_ "GenMsgCycleTime" BO_ 60 2000;
BA_ "GenMsgSendType" BO_ 60 0;
BA_ "GenMsgCycleTime" BO_ 1370 250;
BA_ "GenMsgSendType" BO_ 1370 0;
BA_ "GenMsgCycleTime" BO_ 840 1000;
BA_ "GenMsgSendType" BO_ 840 0;
BA_ "GenMsgCycleTime" BO_ 1005 1000;
BA_ "GenMsgSendType" BO_ 1005 0;
BA_ "GenMsgCycleTime" BO_ 1112 100;
BA_ "GenMsgSendType" BO_ 1112 0;
BA_ "Confidence" SG_ 62 GTW_matrixIndex 1;
BA_ "SystemSignalLongSymbol" SG_ 62 GTW_w016_BLEEPCENTERversionMisma "GTW_w016_BLEEPCENTERversionMismatch";
BA_ "SystemSignalLongSymbol" SG_ 62 GTW_w093_sdCardInvReqOverflowBas "GTW_w093_sdCardInvReqOverflowBase";
BA_ "SystemSignalLongSymbol" SG_ 62 GTW_w094_sdCardInvReqOverflowCou "GTW_w094_sdCardInvReqOverflowCount";
BA_ "SystemSignalLongSymbol" SG_ 62 GTW_w104_sdCardDriverArgCorrupte "GTW_w104_sdCardDriverArgCorrupted";
BA_ "SystemSignalLongSymbol" SG_ 62 GTW_w106_BLEEPLEFTversionMismatc "GTW_w106_BLEEPLEFTversionMismatch";
BA_ "SystemSignalLongSymbol" SG_ 62 GTW_w107_BLEEPRIGHTversionMismat "GTW_w107_BLEEPRIGHTversionMismatch";
BA_ "SystemSignalLongSymbol" SG_ 62 GTW_w108_BLEEPREARversionMismatc "GTW_w108_BLEEPREARversionMismatch";
BA_ "SystemSignalLongSymbol" SG_ 62 GTW_w117_unexpectedDestructiveRe "GTW_w117_unexpectedDestructiveResetStatus";
BA_ "SystemSignalLongSymbol" SG_ 62 GTW_w118_unexpectedFunctionalRes "GTW_w118_unexpectedFunctionalResetStatus";
BA_ "SystemSignalLongSymbol" SG_ 62 GTW_w146_performancePackageMisma "GTW_w146_performancePackageMismatch";
BA_ "SystemSignalLongSymbol" SG_ 62 GTW_w227_DISPTOUCHversionMismatc "GTW_w227_DISPTOUCHversionMismatch";
BA_ "SystemSignalLongSymbol" SG_ 62 GTW_w229_displaySoftsetConnectio "GTW_w229_displaySoftsetConnection";
BA_ "SystemSignalLongSymbol" SG_ 62 GTW_w273_BLEEPREARLEFTversionMis "GTW_w273_BLEEPREARLEFTversionMismatch";
BA_ "SystemSignalLongSymbol" SG_ 62 GTW_w274_BLEEPREARRIGHTversionMi "GTW_w274_BLEEPREARRIGHTversionMismatch";
BA_ "SystemSignalLongSymbol" SG_ 62 GTW_w277_NonRevCDrMOSMitigationF "GTW_w277_NonRevCDrMOSMitigationFailed";
BA_ "SystemSignalLongSymbol" SG_ 62 GTW_w282_tcuPhyConfigurationFail "GTW_w282_tcuPhyConfigurationFailed";
BA_ "SystemSignalLongSymbol" SG_ 62 GTW_w311_canLogQueueFullBeforeFs "GTW_w311_canLogQueueFullBeforeFsInit";
BA_ "SystemSignalLongSymbol" SG_ 62 GTW_w317_sdCardChkdskRepairFaile "GTW_w317_sdCardChkdskRepairFailed";
BA_ "SystemSignalLongSymbol" SG_ 62 GTW_w322_gestureUnrecognizedFrom "GTW_w322_gestureUnrecognizedFromMoving";
BA_ "SystemSignalLongSymbol" SG_ 62 GTW_w360_RGBDOORFLversionMismatc "GTW_w360_RGBDOORFLversionMismatch";
BA_ "SystemSignalLongSymbol" SG_ 62 GTW_w361_RGBDOORRLversionMismatc "GTW_w361_RGBDOORRLversionMismatch";
BA_ "SystemSignalLongSymbol" SG_ 62 GTW_w362_RGBDOORFRversionMismatc "GTW_w362_RGBDOORFRversionMismatch";
BA_ "SystemSignalLongSymbol" SG_ 62 GTW_w363_RGBDOORRRversionMismatc "GTW_w363_RGBDOORRRversionMismatch";
BA_ "SystemSignalLongSymbol" SG_ 62 GTW_w364_BLEEPCRADLEversionMisma "GTW_w364_BLEEPCRADLEversionMismatch";
BA_ "Confidence" SG_ 838 GTW_autopilotOverrideState 1;
BA_ "Confidence" SG_ 838 GTW_autopilotConfig 1;
BA_ "Confidence" SG_ 838 GTW_autopilotOverrideConfig 1;
BA_ "Confidence" SG_ 838 GTW_autopilotOverrideExpireTime 0;
BA_ "Confidence" SG_ 904 GTW_VEH_canBusActivity 0;
BA_ "Confidence" SG_ 904 GTW_PARTY_canBusActivity 0;
BA_ "Confidence" SG_ 904 GTW_CH_canBusActivity 0;
BA_ "Confidence" SG_ 904 GTW_VEH_txWarning 0;
BA_ "Confidence" SG_ 904 GTW_PARTY_txWarning 0;
BA_ "Confidence" SG_ 904 GTW_CH_txWarning 0;
BA_ "Confidence" SG_ 904 GTW_VEH_rxWarning 0;
BA_ "Confidence" SG_ 904 GTW_PARTY_rxWarning 0;
BA_ "Confidence" SG_ 904 GTW_CH_rxWarning 0;
BA_ "Confidence" SG_ 904 GTW_VEH_faultConfinement 0;
BA_ "Confidence" SG_ 904 GTW_PARTY_faultConfinement 0;
BA_ "Confidence" SG_ 904 GTW_CH_faultConfinement 0;
BA_ "Confidence" SG_ 904 GTW_BDY_canBusActivity 0;
BA_ "Confidence" SG_ 904 GTW_BDY_txWarning 0;
BA_ "Confidence" SG_ 904 GTW_BDY_rxWarning 0;
BA_ "Confidence" SG_ 904 GTW_BDY_faultConfinement 0;
BA_ "Confidence" SG_ 2047 GTW_carConfigMultiplexer 1;
BA_ "Confidence" SG_ 2047 GTW_deliveryStatus 0;
BA_ "Confidence" SG_ 2047 GTW_cabinPTCHeaterType 0;
BA_ "Confidence" SG_ 2047 GTW_rightHandDrive 0;
BA_ "Confidence" SG_ 2047 GTW_rearLightType 0;
BA_ "Confidence" SG_ 2047 GTW_headlamps 0;
BA_ "Confidence" SG_ 2047 GTW_country 0;
BA_ "Confidence" SG_ 2047 GTW_tireType 0;
BA_ "Confidence" SG_ 2047 GTW_roofGlassType 1;
BA_ "Confidence" SG_ 2047 GTW_dasHw 0;
BA_ "Confidence" SG_ 2047 GTW_brakeHWType 0;
BA_ "Confidence" SG_ 2047 GTW_restraintsHardwareType 0;
BA_ "Confidence" SG_ 2047 GTW_drivetrainType 0;
BA_ "Confidence" SG_ 2047 GTW_radarHeaterType 0;
BA_ "Confidence" SG_ 2047 GTW_exteriorTrimType 0;
BA_ "Confidence" SG_ 2047 GTW_frontSeatHeaters 0;
BA_ "Confidence" SG_ 2047 GTW_rearSeatHeaters 0;
BA_ "Confidence" SG_ 2047 GTW_eCallAntennaHW 0;
BA_ "Confidence" SG_ 2047 GTW_homelinkType 0;
BA_ "Confidence" SG_ 2047 GTW_vdcType 0;
BA_ "Confidence" SG_ 2047 GTW_memoryMirrors 0;
BA_ "Confidence" SG_ 2047 GTW_powerLiftgateType 0;
BA_ "Confidence" SG_ 2047 GTW_lumbarECUType 0;
BA_ "Confidence" SG_ 2047 GTW_rearSeatHeaterType 0;
BA_ "Confidence" SG_ 2047 GTW_auxParkLamps 0;
BA_ "Confidence" SG_ 2047 GTW_interiorCabinRadarType 0;
BA_ "Confidence" SG_ 2047 GTW_hvacPanelVaneType 0;
BA_ "Confidence" SG_ 2047 GTW_intakeAirFilterType 0;
BA_ "Confidence" SG_ 2047 GTW_eBuckConfig 0;
BA_ "Confidence" SG_ 2047 GTW_steeringHeaterEnabled 0;
BA_ "Confidence" SG_ 2047 GTW_activeHighBeam 0;
BA_ "Confidence" SG_ 2047 GTW_airbagCutoffSwitch 0;
BA_ "Confidence" SG_ 2047 GTW_intrusionSensorType 0;
BA_ "Confidence" SG_ 2047 GTW_spoilerType 0;
BA_ "Confidence" SG_ 2047 GTW_rearFogLamps 0;
BA_ "Confidence" SG_ 2047 GTW_roofType 0;
BA_ "Confidence" SG_ 2047 GTW_thirdRowSeatType 0;
BA_ "Confidence" SG_ 2047 GTW_autopilot 0;
BA_ "Confidence" SG_ 2047 GTW_superchargingAccess 0;
BA_ "Confidence" SG_ 2047 GTW_exteriorColor 0;
BA_ "Confidence" SG_ 2047 GTW_pedestrianWarningSound 0;
BA_ "Confidence" SG_ 2047 GTW_steeringColumnUJointType 0;
BA_ "Confidence" SG_ 2047 GTW_bPillarNFCParam 0;
BA_ "Confidence" SG_ 2047 GTW_interiorLighting 0;
BA_ "Confidence" SG_ 2047 GTW_headlightLevelerType 0;
BA_ "Confidence" SG_ 2047 GTW_numberHVILNodes 0;
BA_ "Confidence" SG_ 2047 GTW_mapRegion 0;
BA_ "Confidence" SG_ 2047 GTW_performancePackage 0;
BA_ "Confidence" SG_ 2047 GTW_chassisType 0;
BA_ "Confidence" SG_ 2047 GTW_airSuspension 0;
BA_ "Confidence" SG_ 2047 GTW_centerConsoleControllerType 0;
BA_ "Confidence" SG_ 2047 GTW_autopilotCameraType 0;
BA_ "Confidence" SG_ 2047 GTW_connectivityPackage 0;
BA_ "Confidence" SG_ 2047 GTW_plcSupportType 0;
BA_ "Confidence" SG_ 2047 GTW_packEnergy 0;
BA_ "Confidence" SG_ 2047 GTW_frontSeatReclinerHardware 0;
BA_ "Confidence" SG_ 2047 GTW_brakeLineSwitchType 0;
BA_ "Confidence" SG_ 2047 GTW_espValveType 0;
BA_ "Confidence" SG_ 2047 GTW_softRange 0;
BA_ "Confidence" SG_ 2047 GTW_refrigerantType 0;
BA_ "Confidence" SG_ 2047 GTW_wheelType 0;
BA_ "Confidence" SG_ 2047 GTW_ptcControlMode 0;
BA_ "Confidence" SG_ 2047 GTW_brakeActuationType 0;
BA_ "Confidence" SG_ 2047 GTW_secondRowSeatType 0;
BA_ "Confidence" SG_ 2047 GTW_secondRowSeatMotorType 0;
BA_ "Confidence" SG_ 2047 GTW_birthday 0;
BA_ "Confidence" SG_ 2047 GTW_eCallEnabled 0;
BA_ "Confidence" SG_ 2047 GTW_parkAssistECUType 0;
BA_ "Confidence" SG_ 2047 GTW_passengerAirbagType 0;
BA_ "Confidence" SG_ 2047 GTW_forwardRadarHw 0;
BA_ "Confidence" SG_ 2047 GTW_frontSeatType 0;
BA_ "Confidence" SG_ 2047 GTW_secondRowDisplayType 0;
BA_ "Confidence" SG_ 2047 GTW_wirelessPhoneChargerType 0;
BA_ "Confidence" SG_ 2047 GTW_ethernetTunerType 0;
BA_ "Confidence" SG_ 2047 GTW_interiorTrimType 0;
BA_ "Confidence" SG_ 2047 GTW_gloveboxUSBType 0;
BA_ "Confidence" SG_ 2047 GTW_coolantPumpType 0;
BA_ "Confidence" SG_ 2047 GTW_epblHwType 0;
BA_ "Confidence" SG_ 2047 GTW_epbrHwType 0;
BA_ "Confidence" SG_ 2047 GTW_blowerMotorType 0;
BA_ "Confidence" SG_ 2047 GTW_rearLeftBLEEndpointParameter 0;
BA_ "SystemSignalLongSymbol" SG_ 2047 GTW_rearLeftBLEEndpointParameter "GTW_rearLeftBLEEndpointParameterType";
BA_ "Confidence" SG_ 2047 GTW_frontUsbHubType 0;
BA_ "Confidence" SG_ 2047 GTW_superManifoldType 0;
BA_ "Confidence" SG_ 2047 GTW_rcmLocation 0;
BA_ "Confidence" SG_ 2047 GTW_interiorCamFanType 1;
BA_ "Confidence" SG_ 2047 GTW_interiorCamBeautyCoverType 0;
BA_ "Confidence" SG_ 2047 GTW_sirenType 0;
BA_ "Confidence" SG_ 2047 GTW_hornType 0;
BA_ "Confidence" SG_ 2047 GTW_badgingVersion 1;
BA_ "Confidence" SG_ 2047 GTW_steeringColumnMotorType 0;
BA_ "Confidence" SG_ 2047 GTW_refrigACLineType 0;
BA_ "Confidence" SG_ 2047 GTW_refrigFilterType 0;
BA_ "Confidence" SG_ 2047 GTW_diBurnInType 0;
BA_ "Confidence" SG_ 2047 GTW_specialBadgingType 0;
BA_ "Confidence" SG_ 2047 GTW_chassisSubType 1;
BA_ "Confidence" SG_ 2047 GTW_frontSeatVentilationType 1;
BA_ "Confidence" SG_ 2047 GTW_towPackage 0;
BA_ "Confidence" SG_ 2047 GTW_refrigLccType 0;
BA_ "Confidence" SG_ 2047 GTW_caliperColorType 0;
BA_ "Confidence" SG_ 2047 GTW_wiperMotorType 0;
BA_ "Confidence" SG_ 2047 GTW_frontOverheadConsoleType 0;
BA_ "Confidence" SG_ 2047 GTW_shifterType 0;
BA_ "Confidence" SG_ 2047 GTW_compressorType 0;
BA_ "Confidence" SG_ 2047 GTW_twelveVBatteryType 0;
BA_ "Confidence" SG_ 2047 GTW_efuseSWConfig 0;
BA_ "Confidence" SG_ 2047 GTW_tollCollectionModuleType 0;
BA_ "Confidence" SG_ 2047 GTW_bleEndpointUpdateMethod 0;
BA_ "Confidence" SG_ 2047 GTW_steeringWheelControllerType 0;
BA_ "Confidence" SG_ 2047 GTW_frontSeatVentilationEnabled 0;
BA_ "Confidence" SG_ 2047 GTW_gloveboxActuatorType 0;
BA_ "Confidence" SG_ 2047 GTW_epasType 0;
BA_ "Confidence" SG_ 2047 GTW_homologationRegionOverride 0;
BA_ "Confidence" SG_ 2047 GTW_windowCommandsPermissionType 0;
BA_ "Confidence" SG_ 2047 GTW_headlightStepperStallDetectM 0;
BA_ "SystemSignalLongSymbol" SG_ 2047 GTW_headlightStepperStallDetectM "GTW_headlightStepperStallDetectMode";
BA_ "Confidence" SG_ 2047 GTW_rgbInteriorLightingEnabled 0;
BA_ "Confidence" SG_ 2047 GTW_windshieldWiperHeaterType 0;
BA_ "Confidence" SG_ 2047 GTW_driveInterfaceType 0;
BA_ "Confidence" SG_ 2047 GTW_efficiencyPackage 0;
BA_ "Confidence" SG_ 2047 GTW_visorLightType 0;
BA_ "Confidence" SG_ 2047 GTW_gnssAntennaType 0;
BA_ "Confidence" SG_ 2047 GTW_frontSeatHeatersEnabled 0;
BA_ "Confidence" SG_ 2047 GTW_windshieldWiperHeaterEnabled 0;
BA_ "Confidence" SG_ 2047 GTW_tcuType 1;
BA_ "Confidence" SG_ 2047 GTW_fasciaType 0;
BA_ "Confidence" SG_ 2047 GTW_powerSteeringColumn 0;
BA_ "Confidence" SG_ 2047 GTW_frontSeatHeaterType 0;
BA_ "Confidence" SG_ 2047 GTW_softPerformanceLimit 0;
BA_ "Confidence" SG_ 2047 GTW_alcoholInterlockType 1;
BA_ "Confidence" SG_ 2047 GTW_immersiveAudio 0;
BA_ "Confidence" SG_ 2047 GTW_passengerOccupancySensorType 0;
BA_ "Confidence" SG_ 2047 GTW_packPerformanceDeviation 0;
BA_ "Confidence" SG_ 2047 GTW_frontFogLamps 0;
BA_ "Confidence" SG_ 2047 GTW_driverOccupancySensorType 0;
BA_ "Confidence" SG_ 2047 GTW_audioType 0;
BA_ "Confidence" SG_ 2047 GTW_occupancyClassificationFeatu 0;
BA_ "SystemSignalLongSymbol" SG_ 2047 GTW_occupancyClassificationFeatu "GTW_occupancyClassificationFeatureType";
BA_ "Confidence" SG_ 2047 GTW_domeLightType 0;
BA_ "Confidence" SG_ 2047 GTW_tpmsType 0;
BA_ "Confidence" SG_ 2047 GTW_authenticationEndpointLayout 0;
BA_ "Confidence" SG_ 2047 GTW_socSleepOverride 0;
BA_ "Confidence" SG_ 2047 GTW_r79BehaviorOverride 0;
BA_ "Confidence" SG_ 2047 GTW_steeringHeaterType 0;
BA_ "Confidence" SG_ 2047 GTW_sohRegulatoryStatus 0;
BA_ "Confidence" SG_ 2047 GTW_m3yBusArchitecture 0;
BA_ "Confidence" SG_ 2047 GTW_blindSpotIndicatorLightType 1;
BA_ "Confidence" SG_ 2047 GTW_hvacCaseDoorType 0;
BA_ "Confidence" SG_ 2047 GTW_occupancyDetectionSourceRequ 0;
BA_ "SystemSignalLongSymbol" SG_ 2047 GTW_occupancyDetectionSourceRequ "GTW_occupancyDetectionSourceRequest";
BA_ "Confidence" SG_ 2047 GTW_rduCableType 0;
BA_ "Confidence" SG_ 2047 GTW_interiorCameraType 0;
BA_ "Confidence" SG_ 2047 GTW_frontFasciaCameraType 0;
BA_ "Confidence" SG_ 792 GTW_factoryGated 1;
BA_ "Confidence" SG_ 1638 GTW_diagRemainingSeconds 0;
BA_ "Confidence" SG_ 1638 GTW_diagSessionActive 0;
BA_ "Confidence" SG_ 1638 GTW_diagLevel 0;
BA_ "Confidence" SG_ 1638 GTW_diagUnlockProcedureActive 0;
BA_ "Confidence" SG_ 1638 GTW_diagOverrideActive 0;
BA_ "Confidence" SG_ 1638 GTW_diagPhysicalLinkEstablished 0;
BA_ "Confidence" SG_ 1080 GTW_ethGotoSleep 0;
BA_ "Confidence" SG_ 1080 GTW_ethWakeUpBus 0;
BA_ "Confidence" SG_ 1080 GTW_vehBusAsleep 0;
BA_ "Confidence" SG_ 1080 GTW_ethHeartBeatCounter 0;
BA_ "Confidence" SG_ 1080 GTW_ethWakeUpReason 1;
BA_ "Confidence" SG_ 1376 GTW_OCS1Ppresent 1;
BA_ "Confidence" SG_ 1376 GTW_PCSpresent 1;
BA_ "Confidence" SG_ 1376 GTW_HVPpresent 1;
BA_ "Confidence" SG_ 1376 GTW_BMSpresent 1;
BA_ "Confidence" SG_ 1376 GTW_CPpresent 1;
BA_ "Confidence" SG_ 1376 GTW_RCMpresent 1;
BA_ "Confidence" SG_ 1376 GTW_SCCMpresent 1;
BA_ "Confidence" SG_ 1376 GTW_VCSECpresent 1;
BA_ "Confidence" SG_ 1376 GTW_EPAS3Ppresent 1;
BA_ "Confidence" SG_ 1376 GTW_EPBLpresent 1;
BA_ "Confidence" SG_ 1376 GTW_EPBRpresent 1;
BA_ "Confidence" SG_ 1376 GTW_ESPpresent 1;
BA_ "Confidence" SG_ 1376 GTW_IBSTpresent 1;
BA_ "Confidence" SG_ 1376 GTW_PARKpresent 1;
BA_ "Confidence" SG_ 1376 GTW_RADCpresent 1;
BA_ "Confidence" SG_ 1376 GTW_TPMSpresent 1;
BA_ "Confidence" SG_ 1376 GTW_VCFRONTpresent 1;
BA_ "Confidence" SG_ 1376 GTW_VCLEFTpresent 1;
BA_ "Confidence" SG_ 1376 GTW_VCRIGHTpresent 1;
BA_ "Confidence" SG_ 1376 GTW_EPAS3Spresent 1;
BA_ "Confidence" SG_ 1376 GTW_CMPpresent 1;
BA_ "Confidence" SG_ 1376 GTW_DASpresent 1;
BA_ "Confidence" SG_ 1376 GTW_PTCpresent 1;
BA_ "Confidence" SG_ 1376 GTW_SWCpresent 1;
BA_ "Confidence" SG_ 1376 GTW_PMRpresent 1;
BA_ "Confidence" SG_ 1376 GTW_PMFpresent 1;
BA_ "Confidence" SG_ 1376 GTW_DIRpresent 1;
BA_ "Confidence" SG_ 1376 GTW_DIFpresent 1;
BA_ "Confidence" SG_ 1656 GTW_gearControlChecksum 0;
BA_ "Confidence" SG_ 1656 GTW_gearControlCounter 0;
BA_ "Confidence" SG_ 1656 GTW_gearShiftRequest 0;
BA_ "GenSigSNA" SG_ 1656 GTW_gearShiftRequest "0";
BA_ "Confidence" SG_ 1656 GTW_osdActive 0;
BA_ "Confidence" SG_ 1656 GTW_primaryGearControlStatus 0;
BA_ "Confidence" SG_ 1656 GTW_gearStripEnable 0;
BA_ "Confidence" SG_ 1656 GTW_showNeutralButton 0;
BA_ "Confidence" SG_ 1656 GTW_showAutoParkButton 0;
BA_ "Confidence" SG_ 1656 GTW_autoParkRequest 0;
BA_ "Confidence" SG_ 1656 GTW_smartShiftStatus 0;
BA_ "GenSigSNA" SG_ 1656 GTW_smartShiftStatus "0";
BA_ "Confidence" SG_ 1656 GTW_processingRDgestures 0;
BA_ "Confidence" SG_ 1656 GTW_processingTapPgestures 0;
BA_ "Confidence" SG_ 1656 GTW_gearStripChangeReason 0;
BA_ "GenSigSNA" SG_ 1656 GTW_gearStripChangeReason "0";
BA_ "Confidence" SG_ 1656 GTW_touchActive 0;
BA_ "Confidence" SG_ 1656 GTW_steamOff 0;
BA_ "Confidence" SG_ 1656 GTW_screenPCBTemperature 1;
BA_ "GenSigSNA" SG_ 1656 GTW_screenPCBTemperature "2047";
BA_ "Confidence" SG_ 2033 GTW_hrlIndex 1;
BA_ "Confidence" SG_ 2033 GTW_hrlState 0;
BA_ "Confidence" SG_ 2033 GTW_hrlTriggerDuration 1;
BA_ "Confidence" SG_ 2033 GTW_hrlTriggerType 0;
BA_ "Confidence" SG_ 2033 GTW_hrlTriggerId 1;
BA_ "Confidence" SG_ 60 GTW_infoIndex 1;
BA_ "Confidence" SG_ 60 GTW_buildType 0;
BA_ "Confidence" SG_ 60 GTW_hardwareId 0;
BA_ "Confidence" SG_ 60 GTW_platformType 0;
BA_ "Confidence" SG_ 60 GTW_appCrc 0;
BA_ "Confidence" SG_ 60 GTW_applicationGitHash 0;
BA_ "Confidence" SG_ 60 GTW_bootGitHash 0;
BA_ "Confidence" SG_ 1370 GTW_mismatchFaultIndex 1;
BA_ "Confidence" SG_ 1370 GTW_mismatchFaultChecksum 0;
BA_ "Confidence" SG_ 1370 GTW_mismatchFaultCounter 0;
BA_ "Confidence" SG_ 1370 GTW_GTWmismatchFault 0;
BA_ "Confidence" SG_ 1370 GTW_BMSmismatchFault 0;
BA_ "Confidence" SG_ 1370 GTW_APSmismatchFault 0;
BA_ "Confidence" SG_ 1370 GTW_BLEEPCENTERmismatchFault 0;
BA_ "Confidence" SG_ 1370 GTW_BLEEPLEFTmismatchFault 0;
BA_ "Confidence" SG_ 1370 GTW_BLEEPREARmismatchFault 0;
BA_ "Confidence" SG_ 1370 GTW_BLEEPRIGHTmismatchFault 0;
BA_ "Confidence" SG_ 1370 GTW_CBCmismatchFault 0;
BA_ "Confidence" SG_ 1370 GTW_CMPmismatchFault 0;
BA_ "Confidence" SG_ 1370 GTW_CPmismatchFault 0;
BA_ "Confidence" SG_ 1370 GTW_DIFmismatchFault 0;
BA_ "Confidence" SG_ 1370 GTW_DIRmismatchFault 0;
BA_ "Confidence" SG_ 1370 GTW_EPAS3PmismatchFault 0;
BA_ "Confidence" SG_ 1370 GTW_EPAS3SmismatchFault 0;
BA_ "Confidence" SG_ 1370 GTW_EPBLmismatchFault 0;
BA_ "Confidence" SG_ 1370 GTW_EPBRmismatchFault 0;
BA_ "Confidence" SG_ 1370 GTW_ESPCALmismatchFault 0;
BA_ "Confidence" SG_ 1370 GTW_ESPmismatchFault 0;
BA_ "Confidence" SG_ 1370 GTW_HCM3LmismatchFault 0;
BA_ "Confidence" SG_ 1370 GTW_HCM3RmismatchFault 0;
BA_ "Confidence" SG_ 1370 GTW_HCMLmismatchFault 0;
BA_ "Confidence" SG_ 1370 GTW_HCMRmismatchFault 0;
BA_ "Confidence" SG_ 1370 GTW_HVPmismatchFault 0;
BA_ "Confidence" SG_ 1370 GTW_IBSTCALmismatchFault 0;
BA_ "Confidence" SG_ 1370 GTW_IBSTmismatchFault 0;
BA_ "Confidence" SG_ 1370 GTW_LVBMSmismatchFault 0;
BA_ "Confidence" SG_ 1370 GTW_OCS1PmismatchFault 0;
BA_ "Confidence" SG_ 1370 GTW_OPCFmismatchFault 0;
BA_ "Confidence" SG_ 1370 GTW_OPCRmismatchFault 0;
BA_ "Confidence" SG_ 1370 GTW_PARKmismatchFault 0;
BA_ "Confidence" SG_ 1370 GTW_PCSCPU2mismatchFault 0;
BA_ "Confidence" SG_ 1370 GTW_PCSmismatchFault 0;
BA_ "Confidence" SG_ 1370 GTW_PMFmismatchFault 0;
BA_ "Confidence" SG_ 1370 GTW_PMRmismatchFault 0;
BA_ "Confidence" SG_ 1370 GTW_PTCmismatchFault 0;
BA_ "Confidence" SG_ 1370 GTW_RCMCALmismatchFault 0;
BA_ "Confidence" SG_ 1370 GTW_RCMmismatchFault 0;
BA_ "Confidence" SG_ 1370 GTW_SCCMmismatchFault 0;
BA_ "Confidence" SG_ 1370 GTW_SDCRmismatchFault 0;
BA_ "Confidence" SG_ 1370 GTW_SWCmismatchFault 0;
BA_ "Confidence" SG_ 1370 GTW_THSmismatchFault 0;
BA_ "Confidence" SG_ 1370 GTW_VCFRONTmismatchFault 0;
BA_ "Confidence" SG_ 1370 GTW_VCLEFTmismatchFault 0;
BA_ "Confidence" SG_ 1370 GTW_VCRIGHTmismatchFault 0;
BA_ "Confidence" SG_ 1370 GTW_VCSECmismatchFault 0;
BA_ "Confidence" SG_ 1370 GTW_PMmismatchFault 0;
BA_ "Confidence" SG_ 840 GTW_vehicleVersionMatchStatus 0;
BA_ "Confidence" SG_ 840 GTW_hwtype 0;
BA_ "GenSigSNA" SG_ 840 GTW_hwtype "0";
BA_ "Confidence" SG_ 840 GTW_jcanProductName 0;
BA_ "GenSigSNA" SG_ 840 GTW_jcanProductName "0";
BA_ "Confidence" SG_ 840 GTW_uptimeSeconds 1;
BA_ "Confidence" SG_ 840 GTW_boardRevision 0;
BA_ "Confidence" SG_ 840 GTW_sentryModeState 1;
BA_ "GenSigSNA" SG_ 840 GTW_sentryModeState "6";
BA_ "Confidence" SG_ 840 GTW_socSleepType 0;
BA_ "GenSigSNA" SG_ 840 GTW_socSleepType "0";
BA_ "Confidence" SG_ 840 GTW_resetType 1;
BA_ "GenSigSNA" SG_ 840 GTW_resetType "0";
BA_ "Confidence" SG_ 1005 GTW_ecuUpdateStarted 0;
BA_ "Confidence" SG_ 1005 GTW_updateStarted 1;
BA_ "Confidence" SG_ 1112 GTW_nmGoingToSleep 0;
BA_ "Confidence" SG_ 1112 GTW_nmWakeUpBus 0;
BA_ "Confidence" SG_ 1112 GTW_chBusAsleep 0;
BA_ "Confidence" SG_ 1112 GTW_ethBusAsleep 0;
BA_ "Confidence" SG_ 1112 GTW_nmKeepAwakeReason 0;
BA_ "GenSigSNA" SG_ 1112 GTW_nmKeepAwakeReason "0";
BA_ "Confidence" SG_ 1112 GTW_nmWakeUpReason 1;
BA_ "Confidence" SG_ 1112 GTW_ethKeepAwakeReason 1;
BA_ "GenSigSNA" SG_ 1112 GTW_ethKeepAwakeReason "0";
BA_ "Confidence" SG_ 1112 GTW_nmDebugWakeUp 1;
BA_ "Confidence" SG_ 1112 GTW_OTAKeepAwake 1;
BA_ "Confidence" SG_ 1112 GTW_smsPokeReceived 1;
BA_ "Confidence" SG_ 1112 GTW_bdyBusAsleep 1;
BA_ "Confidence" SG_ 1290 HVP_alertID 1;
BA_ "Confidence" SG_ 1290 HVP_alertSet 1;
BA_ "Confidence" SG_ 1290 HVP_a005_current 1;
BA_ "Confidence" SG_ 1290 HVP_a006_current 1;
BA_ "Confidence" SG_ 1290 HVP_a007_current 1;
BA_ "Confidence" SG_ 1290 HVP_a008_temperature 1;
BA_ "Confidence" SG_ 1290 HVP_a009_brickVoltage 1;
BA_ "Confidence" SG_ 1290 HVP_a010_brickVoltage 1;
BA_ "Confidence" SG_ 1290 HVP_a012_bmbCommStatusTypeA 1;
BA_ "Confidence" SG_ 1290 HVP_a012_bmbCommStatusTypeB 1;
BA_ "Confidence" SG_ 1290 HVP_a013_bmbCommStatusTypeA 1;
BA_ "Confidence" SG_ 1290 HVP_a013_bmbCommStatusTypeB 1;
BA_ "Confidence" SG_ 1290 HVP_a013_bmbChainBreakType 1;
BA_ "Confidence" SG_ 1290 HVP_a018_dcLinkVoltage 1;
BA_ "Confidence" SG_ 1290 HVP_a018_battery12V 1;
BA_ "SystemSignalLongSymbol" SG_ 1290 HVP_a018_remainingPcsPowerCycles "HVP_a018_remainingPcsPowerCyclesAllowed";
BA_ "SystemSignalLongSymbol" SG_ 1290 HVP_a018_remainingPcsRecoveriesA "HVP_a018_remainingPcsRecoveriesAllowed";
BA_ "SystemSignalLongSymbol" SG_ 1290 HVP_a018_hvcHardwareSupportsCycl "HVP_a018_hvcHardwareSupportsCycling";
BA_ "SystemSignalLongSymbol" SG_ 1290 HVP_a018_pcsHardwareOkToBePowerC "HVP_a018_pcsHardwareOkToBePowerCycled";
BA_ "Confidence" SG_ 1290 HVP_a020_energyReserveV 1;
BA_ "GenSigSNA" SG_ 1290 HVP_a020_energyReserveV "65535";
BA_ "Confidence" SG_ 1290 HVP_a020_shuntCurrentAux 1;
BA_ "GenSigSNA" SG_ 1290 HVP_a020_shuntCurrentAux "32768";
BA_ "Confidence" SG_ 1290 HVP_a020_shuntTemperature 1;
BA_ "GenSigSNA" SG_ 1290 HVP_a020_shuntTemperature "32768";
BA_ "Confidence" SG_ 1290 HVP_a021_pyroStatus 1;
BA_ "SystemSignalLongSymbol" SG_ 1290 HVP_a021_HighSideSwitchTestFaile "HVP_a021_HighSideSwitchTestFailed";
BA_ "Confidence" SG_ 1290 HVP_a021_SquibResistance 1;
BA_ "GenSigSNA" SG_ 1290 HVP_a021_SquibResistance "65535";
BA_ "Confidence" SG_ 1290 HVP_a021_Aout 1;
BA_ "GenSigSNA" SG_ 1290 HVP_a021_Aout "16383";
BA_ "Confidence" SG_ 1290 HVP_a022_pyroStatus 1;
BA_ "Confidence" SG_ 1290 HVP_a022_Aout 1;
BA_ "GenSigSNA" SG_ 1290 HVP_a022_Aout "16383";
BA_ "Confidence" SG_ 1290 HVP_a022_SquibResistance 1;
BA_ "GenSigSNA" SG_ 1290 HVP_a022_SquibResistance "65535";
BA_ "Confidence" SG_ 1290 HVP_a024_voltage 1;
BA_ "Confidence" SG_ 1290 HVP_a025_voltage1 1;
BA_ "Confidence" SG_ 1290 HVP_a025_voltage2 1;
BA_ "Confidence" SG_ 1290 HVP_a025_packVoltage 1;
BA_ "Confidence" SG_ 1290 HVP_a026_hvilStatus 1;
BA_ "GenSigSNA" SG_ 1290 HVP_a026_hvilStatus "14";
BA_ "Confidence" SG_ 1290 HVP_a026_inputVoltage 1;
BA_ "Confidence" SG_ 1290 HVP_a026_outputVoltage 1;
BA_ "Confidence" SG_ 1290 HVP_a026_internalVoltage 1;
BA_ "GenSigSNA" SG_ 1290 HVP_a026_internalVoltage "255";
BA_ "Confidence" SG_ 1290 HVP_a026_dirVoltage 1;
BA_ "GenSigSNA" SG_ 1290 HVP_a026_dirVoltage "255";
BA_ "Confidence" SG_ 1290 HVP_a026_difVoltage 1;
BA_ "GenSigSNA" SG_ 1290 HVP_a026_difVoltage "255";
BA_ "Confidence" SG_ 1290 HVP_a028_packVoltage 1;
BA_ "Confidence" SG_ 1290 HVP_a028_sumOfBrickV 1;
BA_ "Confidence" SG_ 1290 HVP_a030_packPositiveLinkV 1;
BA_ "Confidence" SG_ 1290 HVP_a030_dcPositiveLinkV 1;
BA_ "Confidence" SG_ 1290 HVP_a031_packNegativeLinkV 1;
BA_ "Confidence" SG_ 1290 HVP_a031_dcNegativeLinkV 1;
BA_ "Confidence" SG_ 1290 HVP_a033_contactorPowerV 1;
BA_ "Confidence" SG_ 1290 HVP_a033_coilCurrent 1;
BA_ "Confidence" SG_ 1290 HVP_a033_pwmDutyCylePositive 1;
BA_ "Confidence" SG_ 1290 HVP_a033_pwmDutyCyleNegative 1;
BA_ "Confidence" SG_ 1290 HVP_a035_contactorPowerV 1;
BA_ "Confidence" SG_ 1290 HVP_a035_coilCurrent 1;
BA_ "Confidence" SG_ 1290 HVP_a035_pwmDutyCylePositive 1;
BA_ "Confidence" SG_ 1290 HVP_a035_pwmDutyCyleNegative 1;
BA_ "Confidence" SG_ 1290 HVP_a036_pyroFiringHandle 1;
BA_ "Confidence" SG_ 1290 HVP_a037_pyroFiringHandle 1;
BA_ "Confidence" SG_ 1290 HVP_a040_powerVoltage 1;
BA_ "Confidence" SG_ 1290 HVP_a040_coilCurrent 1;
BA_ "Confidence" SG_ 1290 HVP_a040_posCtrVoltageDrop 1;
BA_ "Confidence" SG_ 1290 HVP_a040_negCtrVoltageDrop 1;
BA_ "Confidence" SG_ 1290 HVP_a045_dcLinkVoltage 1;
BA_ "Confidence" SG_ 1290 HVP_a046_shuntCurrent 1;
BA_ "Confidence" SG_ 1290 HVP_a046_shuntTemperature 1;
BA_ "Confidence" SG_ 1290 HVP_a046_asicTemperature 1;
BA_ "Confidence" SG_ 1290 HVP_a047_shuntCurrent 1;
BA_ "Confidence" SG_ 1290 HVP_a047_auxCurrent 1;
BA_ "Confidence" SG_ 1290 HVP_a049_contactorPowerV 1;
BA_ "Confidence" SG_ 1290 HVP_a049_coilCurrent 1;
BA_ "Confidence" SG_ 1290 HVP_a049_posCtrState 1;
BA_ "GenSigSNA" SG_ 1290 HVP_a049_posCtrState "0";
BA_ "Confidence" SG_ 1290 HVP_a049_negCtrState 1;
BA_ "GenSigSNA" SG_ 1290 HVP_a049_negCtrState "0";
BA_ "Confidence" SG_ 1290 HVP_a050_contactorPowerV 1;
BA_ "Confidence" SG_ 1290 HVP_a050_coilCurrent 1;
BA_ "Confidence" SG_ 1290 HVP_a050_posCtrState 1;
BA_ "GenSigSNA" SG_ 1290 HVP_a050_posCtrState "0";
BA_ "Confidence" SG_ 1290 HVP_a050_negCtrState 1;
BA_ "GenSigSNA" SG_ 1290 HVP_a050_negCtrState "0";
BA_ "Confidence" SG_ 1290 HVP_a051_shuntTemperature 1;
BA_ "GenSigSNA" SG_ 1290 HVP_a051_shuntTemperature "32768";
BA_ "Confidence" SG_ 1290 HVP_a051_shuntCurrent 1;
BA_ "GenSigSNA" SG_ 1290 HVP_a051_shuntCurrent "32768";
BA_ "Confidence" SG_ 1290 HVP_a051_energyReserveV 1;
BA_ "GenSigSNA" SG_ 1290 HVP_a051_energyReserveV "65535";
BA_ "Confidence" SG_ 1290 HVP_a052_regErrorType 1;
BA_ "Confidence" SG_ 1290 HVP_a053_packVoltage 1;
BA_ "Confidence" SG_ 1290 HVP_a053_dcLinkVoltage 1;
BA_ "Confidence" SG_ 1290 HVP_a056_diagnosis 1;
BA_ "GenSigSNA" SG_ 1290 HVP_a056_diagnosis "0";
BA_ "Confidence" SG_ 1290 HVP_a056_shuntCurrent 1;
BA_ "Confidence" SG_ 1290 HVP_a056_posPackContactorState 1;
BA_ "GenSigSNA" SG_ 1290 HVP_a056_posPackContactorState "0";
BA_ "Confidence" SG_ 1290 HVP_a056_negPackContactorState 1;
BA_ "GenSigSNA" SG_ 1290 HVP_a056_negPackContactorState "0";
BA_ "Confidence" SG_ 1290 HVP_a056_posFcContactorState 1;
BA_ "GenSigSNA" SG_ 1290 HVP_a056_posFcContactorState "0";
BA_ "Confidence" SG_ 1290 HVP_a056_negFcContactorState 1;
BA_ "GenSigSNA" SG_ 1290 HVP_a056_negFcContactorState "0";
BA_ "Confidence" SG_ 1290 HVP_a058_VrefSample 1;
BA_ "Confidence" SG_ 1290 HVP_a058_VrefStatus 1;
BA_ "Confidence" SG_ 1290 HVP_a058_VrefType 1;
BA_ "Confidence" SG_ 1290 HVP_a060_stackVoltage 1;
BA_ "Confidence" SG_ 1290 HVP_a060_sumBrickVoltage 1;
BA_ "Confidence" SG_ 1290 HVP_a067_hvilTypeFromHvp 1;
BA_ "Confidence" SG_ 1290 HVP_a067_hvilTypeFromGateway 1;
BA_ "Confidence" SG_ 1290 HVP_a068_shuntTemperature 1;
BA_ "GenSigSNA" SG_ 1290 HVP_a068_shuntTemperature "32768";
BA_ "Confidence" SG_ 1290 HVP_a068_shuntCurrent 1;
BA_ "GenSigSNA" SG_ 1290 HVP_a068_shuntCurrent "32768";
BA_ "Confidence" SG_ 1290 HVP_a068_energyReserveV 1;
BA_ "GenSigSNA" SG_ 1290 HVP_a068_energyReserveV "65535";
VAL_ 62 GTW_matrixIndex 6 "AlertMatrix6" 5 "AlertMatrix5" 4 "AlertMatrix4" 3 "AlertMatrix3" 2 "AlertMatrix2" 1 "AlertMatrix1" 0 "AlertMatrix0" ;
VAL_ 838 GTW_autopilotOverrideState 3 "TIMEBOUND_SUBSCRIPTION" 2 "TRIAL" 1 "SUBSCRIPTION" 0 "BASE" ;
VAL_ 838 GTW_autopilotConfig 4 "BASIC" 3 "SELF_DRIVING" 2 "ENHANCED" 1 "HIGHWAY" 0 "NONE" ;
VAL_ 838 GTW_autopilotOverrideConfig 4 "BASIC" 3 "SELF_DRIVING" 2 "ENHANCED" 1 "HIGHWAY" 0 "NONE" ;
VAL_ 904 GTW_VEH_faultConfinement 2 "BUS_OFF" 1 "ERROR_PASSIVE" 0 "ERROR_ACTIVE" ;
VAL_ 904 GTW_PARTY_faultConfinement 2 "BUS_OFF" 1 "ERROR_PASSIVE" 0 "ERROR_ACTIVE" ;
VAL_ 904 GTW_CH_faultConfinement 2 "BUS_OFF" 1 "ERROR_PASSIVE" 0 "ERROR_ACTIVE" ;
VAL_ 904 GTW_BDY_faultConfinement 2 "BUS_OFF" 1 "ERROR_PASSIVE" 0 "ERROR_ACTIVE" ;
VAL_ 2047 GTW_deliveryStatus 1 "DELIVERED" 0 "NOT_DELIVERED" ;
VAL_ 2047 GTW_cabinPTCHeaterType 1 "NONE" 0 "BORGWARNER" ;
VAL_ 2047 GTW_rightHandDrive 1 "RIGHT" 0 "LEFT" ;
VAL_ 2047 GTW_rearLightType 2 "GLOBAL" 1 "EU_CN" 0 "NA" ;
VAL_ 2047 GTW_headlamps 2 "GLOBAL" 1 "PREMIUM" 0 "BASE" ;
VAL_ 2047 GTW_tireType 38 "HANKOOK_SUMMER_18" 37 "GITI_SUMMER_18" 36 "KUMHO_ALL_SEASON_18" 35 "GOODYEAR_ALL_SEASON_18" 34 "CONTI_SUMMER_19" 33 "BRIDGESTONE_ALL_SEASON_20" 32 "HANKOOK_ALL_SEASON_20" 31 "GOODYEAR_SUMMER_19" 30 "KUMHO_ALL_SEASON_19" 29 "HANKOOK_ALL_SEASON_21" 28 "PIRELLI_ALL_SEASON_19" 27 "GOODYEAR_ALL_SEASON_21" 26 "HANKOOK_ALL_SEASON_18" 25 "PIRELLI_ALL_SEASON_22" 24 "CONTI_SUMMER_22" 23 "CONTI_ALL_SEASON_20" 22 "MICHELIN_SUMMER_21" 21 "PIRELLI_SUMMER_20" 20 "PIRELLI_SUMMER_19" 19 "MICHELIN_ALL_SEASON_21" 18 "PIRELLI_SUMMER_21" 17 "GOODYEAR_ALL_SEASON_20" 16 "BRIDGESTONE_SUMMER_18" 7 "GOODYEAR_ALL_TERRAIN_20" 6 "PIRELLI_ALL_SEASON_20" 5 "MICHELIN_SUMMER_20" 4 "CONTI_ALL_SEASON_19" 3 "HANKOOK_SUMMER_19" 2 "MICHELIN_SUMMER_18" 1 "MICHELIN_ALL_SEASON_18" 0 "UNKNOWN" ;
VAL_ 2047 GTW_roofGlassType 3 "UNCOATED" 2 "NONE" 1 "TSA5_NOPET" 0 "TSA3_PET" ;
VAL_ 2047 GTW_dasHw 5 "TESLA_AP4" 4 "TESLA_AP3" 3 "PARKER_PASCAL_2_5" ;
VAL_ 2047 GTW_brakeHWType 21 "HITACHI_P42_V2_MANDO_43MOC_LOW_DRAG" 20 "BREMBO_LARGE_P42_V2_MANDO_43MOC_LOW_DRAG" 18 "BREMBO_LARGE_P42_V2_BREMBO_44MOC_GA" 17 "HITACHI_P42_V2_MANDO_43MOC" 16 "BREMBO_P42LD_V2_MANDO_43MOC" 15 "BREMBO_P42LD_ZF_43MOC" 13 "BREMBO_P42_ZF_43MOC" 9 "BREMBO_P42_V2_MANDO_43MOC" 8 "BREMBO_LARGE_P42_V2_MANDO_43MOC" 7 "BREMBO_LARGE_P42_V2_BREMBO_LARGE_44MOC" 6 "BREMBO_LARGE_P42_V2_BREMBO_44MOC" 3 "BREMBO_LARGE_P42_BREMBO_LARGE_44MOC" 2 "BREMBO_LARGE_P42_MANDO_43MOC" 1 "BREMBO_LARGE_P42_BREMBO_44MOC" 0 "BREMBO_P42_MANDO_43MOC" ;
VAL_ 2047 GTW_restraintsHardwareType 239 "NA_NO_KAB_MYB" 238 "ROW_ECALL_E41_MYB" 237 "EU_ECALL_E41_MYB" 236 "NA_E41_MYB" 233 "NA_MYL" 232 "ECE_ECALL_PEDPRO_MYL" 89 "ROW_ECALL_PEDPRO_MYL" 88 "ROW_PEDPRO_MYB" 87 "ROW_PERF_ECALL_PEDPRO_MYB" 86 "EU_PERF_ECALL_PEDPRO_MYB" 85 "EU_ECALL_PEDPRO_MYB" 84 "ROW_ECALL_PEDPRO_MYB" 83 "ROW_MYB" 82 "ROW_ECALL_MYB" 81 "NA_MYB" ;
VAL_ 2047 GTW_drivetrainType 1 "AWD" 0 "RWD" ;
VAL_ 2047 GTW_radarHeaterType 1 "MODELY_BACKER_THIN_3M" 0 "NONE" ;
VAL_ 2047 GTW_exteriorTrimType 1 "SATIN_BLACK" 0 "STANDARD_CHROME" ;
VAL_ 2047 GTW_frontSeatHeaters 1 "KONGSBERG_LOW_POWER" 0 "NONE" ;
VAL_ 2047 GTW_rearSeatHeaters 1 "KONGSBERG_LOW_POWER" 0 "NONE" ;
VAL_ 2047 GTW_eCallAntennaHW 1 "MAIN_ANT_ONLY" 0 "BACKUP_OR_MAIN_ANT" ;
VAL_ 2047 GTW_homelinkType 1 "HOMELINK_V_OPT_2" 0 "NONE" ;
VAL_ 2047 GTW_vdcType 1 "TESLA_VDC" 0 "BOSCH_VDC" ;
VAL_ 2047 GTW_memoryMirrors 1 "SMR" 0 "NOT_INSTALLED" ;
VAL_ 2047 GTW_powerLiftgateType 2 "HUADE_REV1" 1 "TESLA_REV1" 0 "NOT_INSTALLED" ;
VAL_ 2047 GTW_lumbarECUType 10 "AEW_SINGLE_AXIS_DRIVER_ONLY_RHD" 9 "AEW_SINGLE_AXIS_DRIVER_ONLY_LHD" 8 "ND_DRIVER_ONLY_RHD" 7 "ND_DRIVER_ONLY_LHD" 6 "AEW_DRIVER_ONLY_RHD" 5 "AEW_DRIVER_ONLY_LHD" 4 "AEW" 3 "ALFMEIER_DRIVER_ONLY_RHD" 2 "ALFMEIER_DRIVER_ONLY_LHD" 1 "ALFMEIER" 0 "NONE" ;
VAL_ 2047 GTW_rearSeatHeaterType 3 "LEFT_RIGHT_ONLY_GENTHERM" 2 "NONE" 1 "LEFT_RIGHT_ONLY_KONGSBERG" ;
VAL_ 2047 GTW_auxParkLamps 3 "NONE" 2 "EU" 1 "NA_PREMIUM" 0 "NA_BASE" ;
VAL_ 2047 GTW_interiorCabinRadarType 1 "TESLA" 0 "NONE" ;
VAL_ 2047 GTW_hvacPanelVaneType 1 "CONVERGENT_V1" 0 "PARALLEL_V1" ;
VAL_ 2047 GTW_intakeAirFilterType 1 "HEPA" 0 "STANDARD" ;
VAL_ 2047 GTW_eBuckConfig 1 "DEV_BUCK" 0 "NONE" ;
VAL_ 2047 GTW_steeringHeaterEnabled 1 "ENABLED" 0 "DISABLED" ;
VAL_ 2047 GTW_activeHighBeam 1 "ACTIVE" 0 "NOT_ACTIVE" ;
VAL_ 2047 GTW_airbagCutoffSwitch 1 "CUTOFF_SWITCH_ENABLED" 0 "CUTOFF_SWITCH_DISABLED" ;
VAL_ 2047 GTW_intrusionSensorType 1 "VODAFONE" 0 "NOT_INSTALLED" ;
VAL_ 2047 GTW_spoilerType 1 "PASSIVE" 0 "NOT_INSTALLED" ;
VAL_ 2047 GTW_rearFogLamps 1 "INSTALLED" 0 "NOT_INSTALLED" ;
VAL_ 2047 GTW_roofType 1 "FIXED_GLASS" ;
VAL_ 2047 GTW_thirdRowSeatType 1 "FLAT_FOLD" 0 "NONE" ;
VAL_ 2047 GTW_autopilot 4 "BASIC" 3 "SELF_DRIVING" 2 "ENHANCED" 1 "HIGHWAY" 0 "NONE" ;
VAL_ 2047 GTW_superchargingAccess 2 "PAY_AS_YOU_GO" 1 "ALLOWED" 0 "NOT_ALLOWED" ;
VAL_ 2047 GTW_exteriorColor 20 "COASTAL_BLUE" 17 "MARINE_BLUE" 16 "SILKROAD_SILVER" 15 "DIAMOND_BLACK" 14 "GLACIER_BLUE" 13 "FROST_BLUE" 11 "STEALTH_GREY" 10 "ULTRA_RED" 9 "QUICKSILVER" 8 "ABYSS_BLUE" 7 "MIDNIGHT_CHERRY_RED" 6 "PEARL_WHITE" 5 "DEEP_BLUE" 3 "MIDNIGHT_SILVER" 2 "SILVER_METALLIC" 1 "SOLID_BLACK" 0 "RED_MULTICOAT" ;
VAL_ 2047 GTW_pedestrianWarningSound 2 "EXT_SPEAKER_V2" 1 "SPEAKER" 0 "NONE" ;
VAL_ 2047 GTW_steeringColumnUJointType 1 "C_SAMPLE_PHASING" ;
VAL_ 2047 GTW_bPillarNFCParam 1 "MODEL_Y" 0 "MODEL_3" ;
VAL_ 2047 GTW_interiorLighting 6 "FOOTWELL" 5 "FOOTWELL_RGB_IP" 4 "PREMIUM_WITH_RGB_IP_ONLY" 3 "PREMIUM_WITH_RGB" 2 "PREMIUM_NO_POCKET_LIGHT" 1 "PREMIUM" 0 "BASE" ;
VAL_ 2047 GTW_headlightLevelerType 2 "VIRTUAL_PITCH_SENSOR" 1 "GEN1" 0 "NONE" ;
VAL_ 2047 GTW_numberHVILNodes 3 "HVIL_NODES_3" 2 "HVIL_NODES_2" 0 "HVIL_NODES_0" ;
VAL_ 2047 GTW_mapRegion 13 "LA" 12 "IN" 11 "SE" 10 "MO" 9 "HK" 8 "ME" 7 "KR" 6 "TW" 5 "JP" 4 "AU" 3 "CN" 2 "NONE" 1 "EU" 0 "US" ;
VAL_ 2047 GTW_performancePackage 4 "BASE_2022" 3 "BASE_PLUS" 2 "BASE_2024" 1 "PERFORMANCE" 0 "BASE" ;
VAL_ 2047 GTW_chassisType 7 "MODEL_Y_LONG_WHEELBASE_CHASSIS_PATRONUS" 3 "MODEL_Y_CHASSIS" 2 "MODEL_3_CHASSIS" ;
VAL_ 2047 GTW_airSuspension 3 "COIL_ADAPTIVE_DAMPING" 0 "NONE" ;
VAL_ 2047 GTW_centerConsoleControllerType 2 "INSTALLED_NO_AIRWAVE" 1 "INSTALLED_V1" 0 "NONE" ;
VAL_ 2047 GTW_autopilotCameraType 1 "RGGB_CAMERAS" 0 "RCCB_CAMERAS" ;
VAL_ 2047 GTW_connectivityPackage 1 "PREMIUM" 0 "BASE" ;
VAL_ 2047 GTW_plcSupportType 2 "NATIVE_CHARGE_PORT" 1 "ONBOARD_ADAPTER" 0 "NONE" ;
VAL_ 2047 GTW_packEnergy 2 "MR" 1 "LR" 0 "SR" ;
VAL_ 2047 GTW_frontSeatReclinerHardware 3 "LEFT_RIGHT_SEAT_REDUCED_RANGE" 2 "LEFT_SEAT_REDUCED_RANGE" 1 "RIGHT_SEAT_REDUCED_RANGE" 0 "STANDARD_RANGE" ;
VAL_ 2047 GTW_brakeLineSwitchType 1 "VC_ONLY" 0 "DI_VC_SHARED" ;
VAL_ 2047 GTW_espValveType 2 "VALVE_TYPE_2" 1 "VALVE_TYPE_1" 0 "UNKNOWN" ;
VAL_ 2047 GTW_softRange 4 "RANGE_260_MILES" 3 "RANGE_343_MILES" 2 "RANGE_93_MILES" 1 "RANGE_220_MILES" 0 "STANDARD" ;
VAL_ 2047 GTW_refrigerantType 2 "R1234YF" 1 "R134A" 0 "Default" ;
VAL_ 2047 GTW_wheelType 52 "UBERHELIX_20" 51 "GEMINI_19_DARK_STAGGERED" 50 "HELIX_V2_20_DARK" 48 "MACHINA_V2_19_STAGGERED" 47 "GLIDER_18_CAP_KIT" 46 "APERTURE_18" 41 "ARACHNID_V2_21" 40 "HELIX_V2_20" 39 "CROSSFLOW_19" 33 "WISHBONE_20_STAGGERED" 31 "HELIX_19" 30 "GLIDER_18" 27 "ZEROG_19_GUNPOWDER" 24 "PINWHEEL_REFRESH_18_CAP_KIT" 23 "UBERTURBINE_20_GUNPOWDER" 22 "PINWHEEL_REFRESH_18" 21 "STILETTO_REFRESH_19" 19 "ZEROG_20_GUNPOWDER" 18 "PINWHEEL_18_CAP_KIT" 14 "STILETTO_20_DARK_SQUARE" 5 "GEMINI_19_STAGGERED" 4 "GEMINI_19_SQUARE" 3 "STILETTO_20_DARK_STAGGERED" 2 "STILETTO_20" 1 "STILETTO_19" 0 "PINWHEEL_18" ;
VAL_ 2047 GTW_ptcControlMode 3 "SEQ_ROD_LIMITED" 2 "MESH_INSTALLED" 1 "SEQ_ROD" 0 "BASELINE" ;
VAL_ 2047 GTW_brakeActuationType 2 "ESP_DPB" 1 "IDB_RCU" 0 "ESP_IBST" ;
VAL_ 2047 GTW_secondRowSeatType 6 "TWO_SEATS_POWERED_RECLINE" 5 "FLAT_FOLD_V2" 4 "EASY_ENTRY_POWERED_RECLINE" 3 "POWERED_RECLINE" ;
VAL_ 2047 GTW_secondRowSeatMotorType 1 "KEIPER" 0 "SHB" ;
VAL_ 2047 GTW_eCallEnabled 2 "ENABLED_UI_SOS" 1 "ENABLED_OHC_SOS" 0 "DISABLED" ;
VAL_ 2047 GTW_parkAssistECUType 2 "NONE" 1 "TESLA" 0 "VALEO" ;
VAL_ 2047 GTW_passengerAirbagType 2 "EUROW" 1 "SAFETY_VENT" 0 "FULL_SUPPRESSION" ;
VAL_ 2047 GTW_forwardRadarHw 2 "NONE" 0 "CONTI_ARS410" ;
VAL_ 2047 GTW_frontSeatType 13 "PREMIUM_L_YANFENG_MINITILT_R_TESLA_MINITILT" 12 "PREMIUM_L_YANFENG_MINITILT_R_YANFENG_MINITILT" 11 "PREMIUM_L_YANFENG_MINITILT_R_YANFENG" 10 "PREMIUM_L_YANFENG_R_YANFENG_MINITILT" 9 "PREMIUM_L_TESLA_MINITILT_R_YANFENG_MINITILT" 8 "PREMIUM_L_TESLA_MINITILT_R_TESLA_MINITILT" 7 "PREMIUM_L_TESLA_MINITILT_R_TESLA" 6 "PREMIUM_L_TESLA_R_TESLA_MINITILT" 5 "PREMIUM_BROSE" 4 "PREMIUM_YANFENG" 3 "PREMIUM_L_TESLA_R_YANFENG" 2 "PREMIUM_L_YANFENG_R_TESLA" 1 "PREMIUM_TESLA" 0 "BASE_TESLA" ;
VAL_ 2047 GTW_secondRowDisplayType 1 "TYPE_1" 0 "NONE" ;
VAL_ 2047 GTW_wirelessPhoneChargerType 3 "FRONT_HIGH_POWER_UART" 1 "FRONT_LIN" 0 "NONE_OR_USB" ;
VAL_ 2047 GTW_ethernetTunerType 3 "HARMAN_GEN3" 2 "HIRSCHMANN" 1 "NONE" 0 "HARMAN" ;
VAL_ 2047 GTW_interiorTrimType 3 "WHITE_CONSOLE_2" 2 "BLACK_CONSOLE_2" 1 "WHITE" 0 "BLACK" ;
VAL_ 2047 GTW_gloveboxUSBType 2 "TSC_USB3_A_PLUS_BT" 1 "TSC_USB3_A" 0 "NOT_INSTALLED" ;
VAL_ 2047 GTW_coolantPumpType 5 "DUAL_MIX" 4 "DUAL_SAN_P4_LUB" 2 "DUAL_SAN_P4" 1 "SINGLE_PUMP_BATT" 0 "DUAL" ;
VAL_ 2047 GTW_epblHwType 8 "ZF" 5 "BREMBO_V2" 4 "BREMBO_V1" 2 "MANDO_V2" 1 "MANDO_V1" 0 "NOT_SET" ;
VAL_ 2047 GTW_epbrHwType 8 "ZF" 5 "BREMBO_V2" 4 "BREMBO_V1" 2 "MANDO_V2" 1 "MANDO_V1" 0 "NOT_SET" ;
VAL_ 2047 GTW_blowerMotorType 1 "DELTA" 0 "SHINANO" ;
VAL_ 2047 GTW_rearLeftBLEEndpointParameter 1 "VIVALDI_ANTENNA" 0 "NONE" ;
VAL_ 2047 GTW_frontUsbHubType 4 "NO_DATA" 0 "2" ;
VAL_ 2047 GTW_superManifoldType 2 "TYPE2" 1 "TYPE1" 0 "TYPE0" ;
VAL_ 2047 GTW_rcmLocation 0 "CENTER_CONSOLE" ;
VAL_ 2047 GTW_interiorCamFanType 3 "NIDEC" 2 "DELTA_FDB" 0 "NONE" ;
VAL_ 2047 GTW_interiorCamBeautyCoverType 2 "PITCHED_DOWN" 1 "PITCHED_UP" 0 "STANDARD" ;
VAL_ 2047 GTW_sirenType 1 "VODAPHONE_IF_INTRUSION" 0 "NONE" ;
VAL_ 2047 GTW_hornType 1 "EXT_SPEAKER_V2" 0 "TRUMPET" ;
VAL_ 2047 GTW_badgingVersion 1 "VERSION_1" 0 "VERSION_0" ;
VAL_ 2047 GTW_steeringColumnMotorType 3 "NEXTEER" 2 "BOSCH_COMMON_TO_JE" 1 "JE" 0 "BOSCH" ;
VAL_ 2047 GTW_refrigACLineType 2 "CONTI_LIMITED" 1 "SAAA_LIMITED" 0 "UNLIMITED" ;
VAL_ 2047 GTW_refrigFilterType 2 "BLOCKED_V2" 1 "BLOCKED_V1" 0 "UNBLOCKED" ;
VAL_ 2047 GTW_diBurnInType 1 "ENABLED_V1" 0 "NONE" ;
VAL_ 2047 GTW_specialBadgingType 2 "LAUNCH_SERIES" 0 "NONE" ;
VAL_ 2047 GTW_chassisSubType 3 "TRIM_DEVIATION_1" 2 "PERFORMANCE" 1 "BASE" 0 "UNKNOWN" ;
VAL_ 2047 GTW_frontSeatVentilationType 1 "TYPE_1" 0 "NONE" ;
VAL_ 2047 GTW_towPackage 2 "TESLA_REV2" 1 "TESLA_REV1" 0 "NONE" ;
VAL_ 2047 GTW_refrigLccType 1 "LCCR" 0 "LCC" ;
VAL_ 2047 GTW_caliperColorType 2 "RED" 1 "GREY" 0 "UNKNOWN" ;
VAL_ 2047 GTW_wiperMotorType 1 "SHB" 0 "NOT_UPDATEABLE" ;
VAL_ 2047 GTW_frontOverheadConsoleType 3 "KOSTAL" 2 "PREH" 1 "BITRON" 0 "VALEO" ;
VAL_ 2047 GTW_shifterType 1 "DISPLAY" 0 "STALK" ;
VAL_ 2047 GTW_compressorType 10 "SANDEN_V4_1" 8 "SANDEN_V4" 7 "SANDEN_V3" 6 "SANDEN_V1_1" 5 "SANDEN_V2" 4 "DENSO_11K_COP1_ENABLED" 3 "SANDEN" 2 "DENSO_41CC_11K" 1 "DENSO_41CC_8K" 0 "HANON_33CC" ;
VAL_ 2047 GTW_twelveVBatteryType 3 "TESLA_16V_LI_ION" 2 "CATL_LI_ION" 1 "CLARIOS_B24_FLOODED" 0 "ATLASBX_B24_FLOODED" ;
VAL_ 2047 GTW_efuseSWConfig 3 "ALL_ENABLED" 2 "SQUARE_ENABLED" 1 "ROUND_ENABLED" 0 "DISABLED" ;
VAL_ 2047 GTW_tollCollectionModuleType 1 "WANJI_V1" 0 "NONE" ;
VAL_ 2047 GTW_bleEndpointUpdateMethod 1 "BOOTLOADER_UPDATE" ;
VAL_ 2047 GTW_steeringWheelControllerType 5 "DUAL_TESLA_GEN5" 2 "DUAL_KOSTAL" 1 "DUAL_PREH" ;
VAL_ 2047 GTW_frontSeatVentilationEnabled 1 "ENABLED" 0 "DISABLED" ;
VAL_ 2047 GTW_gloveboxActuatorType 2 "ELECTROMAGNET" 1 "SMA" 0 "SOLENOID" ;
VAL_ 2047 GTW_epasType 8 "THYSSENKRUPP_CGR65" 7 "MANDO_CGR65" 6 "THYSSENKRUPP_VGR69" 5 "MANDO_CGR69_SINGLE_ECU" 4 "MANDO_CGR69" 3 "MANDO_VGR69_GEN3_SINGLE_ECU" 0 "MANDO_VGR69_GEN3" ;
VAL_ 2047 GTW_homologationRegionOverride 2 "MX_UNECE" 1 "KR_UNECE" 0 "DEFAULT_FOR_COUNTRY_CODE" ;
VAL_ 2047 GTW_windowCommandsPermissionType 2 "US_FMVSS_S6" 1 "US_FMVSS_S4" 0 "ROW_OR_US_FMVSS_S5" ;
VAL_ 2047 GTW_headlightStepperStallDetectM 1 "ENABLED" 0 "DISABLED" ;
VAL_ 2047 GTW_rgbInteriorLightingEnabled 2 "ALL_COLORS" 1 "WHITE_ONLY" 0 "DISABLED_OR_NA" ;
VAL_ 2047 GTW_windshieldWiperHeaterType 1 "TYPE_1" 0 "NOT_INSTALLED" ;
VAL_ 2047 GTW_driveInterfaceType 1 "EXTERNAL" 0 "COMBINED" ;
VAL_ 2047 GTW_efficiencyPackage 42 "MY_2026_US" 39 "MY_2025_CN_PLUS" 38 "MY_2026_M53" 34 "MY_STANDARD_2026" 33 "MY_REFRESH_2025_CN_ALL_US_LR_RWD" 32 "MY_REFRESH_2025_ROW" 24 "MY_2024_GFSH_EXPORT_NA_SR_RWD" 23 "MY_2024C" 20 "MY_2023_SR_RWD" 16 "MY_2024" 15 "MY_2023_GFSH_EXPORT_NA" 12 "MY_RWD_EU_2022" 11 "MY_SR_PLUS_2022_Q1_TX" 9 "MY_SR_PLUS_2021_Q3_GFSH" 7 "MY_2021" 5 "MY_2020" 0 "DEFAULT" ;
VAL_ 2047 GTW_visorLightType 1 "DIMMABLE_TYPE_1" 0 "NON_DIMMABLE" ;
VAL_ 2047 GTW_gnssAntennaType 2 "GEN2_WITH_METAL_INSERT" 1 "GEN2_NO_METAL_INSERT" 0 "NA_OR_GEN1" ;
VAL_ 2047 GTW_frontSeatHeatersEnabled 1 "ENABLED" 0 "DISABLED" ;
VAL_ 2047 GTW_windshieldWiperHeaterEnabled 1 "ENABLED_OR_NA" 0 "DISABLED" ;
VAL_ 2047 GTW_tcuType 1 "5G" 0 "4G" ;
VAL_ 2047 GTW_fasciaType 8 "E41_BAYBERRY" 4 "PERFORMANCE_BAYBERRY" 3 "BASE_BAYBERRY" 0 "ORIGINAL" ;
VAL_ 2047 GTW_powerSteeringColumn 1 "TK" 0 "NOT_INSTALLED" ;
VAL_ 2047 GTW_frontSeatHeaterType 1 "GENTHERM" 0 "KONGSBERG" ;
VAL_ 2047 GTW_softPerformanceLimit 6 "LIMIT_230_KW" 4 "LIMIT_110_MPH" 2 "LIMIT_110_KW" 1 "LIMIT_160_KW" 0 "NONE" ;
VAL_ 2047 GTW_alcoholInterlockType 1 "TYPE_1" 0 "NONE" ;
VAL_ 2047 GTW_immersiveAudio 2 "PREMIUM" 1 "BASE" 0 "DISABLED" ;
VAL_ 2047 GTW_passengerOccupancySensorType 4 "NONE" 1 "RESISTIVE_PAD" 0 "OCS" ;
VAL_ 2047 GTW_packPerformanceDeviation 5 "PACK_POWER_DEVIATION_2" 4 "PACK_MASS_DEVIATION_2" 3 "PACK_STRUCTURAL_DEVIATION_1" 2 "PACK_POWER_DEVIATION_1" 1 "PACK_MASS_DEVIATION_1" 0 "NO_DEVIATION" ;
VAL_ 2047 GTW_frontFogLamps 1 "INSTALLED" 0 "NOT_INSTALLED" ;
VAL_ 2047 GTW_driverOccupancySensorType 1 "NONE" 0 "RESISTIVE_PAD" ;
VAL_ 2047 GTW_audioType 4 "ESSENTIAL_WITH_COMMODITY100" 3 "ESSENTIAL" 1 "PREMIUM" 0 "BASE" ;
VAL_ 2047 GTW_occupancyClassificationFeatu 1 "TESLA_CABIN_RADAR" 0 "DISCRETE_SENSOR_OR_NA" ;
VAL_ 2047 GTW_domeLightType 2 "TESLA_2R" ;
VAL_ 2047 GTW_tpmsType 2 "INDIRECT" 1 "TESLA_BLE" 0 "CONTI_2" ;
VAL_ 2047 GTW_authenticationEndpointLayout 2 "MY_LAYOUT_2" 1 "M3_LAYOUT_2" 0 "LAYOUT_1" ;
VAL_ 2047 GTW_socSleepOverride 2 "FORCE_SHALLOW" 1 "FORCE_S3" 0 "PN_DERIVED" ;
VAL_ 2047 GTW_r79BehaviorOverride 1 "R79_ENABLED" 0 "NO_OVERRIDE" ;
VAL_ 2047 GTW_steeringHeaterType 7 "YF_V2" 4 "ZF_ROUND" 0 "NONE" ;
VAL_ 2047 GTW_sohRegulatoryStatus 1 "REGULATED_SOH" 0 "NON_REGULATED_SOH" ;
VAL_ 2047 GTW_m3yBusArchitecture 2 "PRIVATE_TORQUE_CHASSIS" 1 "PRIVATE_TORQUE" 0 "PUBLIC_TORQUE" ;
VAL_ 2047 GTW_blindSpotIndicatorLightType 1 "INSTALLED_TYPE_1" 0 "NOT_INSTALLED" ;
VAL_ 2047 GTW_hvacCaseDoorType 1 "FLAT_EDGE" 0 "SERRATED_EDGE" ;
VAL_ 2047 GTW_occupancyDetectionSourceRequ 1 "TESLA_CABIN_RADAR" 0 "DISCRETE_SENSOR_OR_NA" ;
VAL_ 2047 GTW_rduCableType 1 "COPPER" 0 "ALUMINUM" ;
VAL_ 2047 GTW_interiorCameraType 1 "VD6763" 0 "AR0136" ;
VAL_ 2047 GTW_frontFasciaCameraType 2 "IMX00N" 1 "IMX963" 0 "NONE" ;
VAL_ 1638 GTW_diagLevel 100 "LEVEL_NORMAL_OPERATION" 80 "LEVEL_PARK" 70 "LEVEL_PARK_ROBOTAXI" 50 "LEVEL_SERVICE_DRIVE" 25 "LEVEL_SERVICE" 10 "LEVEL_DIAG_LINK_ACTIVE" 0 "LEVEL_FACTORY" ;
VAL_ 1080 GTW_ethWakeUpReason 15 "GTW_WAKEUP_REASON_RCMPRIVATE_CAN" 14 "GTW_WAKEUP_REASON_VCLEFT" 13 "GTW_WAKEUP_REASON_LOOP" 12 "GTW_WAKEUP_REASON_DISPLAY_TAP" 11 "GTW_WAKEUP_REASON_URGENT_TRANSMIT_ALERT" 10 "GTW_WAKEUP_REASON_BDY_CAN" 9 "GTW_WAKEUP_REASON_PT_CAN" 8 "GTW_WAKEUP_REASON_UI_SCHEDULED" 7 "GTW_WAKEUP_REASON_RTC_ALARM" 6 "GTW_WAKEUP_REASON_VCFRONT" 5 "GTW_WAKEUP_REASON_VEH_CAN" 4 "GTW_WAKEUP_REASON_ETH_CAN" 3 "GTW_WAKEUP_REASON_CH_CAN" 2 "GTW_WAKEUP_REASON_GSM_RI" 1 "GTW_WAKEUP_REASON_RESET" 0 "GTW_WAKEUP_REASON_NONE" ;
VAL_ 1656 GTW_gearShiftRequest 4 "GEAR_REQUEST_DRIVE" 3 "GEAR_REQUEST_NEUTRAL" 2 "GEAR_REQUEST_REVERSE" 1 "GEAR_REQUEST_PARK" 0 "GEAR_REQUEST_IDLE_SNA" ;
VAL_ 1656 GTW_primaryGearControlStatus 14 "NOT_QUALIFIED_RHD_CONFIG_UNAVAILABLE" 13 "NOT_QUALIFIED_DISPLAY_KNOWN_FROZEN_SCREEN" 12 "NOT_QUALIFIED_DISPLAY_ASIL_VIDEO_ERROR" 11 "NOT_QUALIFIED_GEAR_STRIP_MISMATCH" 10 "NOT_QUALIFIED_DISPLAY_UNTRAINED" 9 "NOT_QUALIFIED_UI_NO_RESP_GEAR_STRIP" 8 "NOT_QUALIFIED_CENTER_DISP_UI_UNHEALTHY" 7 "NOT_QUALIFIED_DISPLAY_FROZEN_ON_GESTURE" 6 "NOT_QUALIFIED_LOW_BRIGHTNESS" 5 "NOT_QUALIFIED_FALSE_TOUCH" 4 "NOT_QUALIFIED_MANUAL" 3 "NOT_QUALIFIED_DISPLAY_ERRS" 2 "NOT_QUALIFIED_FULLSCREEN" 1 "QUALIFIED" 0 "NOT_QUALIFIED" ;
VAL_ 1656 GTW_autoParkRequest 1 "ACTIVE" 0 "IDLE" ;
VAL_ 1656 GTW_smartShiftStatus 9 "DISABLED_AUDIO_NOT_READY" 8 "DISABLED_OSD_ACTIVATED" 7 "DISABLED_DISQUALIFIED" 6 "DISABLED_FULLSCREEN" 5 "DISABLED_UI_MIA" 4 "DISABLED_CLUSTER_DISP_ERR" 3 "DISABLED_CENTER_DISP_ERR" 2 "DISABLED_UI_CONFIG" 1 "ENABLED" 0 "DISABLED_SNA" ;
VAL_ 1656 GTW_gearStripChangeReason 27 "EBUCK_DISABLE" 26 "SLEEP_DISABLE" 25 "VC_MIA_GRACE_DISABLE" 24 "VC_MIA_ENABLE" 23 "DRIVERLESS_NO_TAKEOVER_DISABLE" 22 "EMERGENCY_OPERATION_ENABLE" 21 "WOT_ENABLE" 20 "PARK_ENGAGED_ENABLE" 19 "MISSING_SPEED_OR_STEERING_ESTIMATE_IN_D_ENABLE" 18 "UI_MIA_ENABLE" 16 "NOT_DRIVE_STATE_DISABLE" 15 "FULLSCREEN_DISABLE" 14 "DEFAULT_DISABLE" 13 "REVERSE_ENABLE" 12 "NEUTRAL_ENABLE" 11 "P_AND_BRAKE_ENABLE" 10 "CHARGING_DISABLE" 9 "CRUISE_ACTIVE_DISABLE" 8 "DI_MIA_ENABLE" 7 "HIGH_ACCEL_DISABLE" 6 "MEDIUM_SPEED_DISABLE" 5 "TRAFFIC_CONTROL_NO_CHANGE" 4 "VERY_LOW_SPEED_ENABLE" 3 "HIGH_STEERING_ANGLE_ENABLE" 2 "HIGH_JERK_ENABLE" 1 "DRIVER_BRAKE_APPLY_ENABLE" 0 "SNA" ;
VAL_ 1656 GTW_screenPCBTemperature 2047 "GTW_I2C_TEMP_SNA" ;
VAL_ 2033 GTW_hrlIndex 2 "Mux2" 1 "Mux1" ;
VAL_ 2033 GTW_hrlState 1 "ENABLED" 0 "DISABLED" ;
VAL_ 2033 GTW_hrlTriggerType 15 "HRL_TRIGGER_NONE" 5 "HRL_TRIGGER_EVENT_EXTERNAL" 4 "HRL_TRIGGER_PSEUDONYMOUS" 3 "HRL_TRIGGER_CONTINUOUS" 2 "HRL_TRIGGER_GAME_MODE" 1 "HRL_TRIGGER_EVENT" 0 "HRL_TRIGGER_UDPAPI" ;
VAL_ 60 GTW_infoIndex 255 "END" 31 "SUBCOMPONENT_GITHASH" 30 "PACKAGE_SN_8_14" 29 "PACKAGE_SN_1_7" 27 "PACKAGE_PN_15_20" 26 "PACKAGE_PN_8_14" 25 "PACKAGE_PN_1_7" 23 "SUBCOMPONENT2" 22 "VARIANTCRC" 20 "UDS_PROTOCOL_BOOTCRC" 19 "VERSION_DEPRECATED" 18 "BOOTLOADER_GITHASH" 17 "APP_GITHASH" 16 "SUBCOMPONENT" 15 "BOOTLOADER_CRC" 14 "BOOTLOADER_SVN" 13 "APP_CRC" 11 "PCBAID_ASSYID_USAGEID" 10 "BUILD_HWID_COMPONENTID" 9 "DEPRECATED_9" 8 "DEPRECATED_8" 7 "DEPRECATED_7" 6 "DEPRECATED_6" 5 "DEPRECATED_5" 4 "DEPRECATED_4" 3 "DEPRECATED_3" 2 "DEPRECATED_2" 1 "DEPRECATED_1" 0 "DEPRECATED_0" ;
VAL_ 60 GTW_buildType 4 "INFO_MFG_BUILD" 3 "INFO_TRACEABLE_CI_BUILD" 2 "INFO_LOCAL_BUILD" 1 "INFO_PLATFORM_BUILD" 0 "INFO_UNKNOWN_BUILD" ;
VAL_ 60 GTW_platformType 255 "GTW_PLATFORM_END" 3 "GTW_PLATFORM_MODEL3" 0 "GTW_PLATFORM_UNKNOWN" ;
VAL_ 1370 GTW_mismatchFaultIndex 4 "Mux4" 3 "Mux3" 2 "Mux2" 1 "Mux1" ;
VAL_ 840 GTW_vehicleVersionMatchStatus 2 "MATCHED" 1 "MISMATCHED" 0 "NOT_CALCULATED_YET" ;
VAL_ 840 GTW_hwtype 3 "TRAVEO2" 2 "SPC58" 1 "MPC57" 0 "SNA" ;
VAL_ 840 GTW_jcanProductName 11 "SEMITRUCKV2" 10 "GOLDENSNITCH" 8 "BAYBERRY" 7 "CYBERTRUCK" 6 "POPPYSEED" 5 "SEMITRUCK" 4 "TAMARIND" 3 "LYCHEE" 2 "MODELY" 1 "MODEL3" 0 "SNA" ;
VAL_ 840 GTW_sentryModeState 6 "SNA" 5 "QUIET" 4 "PANIC" 3 "AWARE" 2 "ARMED" 1 "IDLE" 0 "OFF" ;
VAL_ 840 GTW_socSleepType 2 "SHALLOW" 1 "S3" 0 "SNA" ;
VAL_ 840 GTW_resetType 7 "TOUCHCORE_WATCHDOG" 6 "CANCORE_WATCHDOG" 5 "MAINCORE_WATCHDOG" 4 "WAKE" 3 "BUTTON" 2 "SOFTWARE" 1 "POR" 0 "SNA" ;
VAL_ 1112 GTW_nmKeepAwakeReason 15 "GTW_KEEPAWAKE_REASON_TBD" 7 "GTW_KEEPAWAKE_REASON_TCU_TC10_VERSION_UNSUPPORTED" 6 "GTW_KEEPAWAKE_REASON_TCU_TC10_VERSION_CHECK" 5 "GTW_KEEPAWAKE_REASON_EGGLEFT_LINK_DOWN" 4 "GTW_KEEPAWAKE_REASON_URGENT_TRANSMIT_ALERT" 3 "GTW_KEEPAWAKE_REASON_FCSM_ACTIVE" 2 "GTW_KEEPAWAKE_REASON_GSM_RI" 1 "GTW_KEEPAWAKE_REASON_UI_SCHEDULED" 0 "GTW_KEEPAWAKE_REASON_NONE_SNA" ;
VAL_ 1112 GTW_nmWakeUpReason 15 "GTW_WAKEUP_REASON_RCMPRIVATE_CAN" 14 "GTW_WAKEUP_REASON_VCLEFT" 13 "GTW_WAKEUP_REASON_LOOP" 12 "GTW_WAKEUP_REASON_DISPLAY_TAP" 11 "GTW_WAKEUP_REASON_URGENT_TRANSMIT_ALERT" 10 "GTW_WAKEUP_REASON_BDY_CAN" 9 "GTW_WAKEUP_REASON_PT_CAN" 8 "GTW_WAKEUP_REASON_UI_SCHEDULED" 7 "GTW_WAKEUP_REASON_RTC_ALARM" 6 "GTW_WAKEUP_REASON_VCFRONT" 5 "GTW_WAKEUP_REASON_VEH_CAN" 4 "GTW_WAKEUP_REASON_ETH_CAN" 3 "GTW_WAKEUP_REASON_CH_CAN" 2 "GTW_WAKEUP_REASON_GSM_RI" 1 "GTW_WAKEUP_REASON_RESET" 0 "GTW_WAKEUP_REASON_NONE" ;
VAL_ 1112 GTW_ethKeepAwakeReason 3 "TCU_TC10_VERSION_UNSUPPORTED" 2 "TCU_TC10_VERSION_CHECK" 1 "URGENT_TRANSMIT_ALERT" 0 "NONE_SNA" ;
VAL_ 1112 GTW_nmDebugWakeUp 2147483648 "WKPU_31" 1073741824 "WKPU_30" 536870912 "WKPU_29" 268435456 "WKPU_28" 134217728 "WKPU_27" 67108864 "WKPU_26" 33554432 "WKPU_25" 16777216 "WKPU_24" 8388608 "WKPU_23" 4194304 "WKPU_22" 2097152 "WKPU_21" 1048576 "WKPU_20" 524288 "WKPU_19" 262144 "WKPU_18" 131072 "WKPU_17" 65536 "WKPU_16" 32768 "WKPU_15" 16384 "WKPU_14" 8192 "WKPU_13" 4096 "WKPU_12" 2048 "WKPU_11" 1024 "WKPU_10" 512 "WKPU_9" 256 "WKPU_8" 128 "WKPU_7" 64 "WKPU_6" 32 "WKPU_5" 16 "WKPU_4" 8 "WKPU_3" 4 "WKPU_2" 2 "WKPU_1" 1 "WKPU_0" 0 "WKPU_NONE" ;
VAL_ 1290 HVP_alertID 68 "a068_shuntUnexpectedThermistor" 67 "a067_HvilCalNodeMismatch" 65 "a065_FastOpenVshDetected" 64 "a064_BmbAuxVRationality" 63 "a063_BmbBrickVRationality" 62 "a062_BmbOtpConfigError" 61 "a061_ShuntCurrentRationality" 60 "a060_StackVoltageSense" 59 "a059_BmbVrefWarning" 58 "a058_BmbVrefBad" 57 "a057_BatmanDiagnosticsError" 56 "a056_contactorFailedToOpen" 55 "a055_swMissingPartNumber" 54 "a054_swMissingConfigBlock" 53 "a053_hvVoltageSensorRationality" 52 "a052_BmbStatusRegError" 51 "a051_shuntThermistorMia" 50 "a050_fcCtrCloseFailed" 49 "a049_packCtrCloseFailed" 48 "a048_swUnsupportedBmbAsicType" 47 "a047_passivePyroDeploy" 46 "a046_shuntOverTemperature" 45 "a045_dcLinkOverVoltage" 44 "a044_fcContactorForceOpen" 43 "a043_packContactorForceOpen" 42 "a042_fcCtrCloseBlocked" 41 "a041_packCtrCloseBlocked" 40 "a040_FcContactorFellOpen" 39 "a039_PackContactorFellOpen" 38 "a038_CpilFault" 37 "a037_pyroFuseFailedToBlow" 36 "a036_pyroFuseBlown" 35 "a035_packContHwFault" 34 "a034_cpMismatchFault" 33 "a033_fcContHwFault" 32 "a032_ShuntHwAndBmsMiaFault" 31 "a031_packNegCtrArcFault" 30 "a030_PackPosCtrArcFault" 29 "a029_EnsMiaFault" 28 "a028_PackVoltMismatchFault" 27 "a027_BmsMiaOnHvsFault" 26 "a026_HvilFault" 25 "a025_VerSupplyFault" 24 "a024_Supply12vFault" 23 "a023_BmbResetRecovery" 22 "a022_PyroMiaWarning" 21 "a021_PyroMiaFault" 20 "a020_ShuntHwMiaFault" 19 "a019_CpFault" 18 "a018_powerCyclingPcs" 17 "a017_GtwMiaFault" 16 "a016_PcsMiaFault" 15 "a015_CpMiaFault" 14 "a014_BmsMiaOnHviFault" 13 "a013_BmbCommunication" 12 "a012_BmbDataIntegrityLoss" 11 "a011_PrimaryBmbMiaFault" 10 "a010_UnderVoltageFault" 9 "a009_OverVoltageFault" 8 "a008_OverTemperatureFault" 7 "a007_OverCurrentFault" 6 "a006_OverChargeCurrentFault" 5 "a005_OverDchgCurrentFault" 4 "a004_CrashEvent" 3 "a003_SwAssertion" 2 "a002_UnusedAlert2" 1 "a001_WatchdogReset" 0 "ALERT_DO_NOT_USE_ZERO" ;
VAL_ 1290 HVP_alertSet 1 "SET" 0 "CLEARED" ;
VAL_ 1290 HVP_a012_bmbCommStatusTypeA 3 "BYPASSED" 2 "NOMINAL" 1 "BAD" 0 "MISSING" ;
VAL_ 1290 HVP_a012_bmbCommStatusTypeB 3 "BYPASSED" 2 "NOMINAL" 1 "BAD" 0 "MISSING" ;
VAL_ 1290 HVP_a013_bmbCommStatusTypeA 3 "BYPASSED" 2 "NOMINAL" 1 "BAD" 0 "MISSING" ;
VAL_ 1290 HVP_a013_bmbCommStatusTypeB 3 "BYPASSED" 2 "NOMINAL" 1 "BAD" 0 "MISSING" ;
VAL_ 1290 HVP_a013_bmbChainBreakType 5 "TAIL_BREAK" 4 "HEAD_BREAK" 3 "INVALID_BREAK" 2 "DOUBLE_BREAK" 1 "SINGLE_BREAK" 0 "NONE" ;
VAL_ 1290 HVP_a020_energyReserveV 65535 "SNA" ;
VAL_ 1290 HVP_a020_shuntCurrentAux -32768 "SNA" ;
VAL_ 1290 HVP_a020_shuntTemperature -32768 "SNA" ;
VAL_ 1290 HVP_a021_pyroStatus 3 "ACTIVATED" 2 "FAULT" 1 "OK" 0 "UNKNOWN" ;
VAL_ 1290 HVP_a021_SquibResistance 65535 "SNA" ;
VAL_ 1290 HVP_a021_Aout 16383 "SNA" ;
VAL_ 1290 HVP_a022_pyroStatus 3 "ACTIVATED" 2 "FAULT" 1 "OK" 0 "UNKNOWN" ;
VAL_ 1290 HVP_a022_Aout 16383 "SNA" ;
VAL_ 1290 HVP_a022_SquibResistance 65535 "SNA" ;
VAL_ 1290 HVP_a026_hvilStatus 14 "SNA" 13 "PM_OPEN_FAULT" 12 "DI_OPEN_FAULT" 11 "PM_STATUS_MISSING_FAULT" 10 "DI_STATUS_MISSING_FAULT" 9 "VEHICLE_OR_PENTHOUSE_LID_OPEN_FAULT" 8 "NO_12V_SUPPLY" 7 "VEHICLE_NODE_FAULT" 6 "UNKNOWN_LOCATION_OPEN_FAULT" 5 "PENTHOUSE_LID_OPEN_FAULT" 4 "VEHICLE_OPEN_FAULT" 3 "INTERNAL_OPEN_FAULT" 2 "CURRENT_SOURCE_OR_GROUND_LEAK_FAULT" 1 "OK" 0 "UNKNOWN" ;
VAL_ 1290 HVP_a026_internalVoltage 255 "SNA" ;
VAL_ 1290 HVP_a026_dirVoltage 255 "SNA" ;
VAL_ 1290 HVP_a026_difVoltage 255 "SNA" ;
VAL_ 1290 HVP_a036_pyroFiringHandle 12 "PACK_NEGATIVE_CTR_ARC" 11 "PACK_POSITIVE_CTR_ARC" 10 "ENS_CRASH" 9 "SHUNT_MIA" 8 "OPEN_IMMEDIATELY" 7 "TEMPERATURE" 6 "UNDER_VOLTAGE" 5 "OVER_VOLTAGE" 4 "OVER_CURRENT" 3 "OVER_CHARGE_CURRENT" 2 "OVER_DISCHARGE_CURRENT" 1 "HVP" ;
VAL_ 1290 HVP_a037_pyroFiringHandle 12 "PACK_NEGATIVE_CTR_ARC" 11 "PACK_POSITIVE_CTR_ARC" 10 "ENS_CRASH" 9 "SHUNT_MIA" 8 "OPEN_IMMEDIATELY" 7 "TEMPERATURE" 6 "UNDER_VOLTAGE" 5 "OVER_VOLTAGE" 4 "OVER_CURRENT" 3 "OVER_CHARGE_CURRENT" 2 "OVER_DISCHARGE_CURRENT" 1 "HVP" ;
VAL_ 1290 HVP_a049_posCtrState 7 "WELDED" 6 "ECONOMIZED" 5 "OPENING" 4 "PULLED_IN" 3 "BLOCKED" 2 "PRECHARGE" 1 "OPEN" 0 "SNA" ;
VAL_ 1290 HVP_a049_negCtrState 7 "WELDED" 6 "ECONOMIZED" 5 "OPENING" 4 "PULLED_IN" 3 "BLOCKED" 2 "PRECHARGE" 1 "OPEN" 0 "SNA" ;
VAL_ 1290 HVP_a050_posCtrState 7 "WELDED" 6 "ECONOMIZED" 5 "OPENING" 4 "PULLED_IN" 3 "BLOCKED" 2 "PRECHARGE" 1 "OPEN" 0 "SNA" ;
VAL_ 1290 HVP_a050_negCtrState 7 "WELDED" 6 "ECONOMIZED" 5 "OPENING" 4 "PULLED_IN" 3 "BLOCKED" 2 "PRECHARGE" 1 "OPEN" 0 "SNA" ;
VAL_ 1290 HVP_a051_shuntTemperature -32768 "SNA" ;
VAL_ 1290 HVP_a051_shuntCurrent -32768 "SNA" ;
VAL_ 1290 HVP_a051_energyReserveV 65535 "SNA" ;
VAL_ 1290 HVP_a052_regErrorType 162 "FAULT_COMM1_BY_UART_TR" 161 "FAULT_COMM1_BY_UART_RR" 160 "FAULT_COMM1_BY_COMMCLR_DET" 159 "FAULT_COMM1_BY_STOP_DET" 158 "FAULT_COMM2_BY_COML_TR" 157 "FAULT_COMM2_BY_COML_RR" 156 "FAULT_COMM2_BY_COML_RC" 155 "FAULT_COMM2_BY_COML_BIT" 154 "FAULT_COMM2_BY_COMH_TR" 153 "FAULT_COMM2_BY_COMH_RR" 152 "FAULT_COMM2_BY_COMH_RC" 151 "FAULT_COMM2_BY_COMH_BIT" 150 "FAULT_COMM3_BY_FCOMM_DET" 149 "FAULT_COMM3_BY_FTONE_DET" 148 "FAULT_COMM3_BY_HB_FAIL" 147 "FAULT_COMM3_BY_HB_FAST" 146 "FAULT_OTP_BY_DED_DET" 145 "FAULT_OTP_BY_SEC_DET" 144 "FAULT_OTP_BY_CUST_CRC" 143 "FAULT_OTP_BY_FACT_CRC" 142 "FAULT_OTP_BY_CUSTLDERR" 141 "FAULT_OTP_BY_FACTLDERR" 140 "FAULT_OTP_BY_GBLOVERR" 139 "FAULT_SYS_BY_LFO" 138 "FAULT_SYS_BY_SHUTDOWN_REC" 137 "FAULT_SYS_BY_GPIO" 136 "FAULT_SYS_BY_DRST" 135 "FAULT_SYS_BY_CTL" 134 "FAULT_SYS_BY_CTS" 133 "FAULT_SYS_BY_TSHUT" 132 "FAULT_SYS_BY_TWARN" 131 "FAULT_COMP_GPIO_BY_GPIO8_FAIL" 130 "FAULT_COMP_GPIO_BY_GPIO7_FAIL" 129 "FAULT_COMP_GPIO_BY_GPIO6_FAIL" 128 "FAULT_COMP_GPIO_BY_GPIO5_FAIL" 127 "FAULT_COMP_GPIO_BY_GPIO4_FAIL" 126 "FAULT_COMP_GPIO_BY_GPIO3_FAIL" 125 "FAULT_COMP_GPIO_BY_GPIO2_FAIL" 124 "FAULT_COMP_GPIO_BY_GPIO1_FAIL" 123 "FAULT_COMP_VCCB1_BY_CELL16_FAIL" 122 "FAULT_COMP_VCCB1_BY_CELL15_FAIL" 121 "FAULT_COMP_VCCB1_BY_CELL14_FAIL" 120 "FAULT_COMP_VCCB1_BY_CELL13_FAIL" 119 "FAULT_COMP_VCCB1_BY_CELL12_FAIL" 118 "FAULT_COMP_VCCB1_BY_CELL11_FAIL" 117 "FAULT_COMP_VCCB1_BY_CELL10_FAIL" 116 "FAULT_COMP_VCCB1_BY_CELL9_FAIL" 115 "FAULT_COMP_VCCB2_BY_CELL8_FAIL" 114 "FAULT_COMP_VCCB2_BY_CELL7_FAIL" 113 "FAULT_COMP_VCCB2_BY_CELL6_FAIL" 112 "FAULT_COMP_VCCB2_BY_CELL5_FAIL" 111 "FAULT_COMP_VCCB2_BY_CELL4_FAIL" 110 "FAULT_COMP_VCCB2_BY_CELL3_FAIL" 109 "FAULT_COMP_VCCB2_BY_CELL2_FAIL" 108 "FAULT_COMP_VCCB2_BY_CELL1_FAIL" 107 "FAULT_COMP_VCOW1_BY_VCOW16_FAIL" 106 "FAULT_COMP_VCOW1_BY_VCOW15_FAIL" 105 "FAULT_COMP_VCOW1_BY_VCOW14_FAIL" 104 "FAULT_COMP_VCOW1_BY_VCOW13_FAIL" 103 "FAULT_COMP_VCOW1_BY_VCOW12_FAIL" 102 "FAULT_COMP_VCOW1_BY_VCOW11_FAIL" 101 "FAULT_COMP_VCOW1_BY_VCOW10_FAIL" 100 "FAULT_COMP_VCOW1_BY_VCOW9_FAIL" 99 "FAULT_COMP_VCOW2_BY_VCOW8_FAIL" 98 "FAULT_COMP_VCOW2_BY_VCOW7_FAIL" 97 "FAULT_COMP_VCOW2_BY_VCOW6_FAIL" 96 "FAULT_COMP_VCOW2_BY_VCOW5_FAIL" 95 "FAULT_COMP_VCOW2_BY_VCOW4_FAIL" 94 "FAULT_COMP_VCOW2_BY_VCOW3_FAIL" 93 "FAULT_COMP_VCOW2_BY_VCOW2_FAIL" 92 "FAULT_COMP_VCOW2_BY_VCOW1_FAIL" 91 "FAULT_COMP_CBOW1_BY_CBOW16_FAIL" 90 "FAULT_COMP_CBOW1_BY_CBOW15_FAIL" 89 "FAULT_COMP_CBOW1_BY_CBOW14_FAIL" 88 "FAULT_COMP_CBOW1_BY_CBOW13_FAIL" 87 "FAULT_COMP_CBOW1_BY_CBOW12_FAIL" 86 "FAULT_COMP_CBOW1_BY_CBOW11_FAIL" 85 "FAULT_COMP_CBOW1_BY_CBOW10_FAIL" 84 "FAULT_COMP_CBOW1_BY_CBOW9_FAIL" 83 "FAULT_COMP_CBOW2_BY_CBOW8_FAIL" 82 "FAULT_COMP_CBOW2_BY_CBOW7_FAIL" 81 "FAULT_COMP_CBOW2_BY_CBOW6_FAIL" 80 "FAULT_COMP_CBOW2_BY_CBOW5_FAIL" 79 "FAULT_COMP_CBOW2_BY_CBOW4_FAIL" 78 "FAULT_COMP_CBOW2_BY_CBOW3_FAIL" 77 "FAULT_COMP_CBOW2_BY_CBOW2_FAIL" 76 "FAULT_COMP_CBOW2_BY_CBOW1_FAIL" 75 "FAULT_COMP_CBFET1_BY_CBFET16_FAIL" 74 "FAULT_COMP_CBFET1_BY_CBFET15_FAIL" 73 "FAULT_COMP_CBFET1_BY_CBFET14_FAIL" 72 "FAULT_COMP_CBFET1_BY_CBFET13_FAIL" 71 "FAULT_COMP_CBFET1_BY_CBFET12_FAIL" 70 "FAULT_COMP_CBFET1_BY_CBFET11_FAIL" 69 "FAULT_COMP_CBFET1_BY_CBFET10_FAIL" 68 "FAULT_COMP_CBFET1_BY_CBFET9_FAIL" 67 "FAULT_COMP_CBFET2_BY_CBFET8_FAIL" 66 "FAULT_COMP_CBFET2_BY_CBFET7_FAIL" 65 "FAULT_COMP_CBFET2_BY_CBFET6_FAIL" 64 "FAULT_COMP_CBFET2_BY_CBFET5_FAIL" 63 "FAULT_COMP_CBFET2_BY_CBFET4_FAIL" 62 "FAULT_COMP_CBFET2_BY_CBFET3_FAIL" 61 "FAULT_COMP_CBFET2_BY_CBFET2_FAIL" 60 "FAULT_COMP_CBFET2_BY_CBFET1_FAIL" 59 "FAULT_COMP_MISC_BY_COMP_ADC_ABORT" 58 "FAULT_COMP_MISC_BY_LPF_FAIL" 57 "FAULT_PWR1_BY_CVSS_OPEN" 56 "FAULT_PWR1_BY_DVSS_OPEN" 55 "FAULT_PWR1_BY_REFHM_OPEN" 54 "FAULT_PWR1_BY_CVDD_UV" 53 "FAULT_PWR1_BY_CVDD_OV" 52 "FAULT_PWR1_BY_DVDD_OV" 51 "FAULT_PWR1_BY_AVDD_OSC" 50 "FAULT_PWR1_BY_AVDD_OV" 49 "FAULT_PWR2_BY_PWRBIST_FAIL" 48 "FAULT_PWR2_BY_REFH_OSC" 47 "FAULT_PWR2_BY_NEG5V_UV" 46 "FAULT_PWR2_BY_TSREF_OSC" 45 "FAULT_PWR2_BY_TSREF_UV" 44 "FAULT_PWR2_BY_TSREF_OV" 43 "FAULT_PWR3_BY_AVDDUV_DRST" 42 "SEQ_ERROR_FAULT_CLEAR" 41 "SEQ_ERROR_FAULT_INJECT" 40 "SEQ_ERROR_CELL_RESUME" 39 "SEQ_ERROR_CELL_FREEZE" 38 "SEQ_ERROR_AUX_RESET" 37 "SEQ_ERROR_AUX_CLEAR" 36 "TEST_MODE" 35 "SUPPLY_RAIL" 34 "CLK_CHECK" 33 "DIGITAL_REF_OV" 32 "DIGITAL_REF_UV" 31 "ANALOG_REF_OV" 30 "ANALOG_REF_UV" 29 "POWER_BIST" 28 "GPIO_COMP" 27 "CBOW_COMP" 26 "VCOW_COMP" 25 "VCCB_COMP" 24 "VBG2_PLAUS" 23 "REFL_PLAUS" 22 "TSREF_PLAUS" 21 "VCM1_PLAUS" 20 "THERM_PLAUS" 19 "DIETEMP_PLAUS" 18 "STACKV_PLAUS" 17 "BRICKV_PLAUS" 16 "ADC_COMP_ABORT" 15 "LPF_FAULT_DET" 14 "AUX_MISC_DRDY" 13 "AUX_GPIO_DRDY" 12 "AUX_VCELL_DRDY" 11 "MAIN_ADC_DRDY" 10 "MAIN_ADC_LPF" 9 "POWER_FAULT" 8 "SYSTEM_FAULT" 7 "COMM_FAULT" 6 "OTP_FAULT" 5 "ADC_COMP_FAULT" 4 "ERROR_OTP_FAULT" 3 "ERROR_OTP_WARNING" 2 "ERROR_ADC_SEQUENCE" 1 "ERROR_POWER_RESET" 0 "ERROR_NONE" ;
VAL_ 1290 HVP_a056_diagnosis 2 "PACK_CONTACTOR_WELDED" 1 "HIGH_SHUNT_CURRENT" 0 "SHUNT_CURRENT_SNA" ;
VAL_ 1290 HVP_a056_posPackContactorState 7 "WELDED" 6 "ECONOMIZED" 5 "OPENING" 4 "PULLED_IN" 3 "BLOCKED" 2 "PRECHARGE" 1 "OPEN" 0 "SNA" ;
VAL_ 1290 HVP_a056_negPackContactorState 7 "WELDED" 6 "ECONOMIZED" 5 "OPENING" 4 "PULLED_IN" 3 "BLOCKED" 2 "PRECHARGE" 1 "OPEN" 0 "SNA" ;
VAL_ 1290 HVP_a056_posFcContactorState 7 "WELDED" 6 "ECONOMIZED" 5 "OPENING" 4 "PULLED_IN" 3 "BLOCKED" 2 "PRECHARGE" 1 "OPEN" 0 "SNA" ;
VAL_ 1290 HVP_a056_negFcContactorState 7 "WELDED" 6 "ECONOMIZED" 5 "OPENING" 4 "PULLED_IN" 3 "BLOCKED" 2 "PRECHARGE" 1 "OPEN" 0 "SNA" ;
VAL_ 1290 HVP_a058_VrefStatus 3 "BYPASSED" 2 "NOMINAL" 1 "BAD" 0 "MISSING" ;
VAL_ 1290 HVP_a058_VrefType 2 "REF2" 1 "V3" 0 "V5" ;
VAL_ 1290 HVP_a067_hvilTypeFromHvp 2 "CAN" 1 "LV" 0 "UNKNOWN" ;
VAL_ 1290 HVP_a067_hvilTypeFromGateway 2 "CAN" 1 "LV" 0 "UNKNOWN" ;
VAL_ 1290 HVP_a068_shuntTemperature -32768 "SNA" ;
VAL_ 1290 HVP_a068_shuntCurrent -32768 "SNA" ;
VAL_ 1290 HVP_a068_energyReserveV 65535 "SNA" ;
